VERSION ""

NS_ :

BS_:

BU_:

BO_ 2566565374 HVESP9CFG: 19 Vector__XXX
 SG_ Hvesp9NominalVoltage : 0|16@1+ (0.05,0) [0|3212.75] "V" Vector__XXX
 SG_ Hvesp9CellMaximumVoltageLimit : 112|8@1+ (0.02044,0) [0|5.11] "V" Vector__XXX
 SG_ Hvesp9CellMinimumVoltageLimit : 120|8@1+ (0.02044,0) [0|5.11] "V" Vector__XXX
 SG_ Hvsp9RmmnddMnmmOprtngVltg : 16|16@1+ (0.05,0) [0|3212.75] "V" Vector__XXX
 SG_ Hvsp9RmmnddMxmmOprtngVltg : 32|16@1+ (0.05,0) [0|3212.75] "V" Vector__XXX
 SG_ Hvsp9RmmnddMnmmSttOfChrg : 48|16@1+ (0.0015625,0) [0|100.3984375] "%" Vector__XXX
 SG_ Hvsp9RmmnddMxmmSttOfChrg : 64|16@1+ (0.0015625,0) [0|100.3984375] "%" Vector__XXX
 SG_ Hvsp9RmmnddMxmmOprtngTmprtr : 80|16@1+ (0.03125,-273) [-273|1734.96875] "degC" Vector__XXX
 SG_ Hvsp9RmmnddMnmmOprtngTmprtr : 96|16@1+ (0.03125,-273) [-273|1734.96875] "degC" Vector__XXX

BO_ 2633674494 HVESP9HIST: 19 Vector__XXX
 SG_ Hvesp9StateOfHealth : 0|8@1+ (0.4,0) [0|100] "%" Vector__XXX
 SG_ Hvesp9TotalEnergyThroughput : 24|32@1+ (100,0) [0|421108121500] "Watt-hour" Vector__XXX
 SG_ Hvesp9TotalAccumulatedCharge : 56|32@1+ (100,0) [0|421108121500] "Ah" Vector__XXX
 SG_ Hvesp9TotalLifetimeEnergyInput : 88|32@1+ (1,0) [0|4211081215] "kWh" Vector__XXX
 SG_ Hvesp9TotalLifetimeEnergyOutput : 120|32@1+ (1,0) [0|4211081215] "kWh" Vector__XXX
 SG_ Hvsp9CnttrOpnUndrLdCnt : 8|16@1+ (1,0) [0|64255] "count" Vector__XXX

BO_ 2566565886 HVESP8CFG: 19 Vector__XXX
 SG_ Hvesp8NominalVoltage : 0|16@1+ (0.05,0) [0|3212.75] "V" Vector__XXX
 SG_ Hvesp8CellMaximumVoltageLimit : 112|8@1+ (0.02044,0) [0|5.11] "V" Vector__XXX
 SG_ Hvesp8CellMinimumVoltageLimit : 120|8@1+ (0.02044,0) [0|5.11] "V" Vector__XXX
 SG_ Hvsp8RmmnddMnmmOprtngVltg : 16|16@1+ (0.05,0) [0|3212.75] "V" Vector__XXX
 SG_ Hvsp8RmmnddMxmmOprtngVltg : 32|16@1+ (0.05,0) [0|3212.75] "V" Vector__XXX
 SG_ Hvsp8RmmnddMnmmSttOfChrg : 48|16@1+ (0.0015625,0) [0|100.3984375] "%" Vector__XXX
 SG_ Hvsp8RmmnddMxmmSttOfChrg : 64|16@1+ (0.0015625,0) [0|100.3984375] "%" Vector__XXX
 SG_ Hvsp8RmmnddMxmmOprtngTmprtr : 80|16@1+ (0.03125,-273) [-273|1734.96875] "degC" Vector__XXX
 SG_ Hvsp8RmmnddMnmmOprtngTmprtr : 96|16@1+ (0.03125,-273) [-273|1734.96875] "degC" Vector__XXX

BO_ 2633675006 HVESP8HIST: 19 Vector__XXX
 SG_ Hvesp8StateOfHealth : 0|8@1+ (0.4,0) [0|100] "%" Vector__XXX
 SG_ Hvesp8TotalEnergyThroughput : 24|32@1+ (100,0) [0|421108121500] "Watt-hour" Vector__XXX
 SG_ Hvesp8TotalAccumulatedCharge : 56|32@1+ (100,0) [0|421108121500] "Ah" Vector__XXX
 SG_ Hvesp8TotalLifetimeEnergyInput : 88|32@1+ (1,0) [0|4211081215] "kWh" Vector__XXX
 SG_ Hvesp8TotalLifetimeEnergyOutput : 120|32@1+ (1,0) [0|4211081215] "kWh" Vector__XXX
 SG_ Hvsp8CnttrOpnUndrLdCnt : 8|16@1+ (1,0) [0|64255] "count" Vector__XXX

BO_ 2566566398 HVESP7CFG: 19 Vector__XXX
 SG_ Hvesp7NominalVoltage : 0|16@1+ (0.05,0) [0|3212.75] "V" Vector__XXX
 SG_ Hvesp7CellMaximumVoltageLimit : 112|8@1+ (0.02044,0) [0|5.11] "V" Vector__XXX
 SG_ Hvesp7CellMinimumVoltageLimit : 120|8@1+ (0.02044,0) [0|5.11] "V" Vector__XXX
 SG_ Hvsp7RmmnddMnmmOprtngVltg : 16|16@1+ (0.05,0) [0|3212.75] "V" Vector__XXX
 SG_ Hvsp7RmmnddMxmmOprtngVltg : 32|16@1+ (0.05,0) [0|3212.75] "V" Vector__XXX
 SG_ Hvsp7RmmnddMnmmSttOfChrg : 48|16@1+ (0.0015625,0) [0|100.3984375] "%" Vector__XXX
 SG_ Hvsp7RmmnddMxmmSttOfChrg : 64|16@1+ (0.0015625,0) [0|100.3984375] "%" Vector__XXX
 SG_ Hvsp7RmmnddMxmmOprtngTmprtr : 80|16@1+ (0.03125,-273) [-273|1734.96875] "degC" Vector__XXX
 SG_ Hvsp7RmmnddMnmmOprtngTmprtr : 96|16@1+ (0.03125,-273) [-273|1734.96875] "degC" Vector__XXX

BO_ 2633675518 HVESP7HIST: 19 Vector__XXX
 SG_ Hvesp7StateOfHealth : 0|8@1+ (0.4,0) [0|100] "%" Vector__XXX
 SG_ Hvesp7TotalEnergyThroughput : 24|32@1+ (100,0) [0|421108121500] "Watt-hour" Vector__XXX
 SG_ Hvesp7TotalAccumulatedCharge : 56|32@1+ (100,0) [0|421108121500] "Ah" Vector__XXX
 SG_ Hvesp7TotalLifetimeEnergyInput : 88|32@1+ (1,0) [0|4211081215] "kWh" Vector__XXX
 SG_ Hvesp7TotalLifetimeEnergyOutput : 120|32@1+ (1,0) [0|4211081215] "kWh" Vector__XXX
 SG_ Hvsp7CnttrOpnUndrLdCnt : 8|16@1+ (1,0) [0|64255] "count" Vector__XXX

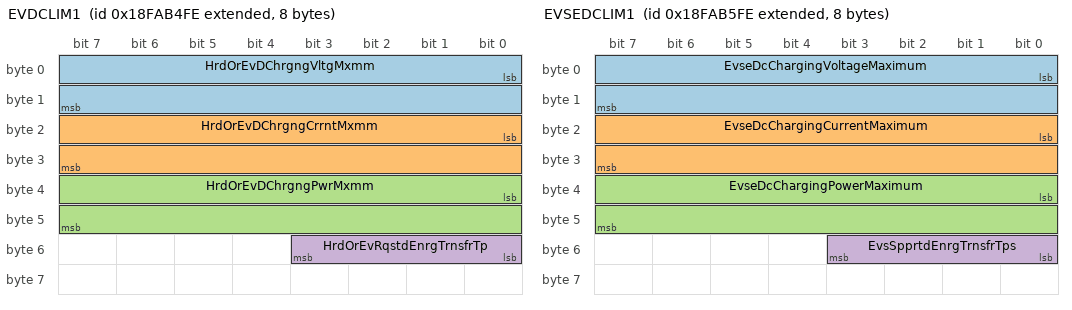
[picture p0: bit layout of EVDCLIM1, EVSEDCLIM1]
BO_ 2566567166 EVDCLIM1: 8 Vector__XXX
 SG_ HrdOrEvDChrgngVltgMxmm : 0|16@1+ (0.05,0) [0|3212.75] "V" Vector__XXX
 SG_ HrdOrEvDChrgngCrrntMxmm : 16|16@1+ (0.0625,0) [0|4015.9375] "A" Vector__XXX
 SG_ HrdOrEvDChrgngPwrMxmm : 32|16@1+ (0.05,0) [0|3212.75] "kW" Vector__XXX
 SG_ HrdOrEvRqstdEnrgTrnsfrTp : 48|4@1+ (1,0) [0|15] "" Vector__XXX

BO_ 2566567422 EVSEDCLIM1: 8 Vector__XXX
 SG_ EvseDcChargingVoltageMaximum : 0|16@1+ (0.05,0) [0|3212.75] "V" Vector__XXX
 SG_ EvseDcChargingCurrentMaximum : 16|16@1+ (0.0625,0) [0|4015.9375] "A" Vector__XXX
 SG_ EvseDcChargingPowerMaximum : 32|16@1+ (0.05,0) [0|3212.75] "kW" Vector__XXX
 SG_ EvsSpprtdEnrgTrnsfrTps : 48|4@1+ (1,0) [0|15] "" Vector__XXX

BO_ 2566567678 EVSEDCLIM2: 8 Vector__XXX
 SG_ EvseDcChargingVoltageMinimum : 0|16@1+ (0.05,0) [0|3212.75] "V" Vector__XXX
 SG_ EvseDcChargingCurrentMinimum : 16|16@1+ (0.0625,0) [0|4015.9375] "A" Vector__XXX
 SG_ EvsePeakCurrentRipple : 32|16@1+ (0.0625,0) [0|4015.9375] "A" Vector__XXX
 SG_ EvseCurrentRegulationTolerance : 48|16@1+ (0.0625,0) [0|4015.9375] "A" Vector__XXX

BO_ 2566567934 EVDCTGT: 8 Vector__XXX
 SG_ DcChargingTargetCrc : 0|8@1+ (1,0) [0|250] "count" Vector__XXX
 SG_ DcChargingTargetSequenceCounter : 8|4@1+ (1,0) [0|15] "" Vector__XXX
 SG_ DcTargetChargingVoltage : 16|16@1+ (0.05,0) [0|3212.75] "V" Vector__XXX
 SG_ DcTargetChargingCurrent : 32|16@1+ (0.0625,0) [0|4015.9375] "A" Vector__XXX

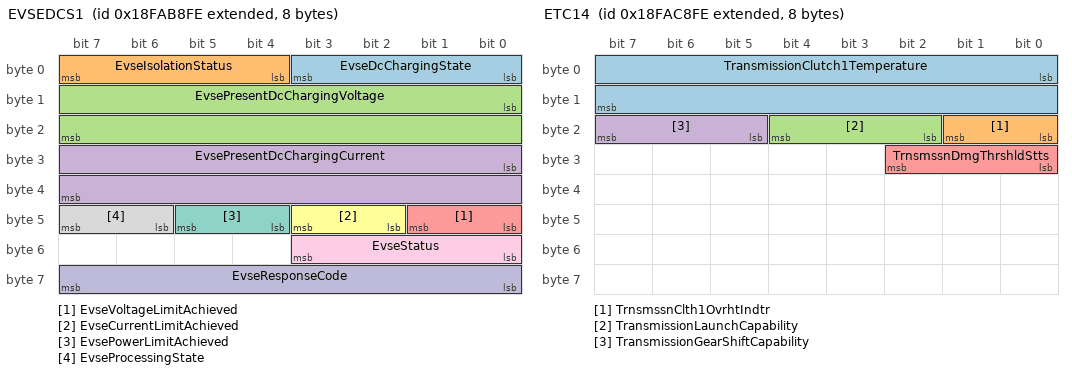
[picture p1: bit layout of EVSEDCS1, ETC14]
BO_ 2566568190 EVSEDCS1: 8 Vector__XXX
 SG_ EvseDcChargingState : 0|4@1+ (1,0) [0|15] "" Vector__XXX
 SG_ EvseIsolationStatus : 4|4@1+ (1,0) [0|15] "" Vector__XXX
 SG_ EvsePresentDcChargingVoltage : 8|16@1+ (0.05,0) [0|3212.75] "V" Vector__XXX
 SG_ EvsePresentDcChargingCurrent : 24|16@1+ (0.05,-1600) [-1600|1612.75] "A" Vector__XXX
 SG_ EvseVoltageLimitAchieved : 40|2@1+ (1,0) [0|3] "" Vector__XXX
 SG_ EvseCurrentLimitAchieved : 42|2@1+ (1,0) [0|3] "" Vector__XXX
 SG_ EvsePowerLimitAchieved : 44|2@1+ (1,0) [0|3] "" Vector__XXX
 SG_ EvseProcessingState : 46|2@1+ (1,0) [0|3] "" Vector__XXX
 SG_ EvseStatus : 48|4@1+ (1,0) [0|15] "" Vector__XXX
 SG_ EvseResponseCode : 56|8@1+ (1,0) [0|250] "" Vector__XXX

BO_ 2566568446 EVSE1CC1: 8 Vector__XXX
 SG_ HrdOrEvDInltCnttr1Cmmnd : 0|2@1+ (1,0) [0|3] "" Vector__XXX

BO_ 2566568702 EVSE1CS1: 8 Vector__XXX
 SG_ HrdOrEvDCnttrInptVltg : 0|16@1+ (0.05,0) [0|3212.75] "V" Vector__XXX
 SG_ HybridOrEvDcChargingBusVoltage : 16|16@1+ (0.05,0) [0|3212.75] "V" Vector__XXX
 SG_ HrdOrEvDInltCnttr1Stt : 32|2@1+ (1,0) [0|3] "" Vector__XXX

BO_ 2566568958 DLCC3: 8 Vector__XXX
 SG_ TrnsmssnOlTmprtrHghLmpCmmnd : 0|2@1+ (1,0) [0|3] "" Vector__XXX
 SG_ TrnsmssnOlPrssrLwLmpCmmnd : 2|2@1+ (1,0) [0|3] "" Vector__XXX

BO_ 2566569214 DLCD3: 8 Vector__XXX
 SG_ TrnsmssnOlTmprtrHghLmpDt : 0|2@1+ (1,0) [0|3] "" Vector__XXX
 SG_ TrnsmssnOlPrssrLwLmpDt : 2|2@1+ (1,0) [0|3] "" Vector__XXX

BO_ 2566569470 MG1LD: 16 Vector__XXX
 SG_ MtrGnrtr1TtlEnrgCnsmd : 0|32@1+ (100,0) [0|421108121500] "Watt-hour" Vector__XXX
 SG_ MtrGnrtr1TtlEnrgGnrtd : 32|32@1+ (100,0) [0|421108121500] "Watt-hour" Vector__XXX
 SG_ MtrGnrtr1TtlChrgCnsmd : 64|32@1+ (100,0) [0|421108121500] "Ah" Vector__XXX
 SG_ MtrGnrtr1TtlChrgGnrtd : 96|32@1+ (100,0) [0|421108121500] "Ah" Vector__XXX

BO_ 2566569726 MG2LD: 16 Vector__XXX
 SG_ MtrGnrtr2TtlEnrgCnsmd : 0|32@1+ (100,0) [0|421108121500] "Watt-hour" Vector__XXX
 SG_ MtrGnrtr2TtlEnrgGnrtd : 32|32@1+ (100,0) [0|421108121500] "Watt-hour" Vector__XXX
 SG_ MtrGnrtr2TtlChrgCnsmd : 64|32@1+ (100,0) [0|421108121500] "Ah" Vector__XXX
 SG_ MtrGnrtr2TtlChrgGnrtd : 96|32@1+ (100,0) [0|421108121500] "Ah" Vector__XXX

BO_ 2566569982 MG3LD: 16 Vector__XXX
 SG_ MtrGnrtr3TtlEnrgCnsmd : 0|32@1+ (100,0) [0|421108121500] "Watt-hour" Vector__XXX
 SG_ MtrGnrtr3TtlEnrgGnrtd : 32|32@1+ (100,0) [0|421108121500] "Watt-hour" Vector__XXX
 SG_ MtrGnrtr3TtlChrgCnsmd : 64|32@1+ (100,0) [0|421108121500] "Ah" Vector__XXX
 SG_ MtrGnrtr3TtlChrgGnrtd : 96|32@1+ (100,0) [0|421108121500] "Ah" Vector__XXX

BO_ 2566570238 MG4LD: 16 Vector__XXX
 SG_ MtrGnrtr4TtlEnrgCnsmd : 0|32@1+ (100,0) [0|421108121500] "Watt-hour" Vector__XXX
 SG_ MtrGnrtr4TtlEnrgGnrtd : 32|32@1+ (100,0) [0|421108121500] "Watt-hour" Vector__XXX
 SG_ MtrGnrtr4TtlChrgCnsmd : 64|32@1+ (100,0) [0|421108121500] "Ah" Vector__XXX
 SG_ MtrGnrtr4TtlChrgGnrtd : 96|32@1+ (100,0) [0|421108121500] "Ah" Vector__XXX

BO_ 2566570494 MG5LD: 16 Vector__XXX
 SG_ MtrGnrtr5TtlEnrgCnsmd : 0|32@1+ (100,0) [0|421108121500] "Watt-hour" Vector__XXX
 SG_ MtrGnrtr5TtlEnrgGnrtd : 32|32@1+ (100,0) [0|421108121500] "Watt-hour" Vector__XXX
 SG_ MtrGnrtr5TtlChrgCnsmd : 64|32@1+ (100,0) [0|421108121500] "Ah" Vector__XXX
 SG_ MtrGnrtr5TtlChrgGnrtd : 96|32@1+ (100,0) [0|421108121500] "Ah" Vector__XXX

BO_ 2566570750 MG6LD: 16 Vector__XXX
 SG_ MtrGnrtr6TtlEnrgCnsmd : 0|32@1+ (100,0) [0|421108121500] "Watt-hour" Vector__XXX
 SG_ MtrGnrtr6TtlEnrgGnrtd : 32|32@1+ (100,0) [0|421108121500] "Watt-hour" Vector__XXX
 SG_ MtrGnrtr6TtlChrgCnsmd : 64|32@1+ (100,0) [0|421108121500] "Ah" Vector__XXX
 SG_ MtrGnrtr6TtlChrgGnrtd : 96|32@1+ (100,0) [0|421108121500] "Ah" Vector__XXX

BO_ 2566571006 AIR3: 8 Vector__XXX
 SG_ AirDryerCartridgeLifeRemaining : 0|8@1+ (0.4,0) [0|100] "%" Vector__XXX
 SG_ AirSuspensionSupplyPressure2 : 8|8@1+ (8,0) [0|2000] "kPa" Vector__XXX

BO_ 2566571262 EVSEACSV: 8 Vector__XXX
 SG_ EvseNominalRmsVoltageLineToLine : 16|16@1+ (0.05,0) [0|3212.75] "V" Vector__XXX
 SG_ EvseNominalSupplyFrequency : 32|8@1+ (1,0) [0|250] "" Vector__XXX
 SG_ EvsNmnlRmsVltgLnTNtrl : 0|16@1+ (0.05,0) [0|3212.75] "V" Vector__XXX

BO_ 2566571518 EVSEAC3PL: 8 Vector__XXX
 SG_ HvessChargerRmsCurrentL1 : 0|16@1+ (0.0625,0) [0|4015.9375] "A" Vector__XXX
 SG_ HvessChargerRmsCurrentL2 : 16|16@1+ (0.0625,0) [0|4015.9375] "A" Vector__XXX
 SG_ HvessChargerRmsCurrentL3 : 32|16@1+ (0.0625,0) [0|4015.9375] "A" Vector__XXX
 SG_ HvessChargerNeutralRmsCurrent : 48|16@1+ (0.0625,0) [0|4015.9375] "A" Vector__XXX

BO_ 2499462910 ERC3: 8 Vector__XXX
 SG_ RtrdrRdSpdDlrtSwth : 0|2@1+ (1,0) [0|3] "" Vector__XXX
 SG_ RtrdrRdSpdAlrtSwth : 2|2@1+ (1,0) [0|3] "" Vector__XXX

BO_ 2566572286 ETC14: 8 Vector__XXX
 SG_ TransmissionClutch1Temperature : 0|16@1+ (0.03125,-273) [-273|1734.96875] "degC" Vector__XXX
 SG_ TrnsmssnClth1OvrhtIndtr : 16|2@1+ (1,0) [0|3] "" Vector__XXX
 SG_ TransmissionLaunchCapability : 18|3@1+ (1,0) [0|7] "" Vector__XXX
 SG_ TransmissionGearShiftCapability : 21|3@1+ (1,0) [0|7] "" Vector__XXX
 SG_ TrnsmssnDmgThrshldStts : 24|3@1+ (1,0) [0|7] "" Vector__XXX

BO_ 2499464702 A1SCREGP2: 8 Vector__XXX
 SG_ Aftrtrtmnt1SrOtltAsltPrssr : 0|16@1+ (0.1,0) [0|6425.5] "kPa" Vector__XXX
 SG_ Aftrtrtmnt1SrOtltPrssr : 16|16@1+ (0.1,0) [0|6425.5] "kPa" Vector__XXX

BO_ 2566573822 PTO2: 8 Vector__XXX
 SG_ TransmissionPtoGearboxStatus : 16|4@1+ (1,0) [0|15] "" Vector__XXX
 SG_ TrnsmssnPtGrxOtptShftSpd : 0|16@1+ (0.125,0) [0|8031.875] "rpm" Vector__XXX

BO_ 2364690686 EATC1: 8 Vector__XXX
 SG_ AxlrTrnsmssnOtptSpd : 0|16@1+ (0.125,0) [0|8031.875] "rpm" Vector__XXX

BO_ 2566563326 DFM3: 8 Vector__XXX
 SG_ BddDFMdEsttdIsttsFSvsRt : 0|16@1+ (0.05,0) [0|3212.75] "l/h" Vector__XXX
 SG_ BlnddDlFlMdOprtngStts : 16|4@1+ (1,0) [0|15] "" Vector__XXX
 SG_ BlendedDualFuelModeStatusReason : 24|8@1+ (1,0) [0|250] "" Vector__XXX

BO_ 2566563582 DFM2: 8 Vector__XXX
 SG_ BlnddDlFlMdTtlDslFlDmnd : 32|32@1+ (0.5,0) [0|2105540607.5] "l" Vector__XXX
 SG_ BlnddDlFlMdTtlDslFlDspldBGssFl : 0|32@1+ (0.5,0) [0|2105540607.5] "l" Vector__XXX

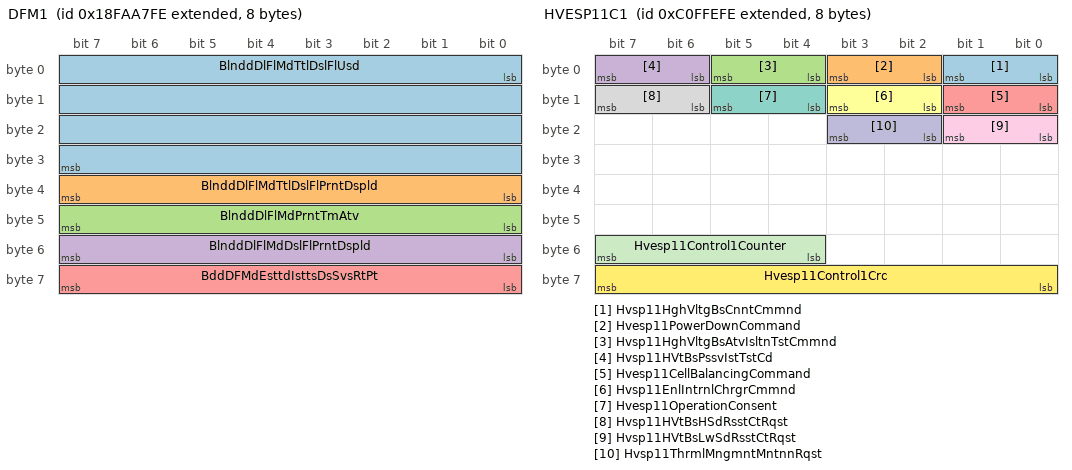
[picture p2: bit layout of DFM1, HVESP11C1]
BO_ 2566563838 DFM1: 8 Vector__XXX
 SG_ BlnddDlFlMdTtlDslFlUsd : 0|32@1+ (0.5,0) [0|2105540607.5] "l" Vector__XXX
 SG_ BlnddDlFlMdTtlDslFlPrntDspld : 32|8@1+ (0.5,0) [0|125] "%" Vector__XXX
 SG_ BlnddDlFlMdPrntTmAtv : 40|8@1+ (0.4,0) [0|100] "%" Vector__XXX
 SG_ BlnddDlFlMdDslFlPrntDspld : 48|8@1+ (0.4,0) [0|100] "%" Vector__XXX
 SG_ BddDFMdEsttdIsttsDsSvsRtPt : 56|8@1+ (0.4,0) [0|100] "%" Vector__XXX

BO_ 2566564094 T1HIST: 12 Vector__XXX
 SG_ Trnsmssn1TtlOtptShftRvltns : 32|32@1+ (1000,0) [0|4211081215000] "r" Vector__XXX
 SG_ Trnsmssn1OprtnTmSnRld : 64|32@1+ (1,0) [0|4211081215] "s" Vector__XXX
 SG_ Trnsmssn1TtlHrsOfOprtn : 0|32@1+ (1,0) [0|4211081215] "s" Vector__XXX

BO_ 2566564350 TSTI: 8 Vector__XXX
 SG_ Trnsmssn1InptShftPkTwst : 0|8@1+ (0.1,-12.5) [-12.5|12.5] "deg" Vector__XXX
 SG_ Trnsmssn1OtptShftPkTwst : 8|8@1+ (0.1,-12.5) [-12.5|12.5] "deg" Vector__XXX
 SG_ Trnsmssn1IntrmdtShftPkTwst : 16|8@1+ (0.1,-12.5) [-12.5|12.5] "deg" Vector__XXX

BO_ 2566564606 EATC2: 8 Vector__XXX
 SG_ AxlrTrnsmssnSltdGr : 0|8@1+ (1,-125) [-125|125] "gear value" Vector__XXX
 SG_ AxlrTrnsmssnCrrntGr : 8|8@1+ (1,-125) [-125|125] "gear value" Vector__XXX

BO_ 2349858558 HVESP11C1: 8 Vector__XXX
 SG_ Hvsp11HghVltgBsCnntCmmnd : 0|2@1+ (1,0) [0|3] "" Vector__XXX
 SG_ Hvesp11PowerDownCommand : 2|2@1+ (1,0) [0|3] "" Vector__XXX
 SG_ Hvsp11HghVltgBsAtvIsltnTstCmmnd : 4|2@1+ (1,0) [0|3] "" Vector__XXX
 SG_ Hvsp11HVtBsPssvIstTstCd : 6|2@1+ (1,0) [0|3] "" Vector__XXX
 SG_ Hvesp11CellBalancingCommand : 8|2@1+ (1,0) [0|3] "" Vector__XXX
 SG_ Hvsp11EnlIntrnlChrgrCmmnd : 10|2@1+ (1,0) [0|3] "" Vector__XXX
 SG_ Hvesp11OperationConsent : 12|2@1+ (1,0) [0|3] "" Vector__XXX
 SG_ Hvsp11HVtBsHSdRsstCtRqst : 14|2@1+ (1,0) [0|3] "" Vector__XXX
 SG_ Hvsp11HVtBsLwSdRsstCtRqst : 16|2@1+ (1,0) [0|3] "" Vector__XXX
 SG_ Hvsp11ThrmlMngmntMntnnRqst : 18|2@1+ (1,0) [0|3] "" Vector__XXX
 SG_ Hvesp11Control1Counter : 52|4@1+ (1,0) [0|15] "" Vector__XXX
 SG_ Hvesp11Control1Crc : 56|8@1+ (1,0) [0|250] "count" Vector__XXX

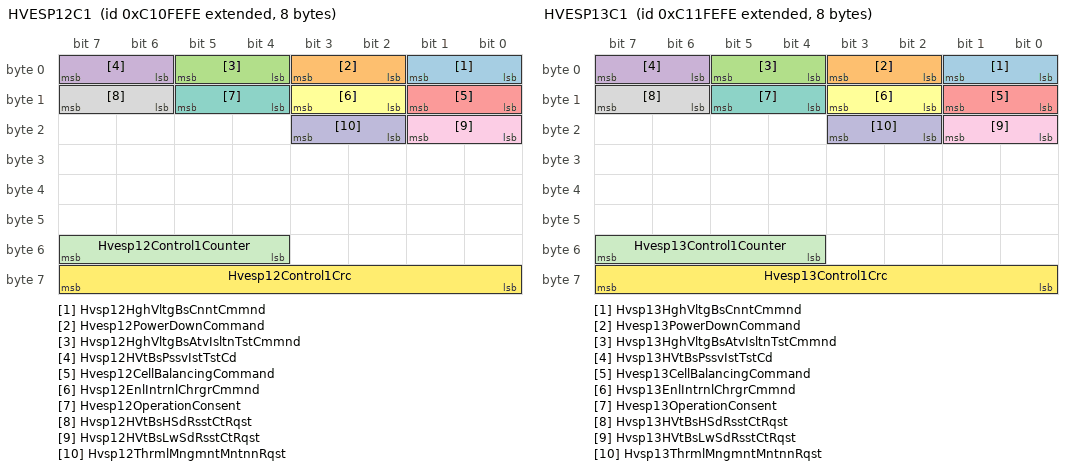
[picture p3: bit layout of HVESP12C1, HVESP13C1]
BO_ 2349924094 HVESP12C1: 8 Vector__XXX
 SG_ Hvsp12HghVltgBsCnntCmmnd : 0|2@1+ (1,0) [0|3] "" Vector__XXX
 SG_ Hvesp12PowerDownCommand : 2|2@1+ (1,0) [0|3] "" Vector__XXX
 SG_ Hvsp12HghVltgBsAtvIsltnTstCmmnd : 4|2@1+ (1,0) [0|3] "" Vector__XXX
 SG_ Hvsp12HVtBsPssvIstTstCd : 6|2@1+ (1,0) [0|3] "" Vector__XXX
 SG_ Hvesp12CellBalancingCommand : 8|2@1+ (1,0) [0|3] "" Vector__XXX
 SG_ Hvsp12EnlIntrnlChrgrCmmnd : 10|2@1+ (1,0) [0|3] "" Vector__XXX
 SG_ Hvesp12OperationConsent : 12|2@1+ (1,0) [0|3] "" Vector__XXX
 SG_ Hvsp12HVtBsHSdRsstCtRqst : 14|2@1+ (1,0) [0|3] "" Vector__XXX
 SG_ Hvsp12HVtBsLwSdRsstCtRqst : 16|2@1+ (1,0) [0|3] "" Vector__XXX
 SG_ Hvsp12ThrmlMngmntMntnnRqst : 18|2@1+ (1,0) [0|3] "" Vector__XXX
 SG_ Hvesp12Control1Counter : 52|4@1+ (1,0) [0|15] "" Vector__XXX
 SG_ Hvesp12Control1Crc : 56|8@1+ (1,0) [0|250] "count" Vector__XXX

BO_ 2349989630 HVESP13C1: 8 Vector__XXX
 SG_ Hvsp13HghVltgBsCnntCmmnd : 0|2@1+ (1,0) [0|3] "" Vector__XXX
 SG_ Hvesp13PowerDownCommand : 2|2@1+ (1,0) [0|3] "" Vector__XXX
 SG_ Hvsp13HghVltgBsAtvIsltnTstCmmnd : 4|2@1+ (1,0) [0|3] "" Vector__XXX
 SG_ Hvsp13HVtBsPssvIstTstCd : 6|2@1+ (1,0) [0|3] "" Vector__XXX
 SG_ Hvesp13CellBalancingCommand : 8|2@1+ (1,0) [0|3] "" Vector__XXX
 SG_ Hvsp13EnlIntrnlChrgrCmmnd : 10|2@1+ (1,0) [0|3] "" Vector__XXX
 SG_ Hvesp13OperationConsent : 12|2@1+ (1,0) [0|3] "" Vector__XXX
 SG_ Hvsp13HVtBsHSdRsstCtRqst : 14|2@1+ (1,0) [0|3] "" Vector__XXX
 SG_ Hvsp13HVtBsLwSdRsstCtRqst : 16|2@1+ (1,0) [0|3] "" Vector__XXX
 SG_ Hvsp13ThrmlMngmntMntnnRqst : 18|2@1+ (1,0) [0|3] "" Vector__XXX
 SG_ Hvesp13Control1Counter : 52|4@1+ (1,0) [0|15] "" Vector__XXX
 SG_ Hvesp13Control1Crc : 56|8@1+ (1,0) [0|250] "count" Vector__XXX

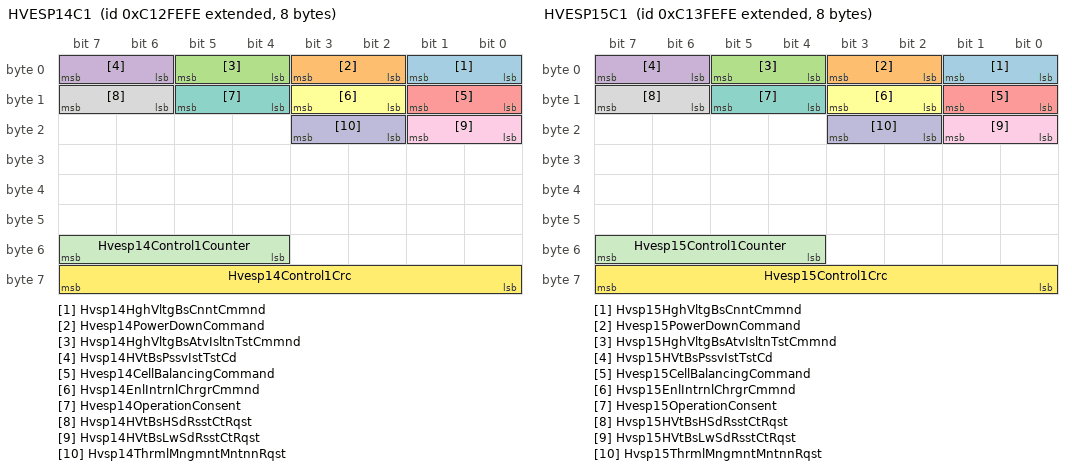
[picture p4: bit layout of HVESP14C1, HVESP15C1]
BO_ 2350055166 HVESP14C1: 8 Vector__XXX
 SG_ Hvsp14HghVltgBsCnntCmmnd : 0|2@1+ (1,0) [0|3] "" Vector__XXX
 SG_ Hvesp14PowerDownCommand : 2|2@1+ (1,0) [0|3] "" Vector__XXX
 SG_ Hvsp14HghVltgBsAtvIsltnTstCmmnd : 4|2@1+ (1,0) [0|3] "" Vector__XXX
 SG_ Hvsp14HVtBsPssvIstTstCd : 6|2@1+ (1,0) [0|3] "" Vector__XXX
 SG_ Hvesp14CellBalancingCommand : 8|2@1+ (1,0) [0|3] "" Vector__XXX
 SG_ Hvsp14EnlIntrnlChrgrCmmnd : 10|2@1+ (1,0) [0|3] "" Vector__XXX
 SG_ Hvesp14OperationConsent : 12|2@1+ (1,0) [0|3] "" Vector__XXX
 SG_ Hvsp14HVtBsHSdRsstCtRqst : 14|2@1+ (1,0) [0|3] "" Vector__XXX
 SG_ Hvsp14HVtBsLwSdRsstCtRqst : 16|2@1+ (1,0) [0|3] "" Vector__XXX
 SG_ Hvsp14ThrmlMngmntMntnnRqst : 18|2@1+ (1,0) [0|3] "" Vector__XXX
 SG_ Hvesp14Control1Counter : 52|4@1+ (1,0) [0|15] "" Vector__XXX
 SG_ Hvesp14Control1Crc : 56|8@1+ (1,0) [0|250] "count" Vector__XXX

BO_ 2350120702 HVESP15C1: 8 Vector__XXX
 SG_ Hvsp15HghVltgBsCnntCmmnd : 0|2@1+ (1,0) [0|3] "" Vector__XXX
 SG_ Hvesp15PowerDownCommand : 2|2@1+ (1,0) [0|3] "" Vector__XXX
 SG_ Hvsp15HghVltgBsAtvIsltnTstCmmnd : 4|2@1+ (1,0) [0|3] "" Vector__XXX
 SG_ Hvsp15HVtBsPssvIstTstCd : 6|2@1+ (1,0) [0|3] "" Vector__XXX
 SG_ Hvesp15CellBalancingCommand : 8|2@1+ (1,0) [0|3] "" Vector__XXX
 SG_ Hvsp15EnlIntrnlChrgrCmmnd : 10|2@1+ (1,0) [0|3] "" Vector__XXX
 SG_ Hvesp15OperationConsent : 12|2@1+ (1,0) [0|3] "" Vector__XXX
 SG_ Hvsp15HVtBsHSdRsstCtRqst : 14|2@1+ (1,0) [0|3] "" Vector__XXX
 SG_ Hvsp15HVtBsLwSdRsstCtRqst : 16|2@1+ (1,0) [0|3] "" Vector__XXX
 SG_ Hvsp15ThrmlMngmntMntnnRqst : 18|2@1+ (1,0) [0|3] "" Vector__XXX
 SG_ Hvesp15Control1Counter : 52|4@1+ (1,0) [0|15] "" Vector__XXX
 SG_ Hvesp15Control1Crc : 56|8@1+ (1,0) [0|250] "count" Vector__XXX

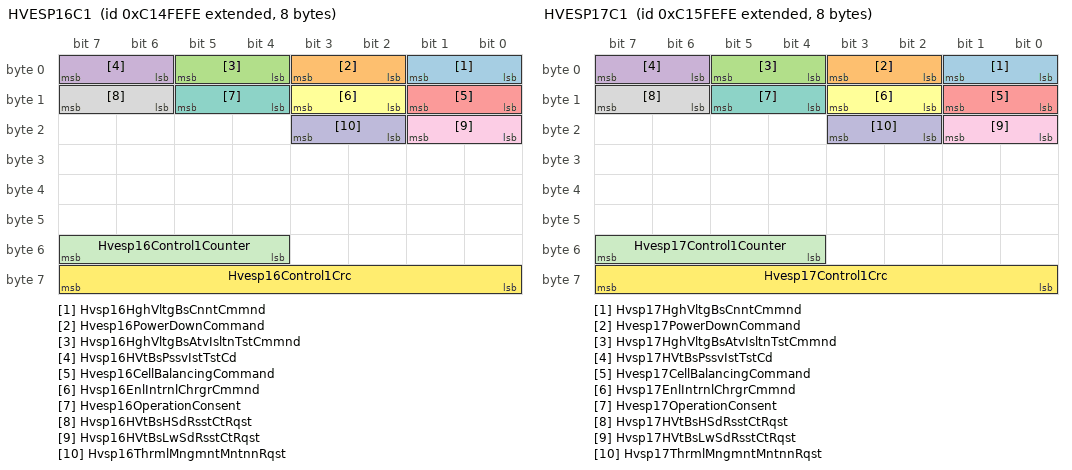
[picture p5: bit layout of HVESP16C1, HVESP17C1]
BO_ 2350186238 HVESP16C1: 8 Vector__XXX
 SG_ Hvsp16HghVltgBsCnntCmmnd : 0|2@1+ (1,0) [0|3] "" Vector__XXX
 SG_ Hvesp16PowerDownCommand : 2|2@1+ (1,0) [0|3] "" Vector__XXX
 SG_ Hvsp16HghVltgBsAtvIsltnTstCmmnd : 4|2@1+ (1,0) [0|3] "" Vector__XXX
 SG_ Hvsp16HVtBsPssvIstTstCd : 6|2@1+ (1,0) [0|3] "" Vector__XXX
 SG_ Hvesp16CellBalancingCommand : 8|2@1+ (1,0) [0|3] "" Vector__XXX
 SG_ Hvsp16EnlIntrnlChrgrCmmnd : 10|2@1+ (1,0) [0|3] "" Vector__XXX
 SG_ Hvesp16OperationConsent : 12|2@1+ (1,0) [0|3] "" Vector__XXX
 SG_ Hvsp16HVtBsHSdRsstCtRqst : 14|2@1+ (1,0) [0|3] "" Vector__XXX
 SG_ Hvsp16HVtBsLwSdRsstCtRqst : 16|2@1+ (1,0) [0|3] "" Vector__XXX
 SG_ Hvsp16ThrmlMngmntMntnnRqst : 18|2@1+ (1,0) [0|3] "" Vector__XXX
 SG_ Hvesp16Control1Counter : 52|4@1+ (1,0) [0|15] "" Vector__XXX
 SG_ Hvesp16Control1Crc : 56|8@1+ (1,0) [0|250] "count" Vector__XXX

BO_ 2350251774 HVESP17C1: 8 Vector__XXX
 SG_ Hvsp17HghVltgBsCnntCmmnd : 0|2@1+ (1,0) [0|3] "" Vector__XXX
 SG_ Hvesp17PowerDownCommand : 2|2@1+ (1,0) [0|3] "" Vector__XXX
 SG_ Hvsp17HghVltgBsAtvIsltnTstCmmnd : 4|2@1+ (1,0) [0|3] "" Vector__XXX
 SG_ Hvsp17HVtBsPssvIstTstCd : 6|2@1+ (1,0) [0|3] "" Vector__XXX
 SG_ Hvesp17CellBalancingCommand : 8|2@1+ (1,0) [0|3] "" Vector__XXX
 SG_ Hvsp17EnlIntrnlChrgrCmmnd : 10|2@1+ (1,0) [0|3] "" Vector__XXX
 SG_ Hvesp17OperationConsent : 12|2@1+ (1,0) [0|3] "" Vector__XXX
 SG_ Hvsp17HVtBsHSdRsstCtRqst : 14|2@1+ (1,0) [0|3] "" Vector__XXX
 SG_ Hvsp17HVtBsLwSdRsstCtRqst : 16|2@1+ (1,0) [0|3] "" Vector__XXX
 SG_ Hvsp17ThrmlMngmntMntnnRqst : 18|2@1+ (1,0) [0|3] "" Vector__XXX
 SG_ Hvesp17Control1Counter : 52|4@1+ (1,0) [0|15] "" Vector__XXX
 SG_ Hvesp17Control1Crc : 56|8@1+ (1,0) [0|250] "count" Vector__XXX

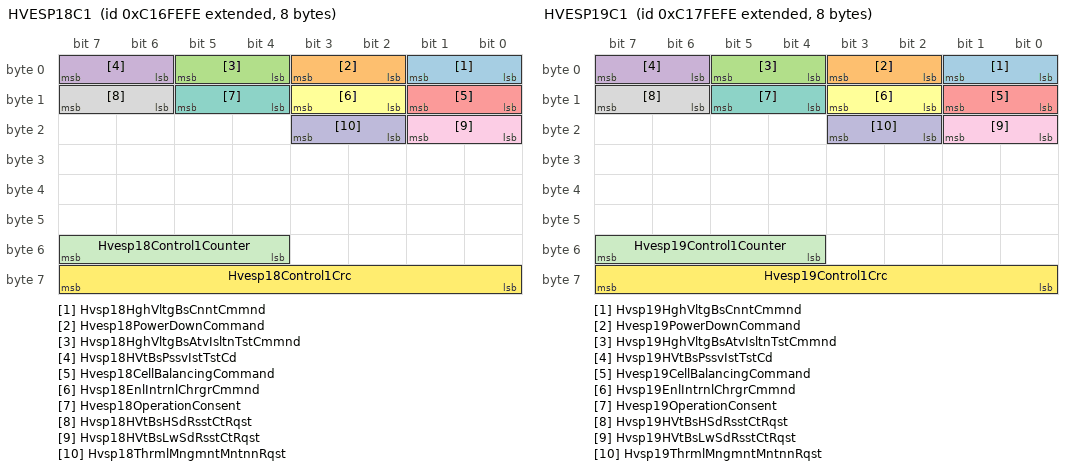
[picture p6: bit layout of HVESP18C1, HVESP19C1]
BO_ 2350317310 HVESP18C1: 8 Vector__XXX
 SG_ Hvsp18HghVltgBsCnntCmmnd : 0|2@1+ (1,0) [0|3] "" Vector__XXX
 SG_ Hvesp18PowerDownCommand : 2|2@1+ (1,0) [0|3] "" Vector__XXX
 SG_ Hvsp18HghVltgBsAtvIsltnTstCmmnd : 4|2@1+ (1,0) [0|3] "" Vector__XXX
 SG_ Hvsp18HVtBsPssvIstTstCd : 6|2@1+ (1,0) [0|3] "" Vector__XXX
 SG_ Hvesp18CellBalancingCommand : 8|2@1+ (1,0) [0|3] "" Vector__XXX
 SG_ Hvsp18EnlIntrnlChrgrCmmnd : 10|2@1+ (1,0) [0|3] "" Vector__XXX
 SG_ Hvesp18OperationConsent : 12|2@1+ (1,0) [0|3] "" Vector__XXX
 SG_ Hvsp18HVtBsHSdRsstCtRqst : 14|2@1+ (1,0) [0|3] "" Vector__XXX
 SG_ Hvsp18HVtBsLwSdRsstCtRqst : 16|2@1+ (1,0) [0|3] "" Vector__XXX
 SG_ Hvsp18ThrmlMngmntMntnnRqst : 18|2@1+ (1,0) [0|3] "" Vector__XXX
 SG_ Hvesp18Control1Counter : 52|4@1+ (1,0) [0|15] "" Vector__XXX
 SG_ Hvesp18Control1Crc : 56|8@1+ (1,0) [0|250] "count" Vector__XXX

BO_ 2350382846 HVESP19C1: 8 Vector__XXX
 SG_ Hvsp19HghVltgBsCnntCmmnd : 0|2@1+ (1,0) [0|3] "" Vector__XXX
 SG_ Hvesp19PowerDownCommand : 2|2@1+ (1,0) [0|3] "" Vector__XXX
 SG_ Hvsp19HghVltgBsAtvIsltnTstCmmnd : 4|2@1+ (1,0) [0|3] "" Vector__XXX
 SG_ Hvsp19HVtBsPssvIstTstCd : 6|2@1+ (1,0) [0|3] "" Vector__XXX
 SG_ Hvesp19CellBalancingCommand : 8|2@1+ (1,0) [0|3] "" Vector__XXX
 SG_ Hvsp19EnlIntrnlChrgrCmmnd : 10|2@1+ (1,0) [0|3] "" Vector__XXX
 SG_ Hvesp19OperationConsent : 12|2@1+ (1,0) [0|3] "" Vector__XXX
 SG_ Hvsp19HVtBsHSdRsstCtRqst : 14|2@1+ (1,0) [0|3] "" Vector__XXX
 SG_ Hvsp19HVtBsLwSdRsstCtRqst : 16|2@1+ (1,0) [0|3] "" Vector__XXX
 SG_ Hvsp19ThrmlMngmntMntnnRqst : 18|2@1+ (1,0) [0|3] "" Vector__XXX
 SG_ Hvesp19Control1Counter : 52|4@1+ (1,0) [0|15] "" Vector__XXX
 SG_ Hvesp19Control1Crc : 56|8@1+ (1,0) [0|250] "count" Vector__XXX

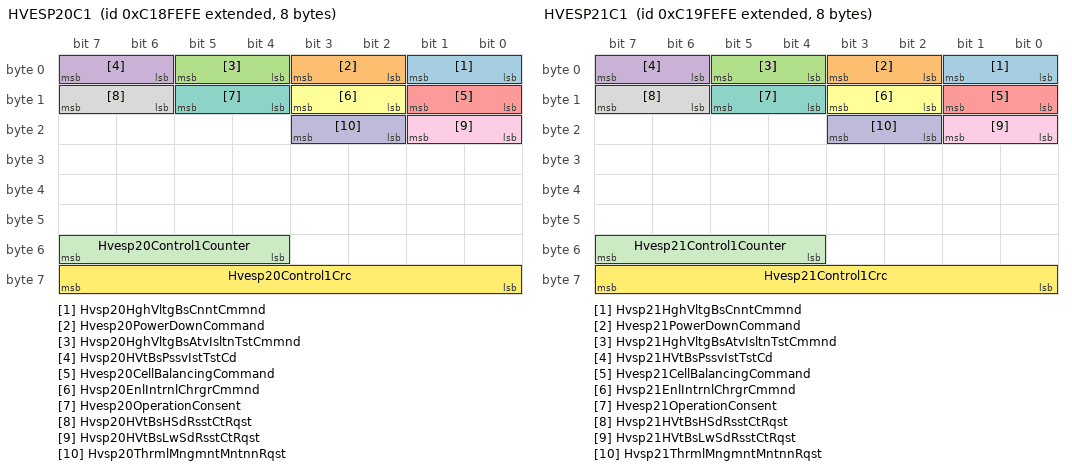
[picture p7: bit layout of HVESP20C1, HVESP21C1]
BO_ 2350448382 HVESP20C1: 8 Vector__XXX
 SG_ Hvsp20HghVltgBsCnntCmmnd : 0|2@1+ (1,0) [0|3] "" Vector__XXX
 SG_ Hvesp20PowerDownCommand : 2|2@1+ (1,0) [0|3] "" Vector__XXX
 SG_ Hvsp20HghVltgBsAtvIsltnTstCmmnd : 4|2@1+ (1,0) [0|3] "" Vector__XXX
 SG_ Hvsp20HVtBsPssvIstTstCd : 6|2@1+ (1,0) [0|3] "" Vector__XXX
 SG_ Hvesp20CellBalancingCommand : 8|2@1+ (1,0) [0|3] "" Vector__XXX
 SG_ Hvsp20EnlIntrnlChrgrCmmnd : 10|2@1+ (1,0) [0|3] "" Vector__XXX
 SG_ Hvesp20OperationConsent : 12|2@1+ (1,0) [0|3] "" Vector__XXX
 SG_ Hvsp20HVtBsHSdRsstCtRqst : 14|2@1+ (1,0) [0|3] "" Vector__XXX
 SG_ Hvsp20HVtBsLwSdRsstCtRqst : 16|2@1+ (1,0) [0|3] "" Vector__XXX
 SG_ Hvsp20ThrmlMngmntMntnnRqst : 18|2@1+ (1,0) [0|3] "" Vector__XXX
 SG_ Hvesp20Control1Counter : 52|4@1+ (1,0) [0|15] "" Vector__XXX
 SG_ Hvesp20Control1Crc : 56|8@1+ (1,0) [0|250] "count" Vector__XXX

BO_ 2350513918 HVESP21C1: 8 Vector__XXX
 SG_ Hvsp21HghVltgBsCnntCmmnd : 0|2@1+ (1,0) [0|3] "" Vector__XXX
 SG_ Hvesp21PowerDownCommand : 2|2@1+ (1,0) [0|3] "" Vector__XXX
 SG_ Hvsp21HghVltgBsAtvIsltnTstCmmnd : 4|2@1+ (1,0) [0|3] "" Vector__XXX
 SG_ Hvsp21HVtBsPssvIstTstCd : 6|2@1+ (1,0) [0|3] "" Vector__XXX
 SG_ Hvesp21CellBalancingCommand : 8|2@1+ (1,0) [0|3] "" Vector__XXX
 SG_ Hvsp21EnlIntrnlChrgrCmmnd : 10|2@1+ (1,0) [0|3] "" Vector__XXX
 SG_ Hvesp21OperationConsent : 12|2@1+ (1,0) [0|3] "" Vector__XXX
 SG_ Hvsp21HVtBsHSdRsstCtRqst : 14|2@1+ (1,0) [0|3] "" Vector__XXX
 SG_ Hvsp21HVtBsLwSdRsstCtRqst : 16|2@1+ (1,0) [0|3] "" Vector__XXX
 SG_ Hvsp21ThrmlMngmntMntnnRqst : 18|2@1+ (1,0) [0|3] "" Vector__XXX
 SG_ Hvesp21Control1Counter : 52|4@1+ (1,0) [0|15] "" Vector__XXX
 SG_ Hvesp21Control1Crc : 56|8@1+ (1,0) [0|250] "count" Vector__XXX

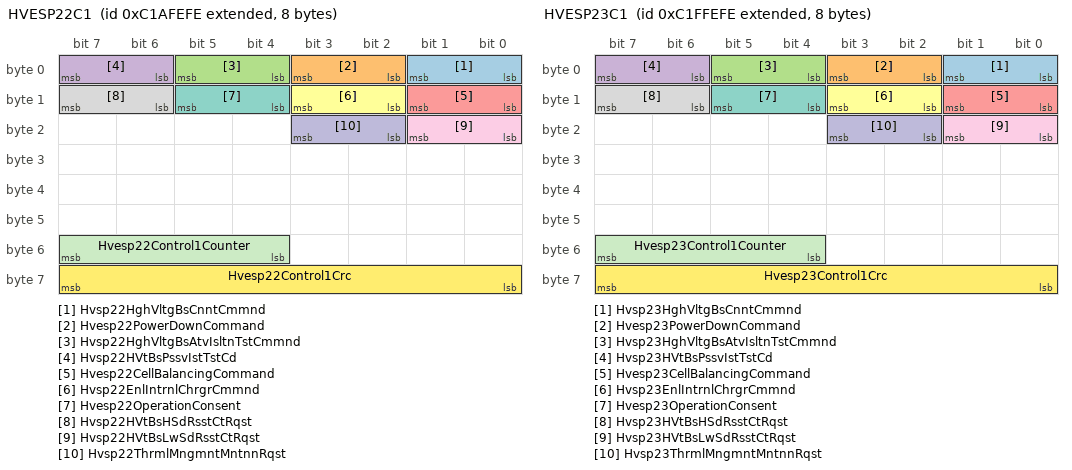
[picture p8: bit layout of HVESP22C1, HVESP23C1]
BO_ 2350579454 HVESP22C1: 8 Vector__XXX
 SG_ Hvsp22HghVltgBsCnntCmmnd : 0|2@1+ (1,0) [0|3] "" Vector__XXX
 SG_ Hvesp22PowerDownCommand : 2|2@1+ (1,0) [0|3] "" Vector__XXX
 SG_ Hvsp22HghVltgBsAtvIsltnTstCmmnd : 4|2@1+ (1,0) [0|3] "" Vector__XXX
 SG_ Hvsp22HVtBsPssvIstTstCd : 6|2@1+ (1,0) [0|3] "" Vector__XXX
 SG_ Hvesp22CellBalancingCommand : 8|2@1+ (1,0) [0|3] "" Vector__XXX
 SG_ Hvsp22EnlIntrnlChrgrCmmnd : 10|2@1+ (1,0) [0|3] "" Vector__XXX
 SG_ Hvesp22OperationConsent : 12|2@1+ (1,0) [0|3] "" Vector__XXX
 SG_ Hvsp22HVtBsHSdRsstCtRqst : 14|2@1+ (1,0) [0|3] "" Vector__XXX
 SG_ Hvsp22HVtBsLwSdRsstCtRqst : 16|2@1+ (1,0) [0|3] "" Vector__XXX
 SG_ Hvsp22ThrmlMngmntMntnnRqst : 18|2@1+ (1,0) [0|3] "" Vector__XXX
 SG_ Hvesp22Control1Counter : 52|4@1+ (1,0) [0|15] "" Vector__XXX
 SG_ Hvesp22Control1Crc : 56|8@1+ (1,0) [0|250] "count" Vector__XXX

BO_ 2350907134 HVESP23C1: 8 Vector__XXX
 SG_ Hvsp23HghVltgBsCnntCmmnd : 0|2@1+ (1,0) [0|3] "" Vector__XXX
 SG_ Hvesp23PowerDownCommand : 2|2@1+ (1,0) [0|3] "" Vector__XXX
 SG_ Hvsp23HghVltgBsAtvIsltnTstCmmnd : 4|2@1+ (1,0) [0|3] "" Vector__XXX
 SG_ Hvsp23HVtBsPssvIstTstCd : 6|2@1+ (1,0) [0|3] "" Vector__XXX
 SG_ Hvesp23CellBalancingCommand : 8|2@1+ (1,0) [0|3] "" Vector__XXX
 SG_ Hvsp23EnlIntrnlChrgrCmmnd : 10|2@1+ (1,0) [0|3] "" Vector__XXX
 SG_ Hvesp23OperationConsent : 12|2@1+ (1,0) [0|3] "" Vector__XXX
 SG_ Hvsp23HVtBsHSdRsstCtRqst : 14|2@1+ (1,0) [0|3] "" Vector__XXX
 SG_ Hvsp23HVtBsLwSdRsstCtRqst : 16|2@1+ (1,0) [0|3] "" Vector__XXX
 SG_ Hvsp23ThrmlMngmntMntnnRqst : 18|2@1+ (1,0) [0|3] "" Vector__XXX
 SG_ Hvesp23Control1Counter : 52|4@1+ (1,0) [0|15] "" Vector__XXX
 SG_ Hvesp23Control1Crc : 56|8@1+ (1,0) [0|250] "count" Vector__XXX

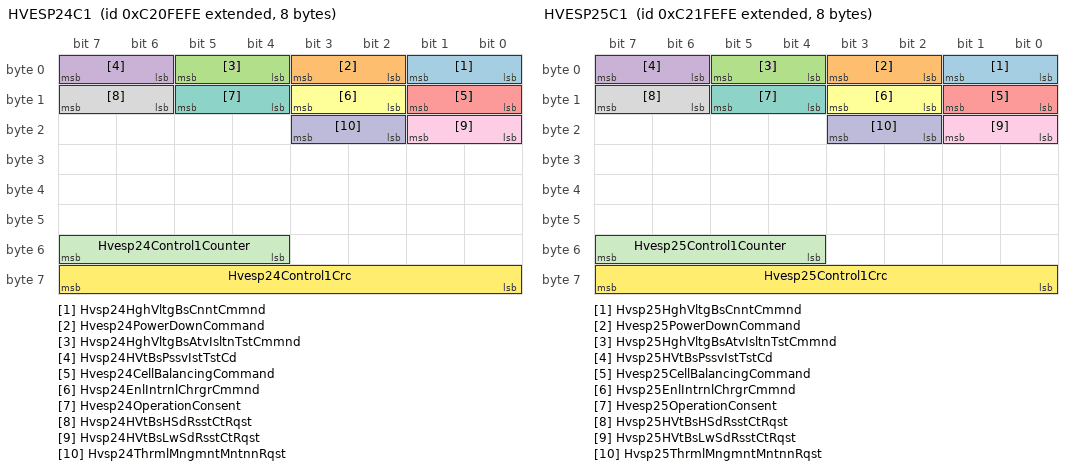
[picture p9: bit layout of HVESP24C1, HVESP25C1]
BO_ 2350972670 HVESP24C1: 8 Vector__XXX
 SG_ Hvsp24HghVltgBsCnntCmmnd : 0|2@1+ (1,0) [0|3] "" Vector__XXX
 SG_ Hvesp24PowerDownCommand : 2|2@1+ (1,0) [0|3] "" Vector__XXX
 SG_ Hvsp24HghVltgBsAtvIsltnTstCmmnd : 4|2@1+ (1,0) [0|3] "" Vector__XXX
 SG_ Hvsp24HVtBsPssvIstTstCd : 6|2@1+ (1,0) [0|3] "" Vector__XXX
 SG_ Hvesp24CellBalancingCommand : 8|2@1+ (1,0) [0|3] "" Vector__XXX
 SG_ Hvsp24EnlIntrnlChrgrCmmnd : 10|2@1+ (1,0) [0|3] "" Vector__XXX
 SG_ Hvesp24OperationConsent : 12|2@1+ (1,0) [0|3] "" Vector__XXX
 SG_ Hvsp24HVtBsHSdRsstCtRqst : 14|2@1+ (1,0) [0|3] "" Vector__XXX
 SG_ Hvsp24HVtBsLwSdRsstCtRqst : 16|2@1+ (1,0) [0|3] "" Vector__XXX
 SG_ Hvsp24ThrmlMngmntMntnnRqst : 18|2@1+ (1,0) [0|3] "" Vector__XXX
 SG_ Hvesp24Control1Counter : 52|4@1+ (1,0) [0|15] "" Vector__XXX
 SG_ Hvesp24Control1Crc : 56|8@1+ (1,0) [0|250] "count" Vector__XXX

BO_ 2351038206 HVESP25C1: 8 Vector__XXX
 SG_ Hvsp25HghVltgBsCnntCmmnd : 0|2@1+ (1,0) [0|3] "" Vector__XXX
 SG_ Hvesp25PowerDownCommand : 2|2@1+ (1,0) [0|3] "" Vector__XXX
 SG_ Hvsp25HghVltgBsAtvIsltnTstCmmnd : 4|2@1+ (1,0) [0|3] "" Vector__XXX
 SG_ Hvsp25HVtBsPssvIstTstCd : 6|2@1+ (1,0) [0|3] "" Vector__XXX
 SG_ Hvesp25CellBalancingCommand : 8|2@1+ (1,0) [0|3] "" Vector__XXX
 SG_ Hvsp25EnlIntrnlChrgrCmmnd : 10|2@1+ (1,0) [0|3] "" Vector__XXX
 SG_ Hvesp25OperationConsent : 12|2@1+ (1,0) [0|3] "" Vector__XXX
 SG_ Hvsp25HVtBsHSdRsstCtRqst : 14|2@1+ (1,0) [0|3] "" Vector__XXX
 SG_ Hvsp25HVtBsLwSdRsstCtRqst : 16|2@1+ (1,0) [0|3] "" Vector__XXX
 SG_ Hvsp25ThrmlMngmntMntnnRqst : 18|2@1+ (1,0) [0|3] "" Vector__XXX
 SG_ Hvesp25Control1Counter : 52|4@1+ (1,0) [0|15] "" Vector__XXX
 SG_ Hvesp25Control1Crc : 56|8@1+ (1,0) [0|250] "count" Vector__XXX

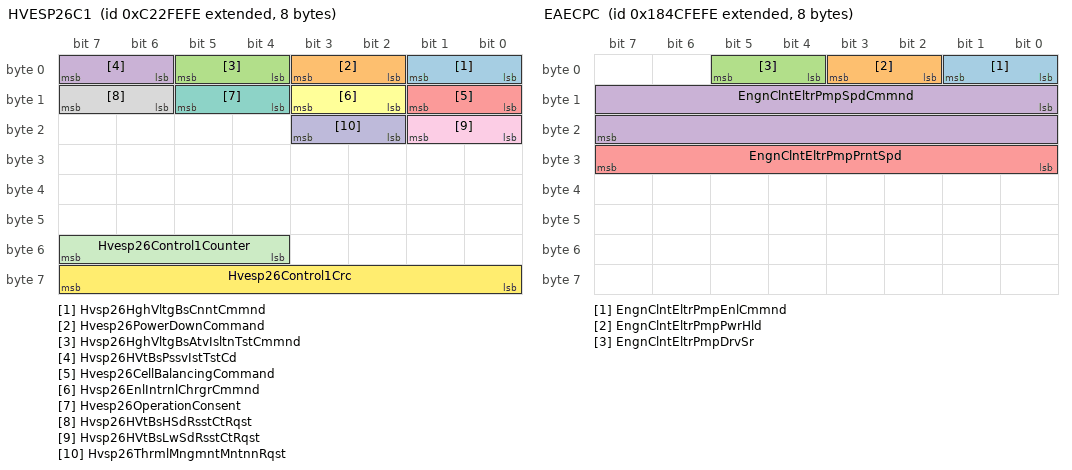
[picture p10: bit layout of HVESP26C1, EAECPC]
BO_ 2351103742 HVESP26C1: 8 Vector__XXX
 SG_ Hvsp26HghVltgBsCnntCmmnd : 0|2@1+ (1,0) [0|3] "" Vector__XXX
 SG_ Hvesp26PowerDownCommand : 2|2@1+ (1,0) [0|3] "" Vector__XXX
 SG_ Hvsp26HghVltgBsAtvIsltnTstCmmnd : 4|2@1+ (1,0) [0|3] "" Vector__XXX
 SG_ Hvsp26HVtBsPssvIstTstCd : 6|2@1+ (1,0) [0|3] "" Vector__XXX
 SG_ Hvesp26CellBalancingCommand : 8|2@1+ (1,0) [0|3] "" Vector__XXX
 SG_ Hvsp26EnlIntrnlChrgrCmmnd : 10|2@1+ (1,0) [0|3] "" Vector__XXX
 SG_ Hvesp26OperationConsent : 12|2@1+ (1,0) [0|3] "" Vector__XXX
 SG_ Hvsp26HVtBsHSdRsstCtRqst : 14|2@1+ (1,0) [0|3] "" Vector__XXX
 SG_ Hvsp26HVtBsLwSdRsstCtRqst : 16|2@1+ (1,0) [0|3] "" Vector__XXX
 SG_ Hvsp26ThrmlMngmntMntnnRqst : 18|2@1+ (1,0) [0|3] "" Vector__XXX
 SG_ Hvesp26Control1Counter : 52|4@1+ (1,0) [0|15] "" Vector__XXX
 SG_ Hvesp26Control1Crc : 56|8@1+ (1,0) [0|250] "count" Vector__XXX

BO_ 2555182846 EAECPC: 8 Vector__XXX
 SG_ EngnClntEltrPmpEnlCmmnd : 0|2@1+ (1,0) [0|3] "" Vector__XXX
 SG_ EngnClntEltrPmpPwrHld : 2|2@1+ (1,0) [0|3] "" Vector__XXX
 SG_ EngnClntEltrPmpDrvSr : 4|2@1+ (1,0) [0|3] "" Vector__XXX
 SG_ EngnClntEltrPmpSpdCmmnd : 8|16@1+ (0.5,0) [0|32127.5] "rpm" Vector__XXX
 SG_ EngnClntEltrPmpPrntSpd : 24|8@1+ (0.5,0) [0|125] "%" Vector__XXX

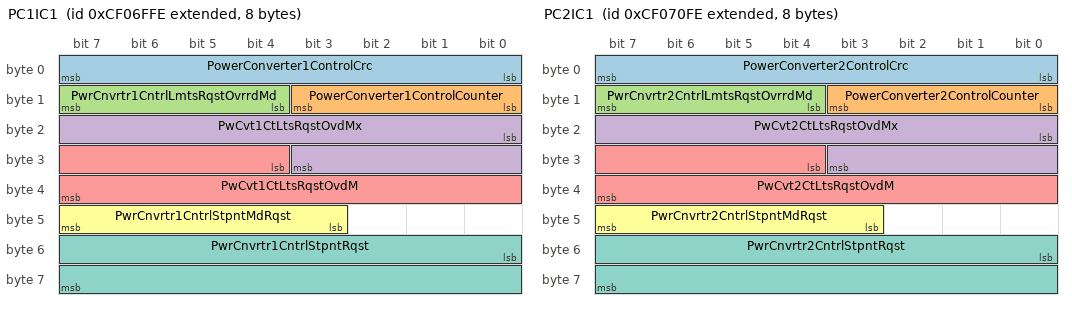
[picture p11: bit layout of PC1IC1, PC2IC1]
BO_ 2364567550 PC1IC1: 8 Vector__XXX
 SG_ PowerConverter1ControlCrc : 0|8@1+ (1,0) [0|250] "count" Vector__XXX
 SG_ PowerConverter1ControlCounter : 8|4@1+ (1,0) [0|15] "" Vector__XXX
 SG_ PwrCnvrtr1CntrlLmtsRqstOvrrdMd : 12|4@1+ (1,0) [0|15] "" Vector__XXX
 SG_ PwCvt1CtLtsRqstOvdMx : 16|12@1+ (0.0625,-125) [-125|125.9375] "%" Vector__XXX
 SG_ PwCvt1CtLtsRqstOvdM : 28|12@1+ (0.0625,-125) [-125|125.9375] "%" Vector__XXX
 SG_ PwrCnvrtr1CntrlStpntMdRqst : 43|5@1+ (1,0) [0|31] "" Vector__XXX
 SG_ PwrCnvrtr1CntrlStpntRqst : 48|16@1+ (0.00390625,-125) [-125|125.99609375] "%" Vector__XXX

BO_ 2364567806 PC2IC1: 8 Vector__XXX
 SG_ PowerConverter2ControlCrc : 0|8@1+ (1,0) [0|250] "count" Vector__XXX
 SG_ PowerConverter2ControlCounter : 8|4@1+ (1,0) [0|15] "" Vector__XXX
 SG_ PwrCnvrtr2CntrlLmtsRqstOvrrdMd : 12|4@1+ (1,0) [0|15] "" Vector__XXX
 SG_ PwCvt2CtLtsRqstOvdMx : 16|12@1+ (0.0625,-125) [-125|125.9375] "%" Vector__XXX
 SG_ PwCvt2CtLtsRqstOvdM : 28|12@1+ (0.0625,-125) [-125|125.9375] "%" Vector__XXX
 SG_ PwrCnvrtr2CntrlStpntMdRqst : 43|5@1+ (1,0) [0|31] "" Vector__XXX
 SG_ PwrCnvrtr2CntrlStpntRqst : 48|16@1+ (0.00390625,-125) [-125|125.99609375] "%" Vector__XXX

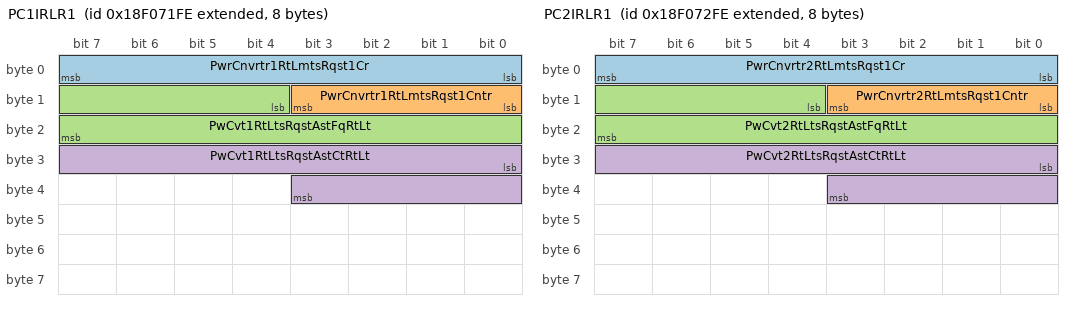
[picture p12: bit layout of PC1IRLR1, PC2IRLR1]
BO_ 2565894654 PC1IRLR1: 8 Vector__XXX
 SG_ PwrCnvrtr1RtLmtsRqst1Cr : 0|8@1+ (1,0) [0|250] "count" Vector__XXX
 SG_ PwrCnvrtr1RtLmtsRqst1Cntr : 8|4@1+ (1,0) [0|15] "" Vector__XXX
 SG_ PwCvt1RtLtsRqstAstFqRtLt : 12|12@1+ (0.25,0) [0|1003.75] "%/s" Vector__XXX
 SG_ PwCvt1RtLtsRqstAstCtRtLt : 24|12@1+ (2,0) [0|8030] "%/s" Vector__XXX

BO_ 2565894910 PC2IRLR1: 8 Vector__XXX
 SG_ PwrCnvrtr2RtLmtsRqst1Cr : 0|8@1+ (1,0) [0|250] "count" Vector__XXX
 SG_ PwrCnvrtr2RtLmtsRqst1Cntr : 8|4@1+ (1,0) [0|15] "" Vector__XXX
 SG_ PwCvt2RtLtsRqstAstFqRtLt : 12|12@1+ (0.25,0) [0|1003.75] "%/s" Vector__XXX
 SG_ PwCvt2RtLtsRqstAstCtRtLt : 24|12@1+ (2,0) [0|8030] "%/s" Vector__XXX

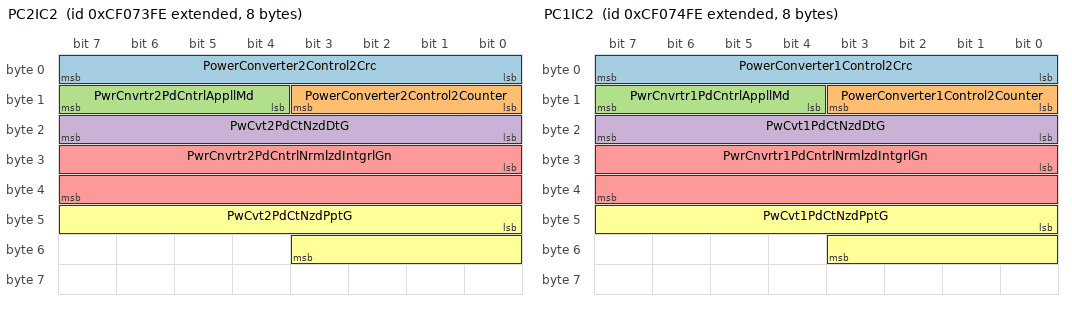
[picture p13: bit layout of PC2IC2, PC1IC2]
BO_ 2364568574 PC2IC2: 8 Vector__XXX
 SG_ PowerConverter2Control2Crc : 0|8@1+ (1,0) [0|250] "count" Vector__XXX
 SG_ PowerConverter2Control2Counter : 8|4@1+ (1,0) [0|15] "" Vector__XXX
 SG_ PwrCnvrtr2PdCntrlAppllMd : 12|4@1+ (1,0) [0|15] "" Vector__XXX
 SG_ PwCvt2PdCtNzdDtG : 16|8@1+ (0.03125,0) [0|7.8125] "%/(%/s)" Vector__XXX
 SG_ PwrCnvrtr2PdCntrlNrmlzdIntgrlGn : 24|16@1+ (0.015625,0) [0|1003.984375] "%/(%/s)" Vector__XXX
 SG_ PwCvt2PdCtNzdPptG : 40|12@1+ (0.0625,0) [0|250.9375] "%/%" Vector__XXX

BO_ 2364568830 PC1IC2: 8 Vector__XXX
 SG_ PowerConverter1Control2Crc : 0|8@1+ (1,0) [0|250] "count" Vector__XXX
 SG_ PowerConverter1Control2Counter : 8|4@1+ (1,0) [0|15] "" Vector__XXX
 SG_ PwrCnvrtr1PdCntrlAppllMd : 12|4@1+ (1,0) [0|15] "" Vector__XXX
 SG_ PwCvt1PdCtNzdDtG : 16|8@1+ (0.03125,0) [0|7.8125] "%/(%/s)" Vector__XXX
 SG_ PwrCnvrtr1PdCntrlNrmlzdIntgrlGn : 24|16@1+ (0.015625,0) [0|1003.984375] "%/(%/s)" Vector__XXX
 SG_ PwCvt1PdCtNzdPptG : 40|12@1+ (0.0625,0) [0|250.9375] "%/%" Vector__XXX

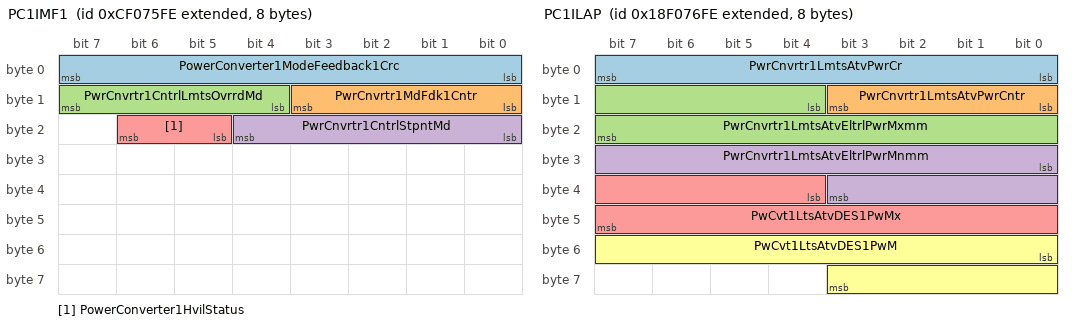
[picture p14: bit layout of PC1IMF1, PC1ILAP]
BO_ 2364569086 PC1IMF1: 8 Vector__XXX
 SG_ PowerConverter1ModeFeedback1Crc : 0|8@1+ (1,0) [0|250] "count" Vector__XXX
 SG_ PwrCnvrtr1MdFdk1Cntr : 8|4@1+ (1,0) [0|15] "" Vector__XXX
 SG_ PwrCnvrtr1CntrlLmtsOvrrdMd : 12|4@1+ (1,0) [0|15] "" Vector__XXX
 SG_ PwrCnvrtr1CntrlStpntMd : 16|5@1+ (1,0) [0|31] "" Vector__XXX
 SG_ PowerConverter1HvilStatus : 21|2@1+ (1,0) [0|3] "" Vector__XXX

BO_ 2565895934 PC1ILAP: 8 Vector__XXX
 SG_ PwrCnvrtr1LmtsAtvPwrCr : 0|8@1+ (1,0) [0|250] "count" Vector__XXX
 SG_ PwrCnvrtr1LmtsAtvPwrCntr : 8|4@1+ (1,0) [0|15] "" Vector__XXX
 SG_ PwrCnvrtr1LmtsAtvEltrlPwrMxmm : 12|12@1+ (0.0625,-125) [-125|125.9375] "%" Vector__XXX
 SG_ PwrCnvrtr1LmtsAtvEltrlPwrMnmm : 24|12@1+ (0.0625,-125) [-125|125.9375] "%" Vector__XXX
 SG_ PwCvt1LtsAtvDES1PwMx : 36|12@1+ (0.0625,-125) [-125|125.9375] "%" Vector__XXX
 SG_ PwCvt1LtsAtvDES1PwM : 48|12@1+ (0.0625,-125) [-125|125.9375] "%" Vector__XXX

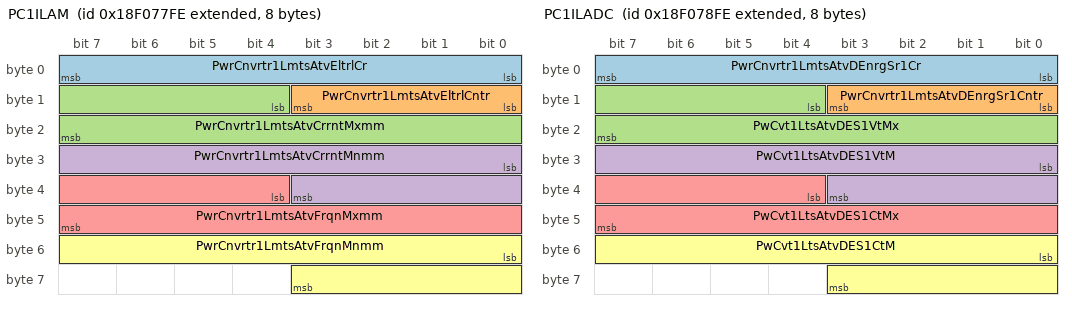
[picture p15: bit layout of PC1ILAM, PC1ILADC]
BO_ 2565896190 PC1ILAM: 8 Vector__XXX
 SG_ PwrCnvrtr1LmtsAtvEltrlCr : 0|8@1+ (1,0) [0|250] "count" Vector__XXX
 SG_ PwrCnvrtr1LmtsAtvEltrlCntr : 8|4@1+ (1,0) [0|15] "" Vector__XXX
 SG_ PwrCnvrtr1LmtsAtvCrrntMxmm : 12|12@1+ (0.0625,-125) [-125|125.9375] "%" Vector__XXX
 SG_ PwrCnvrtr1LmtsAtvCrrntMnmm : 24|12@1+ (0.0625,-125) [-125|125.9375] "%" Vector__XXX
 SG_ PwrCnvrtr1LmtsAtvFrqnMxmm : 36|12@1+ (0.0625,-125) [-125|125.9375] "%" Vector__XXX
 SG_ PwrCnvrtr1LmtsAtvFrqnMnmm : 48|12@1+ (0.0625,-125) [-125|125.9375] "%" Vector__XXX

BO_ 2565896446 PC1ILADC: 8 Vector__XXX
 SG_ PwrCnvrtr1LmtsAtvDEnrgSr1Cr : 0|8@1+ (1,0) [0|250] "count" Vector__XXX
 SG_ PwrCnvrtr1LmtsAtvDEnrgSr1Cntr : 8|4@1+ (1,0) [0|15] "" Vector__XXX
 SG_ PwCvt1LtsAtvDES1VtMx : 12|12@1+ (0.0625,-125) [-125|125.9375] "%" Vector__XXX
 SG_ PwCvt1LtsAtvDES1VtM : 24|12@1+ (0.0625,-125) [-125|125.9375] "%" Vector__XXX
 SG_ PwCvt1LtsAtvDES1CtMx : 36|12@1+ (0.0625,-125) [-125|125.9375] "%" Vector__XXX
 SG_ PwCvt1LtsAtvDES1CtM : 48|12@1+ (0.0625,-125) [-125|125.9375] "%" Vector__XXX

BO_ 2565896702 PC1ILV: 8 Vector__XXX
 SG_ PwrCnvrtr1SwthdIgntnVltg : 0|16@1+ (0.05,0) [0|3212.75] "V" Vector__XXX
 SG_ PwrCnvrtr1UnswthdSlVltg : 16|16@1+ (0.05,0) [0|3212.75] "V" Vector__XXX

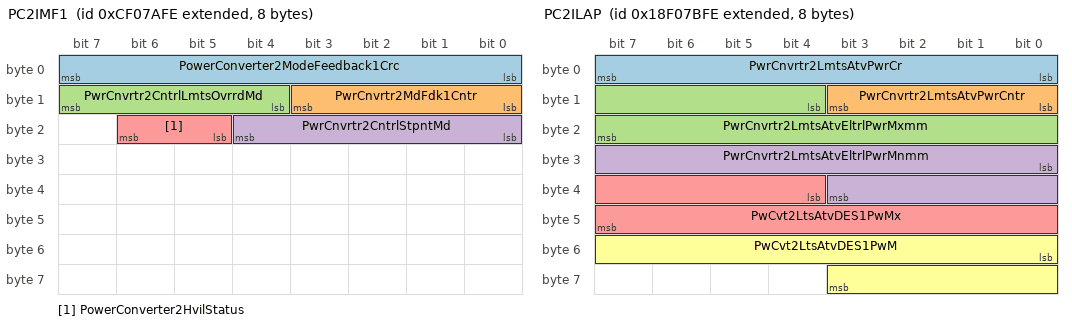
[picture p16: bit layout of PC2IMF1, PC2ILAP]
BO_ 2364570366 PC2IMF1: 8 Vector__XXX
 SG_ PowerConverter2ModeFeedback1Crc : 0|8@1+ (1,0) [0|250] "count" Vector__XXX
 SG_ PwrCnvrtr2MdFdk1Cntr : 8|4@1+ (1,0) [0|15] "" Vector__XXX
 SG_ PwrCnvrtr2CntrlLmtsOvrrdMd : 12|4@1+ (1,0) [0|15] "" Vector__XXX
 SG_ PwrCnvrtr2CntrlStpntMd : 16|5@1+ (1,0) [0|31] "" Vector__XXX
 SG_ PowerConverter2HvilStatus : 21|2@1+ (1,0) [0|3] "" Vector__XXX

BO_ 2565897214 PC2ILAP: 8 Vector__XXX
 SG_ PwrCnvrtr2LmtsAtvPwrCr : 0|8@1+ (1,0) [0|250] "count" Vector__XXX
 SG_ PwrCnvrtr2LmtsAtvPwrCntr : 8|4@1+ (1,0) [0|15] "" Vector__XXX
 SG_ PwrCnvrtr2LmtsAtvEltrlPwrMxmm : 12|12@1+ (0.0625,-125) [-125|125.9375] "%" Vector__XXX
 SG_ PwrCnvrtr2LmtsAtvEltrlPwrMnmm : 24|12@1+ (0.0625,-125) [-125|125.9375] "%" Vector__XXX
 SG_ PwCvt2LtsAtvDES1PwMx : 36|12@1+ (0.0625,-125) [-125|125.9375] "%" Vector__XXX
 SG_ PwCvt2LtsAtvDES1PwM : 48|12@1+ (0.0625,-125) [-125|125.9375] "%" Vector__XXX

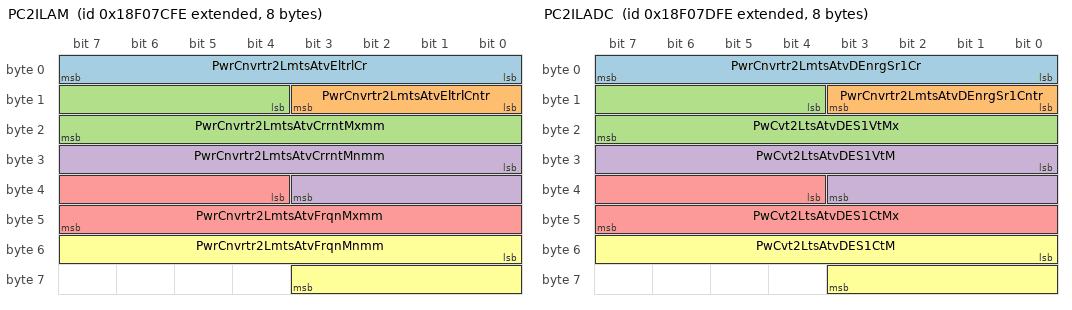
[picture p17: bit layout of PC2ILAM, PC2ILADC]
BO_ 2565897470 PC2ILAM: 8 Vector__XXX
 SG_ PwrCnvrtr2LmtsAtvEltrlCr : 0|8@1+ (1,0) [0|250] "count" Vector__XXX
 SG_ PwrCnvrtr2LmtsAtvEltrlCntr : 8|4@1+ (1,0) [0|15] "" Vector__XXX
 SG_ PwrCnvrtr2LmtsAtvCrrntMxmm : 12|12@1+ (0.0625,-125) [-125|125.9375] "%" Vector__XXX
 SG_ PwrCnvrtr2LmtsAtvCrrntMnmm : 24|12@1+ (0.0625,-125) [-125|125.9375] "%" Vector__XXX
 SG_ PwrCnvrtr2LmtsAtvFrqnMxmm : 36|12@1+ (0.0625,-125) [-125|125.9375] "%" Vector__XXX
 SG_ PwrCnvrtr2LmtsAtvFrqnMnmm : 48|12@1+ (0.0625,-125) [-125|125.9375] "%" Vector__XXX

BO_ 2565897726 PC2ILADC: 8 Vector__XXX
 SG_ PwrCnvrtr2LmtsAtvDEnrgSr1Cr : 0|8@1+ (1,0) [0|250] "count" Vector__XXX
 SG_ PwrCnvrtr2LmtsAtvDEnrgSr1Cntr : 8|4@1+ (1,0) [0|15] "" Vector__XXX
 SG_ PwCvt2LtsAtvDES1VtMx : 12|12@1+ (0.0625,-125) [-125|125.9375] "%" Vector__XXX
 SG_ PwCvt2LtsAtvDES1VtM : 24|12@1+ (0.0625,-125) [-125|125.9375] "%" Vector__XXX
 SG_ PwCvt2LtsAtvDES1CtMx : 36|12@1+ (0.0625,-125) [-125|125.9375] "%" Vector__XXX
 SG_ PwCvt2LtsAtvDES1CtM : 48|12@1+ (0.0625,-125) [-125|125.9375] "%" Vector__XXX

BO_ 2565897982 PC2ILV: 8 Vector__XXX
 SG_ PwrCnvrtr2SwthdIgntnVltg : 0|16@1+ (0.05,0) [0|3212.75] "V" Vector__XXX
 SG_ PwrCnvrtr2UnswthdSlVltg : 16|16@1+ (0.05,0) [0|3212.75] "V" Vector__XXX

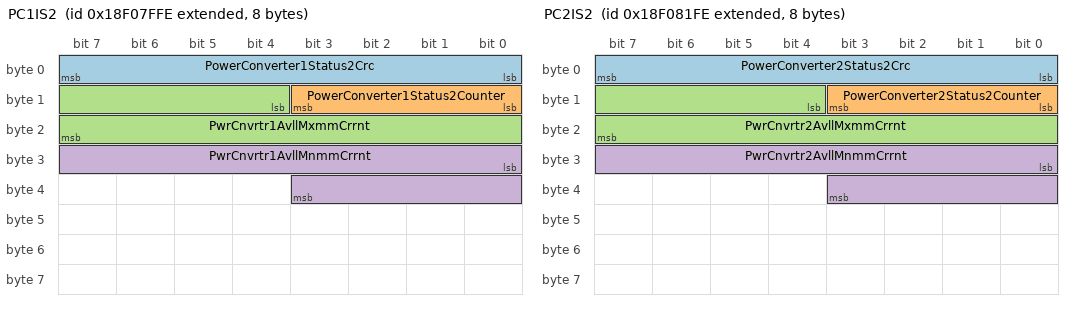
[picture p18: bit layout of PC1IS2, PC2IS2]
BO_ 2565898238 PC1IS2: 8 Vector__XXX
 SG_ PowerConverter1Status2Crc : 0|8@1+ (1,0) [0|250] "count" Vector__XXX
 SG_ PowerConverter1Status2Counter : 8|4@1+ (1,0) [0|15] "" Vector__XXX
 SG_ PwrCnvrtr1AvllMxmmCrrnt : 12|12@1+ (0.0625,-125) [-125|125.9375] "%" Vector__XXX
 SG_ PwrCnvrtr1AvllMnmmCrrnt : 24|12@1+ (0.0625,-125) [-125|125.9375] "%" Vector__XXX

BO_ 2565898494 PC1IRLA1: 8 Vector__XXX
 SG_ PwrCnvrtr1RtLmtsAtv1Cr : 0|8@1+ (1,0) [0|250] "count" Vector__XXX
 SG_ PwrCnvrtr1RtLmtsAtv1Cntr : 8|4@1+ (1,0) [0|15] "" Vector__XXX
 SG_ PwCvt1RtLtsAtvAstCtRtLt : 24|12@1+ (2,0) [0|8030] "%/s" Vector__XXX

BO_ 2565898750 PC2IS2: 8 Vector__XXX
 SG_ PowerConverter2Status2Crc : 0|8@1+ (1,0) [0|250] "count" Vector__XXX
 SG_ PowerConverter2Status2Counter : 8|4@1+ (1,0) [0|15] "" Vector__XXX
 SG_ PwrCnvrtr2AvllMxmmCrrnt : 12|12@1+ (0.0625,-125) [-125|125.9375] "%" Vector__XXX
 SG_ PwrCnvrtr2AvllMnmmCrrnt : 24|12@1+ (0.0625,-125) [-125|125.9375] "%" Vector__XXX

BO_ 2565899006 PC2IRLA1: 8 Vector__XXX
 SG_ PwrCnvrtr2RtLmtsAtv1Cr : 0|8@1+ (1,0) [0|250] "count" Vector__XXX
 SG_ PwrCnvrtr2RtLmtsAtv1Cntr : 8|4@1+ (1,0) [0|15] "" Vector__XXX
 SG_ PwCvt2RtLtsAtvAstCtRtLt : 24|12@1+ (2,0) [0|8030] "%/s" Vector__XXX

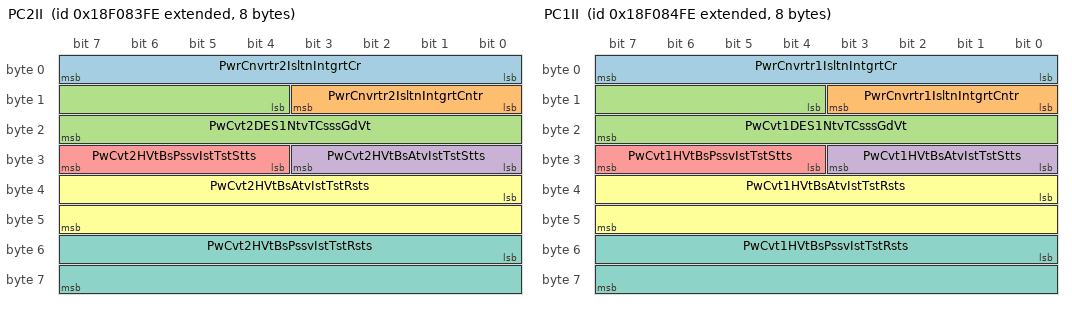
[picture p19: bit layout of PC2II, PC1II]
BO_ 2565899262 PC2II: 8 Vector__XXX
 SG_ PwrCnvrtr2IsltnIntgrtCr : 0|8@1+ (1,0) [0|250] "count" Vector__XXX
 SG_ PwrCnvrtr2IsltnIntgrtCntr : 8|4@1+ (1,0) [0|15] "" Vector__XXX
 SG_ PwCvt2DES1NtvTCsssGdVt : 12|12@1+ (0.0625,-125) [-125|125.9375] "%" Vector__XXX
 SG_ PwCvt2HVtBsAtvIstTstStts : 24|4@1+ (1,0) [0|15] "" Vector__XXX
 SG_ PwCvt2HVtBsPssvIstTstStts : 28|4@1+ (1,0) [0|15] "" Vector__XXX
 SG_ PwCvt2HVtBsAtvIstTstRsts : 32|16@1+ (0.1,0) [0|6425.5] "OhmPerV" Vector__XXX
 SG_ PwCvt2HVtBsPssvIstTstRsts : 48|16@1+ (0.1,0) [0|6425.5] "OhmPerV" Vector__XXX

BO_ 2565899518 PC1II: 8 Vector__XXX
 SG_ PwrCnvrtr1IsltnIntgrtCr : 0|8@1+ (1,0) [0|250] "count" Vector__XXX
 SG_ PwrCnvrtr1IsltnIntgrtCntr : 8|4@1+ (1,0) [0|15] "" Vector__XXX
 SG_ PwCvt1DES1NtvTCsssGdVt : 12|12@1+ (0.0625,-125) [-125|125.9375] "%" Vector__XXX
 SG_ PwCvt1HVtBsAtvIstTstStts : 24|4@1+ (1,0) [0|15] "" Vector__XXX
 SG_ PwCvt1HVtBsPssvIstTstStts : 28|4@1+ (1,0) [0|15] "" Vector__XXX
 SG_ PwCvt1HVtBsAtvIstTstRsts : 32|16@1+ (0.1,0) [0|6425.5] "OhmPerV" Vector__XXX
 SG_ PwCvt1HVtBsPssvIstTstRsts : 48|16@1+ (0.1,0) [0|6425.5] "OhmPerV" Vector__XXX

CM_ BO_ 2566565374 "High Voltage Energy Storage Pack 9 Configuration";
CM_ SG_ 2566565374 Hvesp9NominalVoltage "HVESP9 Nominal Voltage: Per the HVES manufacturer, this is the nominal operating voltage of this High Voltage Energy Storage Pack instance, e.g. '300V' or '600V'.This parameter is for one of multiple packs in an HVESS.  If there is only one pack in t...";
CM_ SG_ 2566565374 Hvesp9CellMaximumVoltageLimit "HVESP9 Cell Maximum Voltage Limit: Per the HVES manufacturer, this is the maximum cell voltage for this High Voltage Energy Storage Pack instance operation.  Operating above this value may damage HVES hardware, or compromise HVES life.This parameter ...";
CM_ SG_ 2566565374 Hvesp9CellMinimumVoltageLimit "HVESP9 Cell Minimum Voltage Limit: Per the HVES manufacturer, this is the minimum cell voltage for this High Voltage Energy Storage Pack instance operation.  Operating below this value may damage HVES hardware, or compromise HVES life.This parameter ...";
CM_ SG_ 2566565374 Hvsp9RmmnddMnmmOprtngVltg "HVESP9 Recommended Minimum Operating Voltage: Per the HVES manufacturer, this is the minimum recommended voltage level for this High Voltage Energy Storage Pack instance operation.  Operating below this value may compromise HVES life.This parameter i...";
CM_ SG_ 2566565374 Hvsp9RmmnddMxmmOprtngVltg "HVESP9 Recommended Maximum Operating Voltage: Per the HVES manufacturer, this is the maximum recommended voltage level for this High Voltage Energy Storage Pack instance operation.  Operating above this value may compromise HVES life.This parameter i...";
CM_ SG_ 2566565374 Hvsp9RmmnddMnmmSttOfChrg "HVESP9 Recommended Minimum State Of Charge: Per the HVES manufacturer, this is the recommended minimum state of charge for this High Voltage Energy Storage Pack instance operation.  Operating below this value may compromise HVES life.This parameter i...";
CM_ SG_ 2566565374 Hvsp9RmmnddMxmmSttOfChrg "HVESP9 Recommended Maximum State Of Charge: Per the HVES manufacturer, this is the recommended maximum state of charge for this High Voltage Energy Storage Pack instance operation.  Operating above this value may compromise HVES life.This parameter i...";
CM_ SG_ 2566565374 Hvsp9RmmnddMxmmOprtngTmprtr "HVESP9 Recommended Maximum Operating Temperature: Per the HVES manufacturer, this is the recommended maximum temperature for this High Voltage Energy Storage Pack instance operation.  Operating above this value may damage HVES hardware, or compromise...";
CM_ SG_ 2566565374 Hvsp9RmmnddMnmmOprtngTmprtr "HVESP9 Recommended Minimum Operating Temperature: Per the HVES manufacturer, this is the recommended minimum temperature for this High Voltage Energy Storage Pack instance operation.  Operating below this value may damage HVES hardware, or compromise...";
CM_ BO_ 2633674494 "High Voltage Energy Storage Pack 9 History";
CM_ SG_ 2633674494 Hvesp9StateOfHealth "HVESP9 State of Health: This signal represents the expected remaining Life of this High Voltage Energy Storage Pack instance, in percent.  Battery life is a manufacturer-specific measure of how well the energy storage system is functioning relative t...";
CM_ SG_ 2633674494 Hvesp9TotalEnergyThroughput "HVESP9 Total Energy Throughput: The total energy throughput which has flowed through this High Voltage Energy Storage Pack instance.  This parameter is the sum of the absolute values of the Energy into and out of this HVES instance.  This parameter i...";
CM_ SG_ 2633674494 Hvesp9TotalAccumulatedCharge "HVESP9 Total Accumulated Charge: The total accumulated amp hours which have flowed through this High Voltage Energy Storage Pack instance.  This parameter is the sum of the absolute values of the Ampere hours into and out of this HVES instance.  This...";
CM_ SG_ 2633674494 Hvesp9TotalLifetimeEnergyInput "HVESP9 Total Lifetime Energy Input: The cumulative energy which has flowed into this High Voltage Energy Storage Pack instance over the lifetime of the battery pack. This parameter is the sum of the Energy into this HVES instance. This value is reset...";
CM_ SG_ 2633674494 Hvesp9TotalLifetimeEnergyOutput "HVESP9 Total Lifetime Energy Output: The cumulative energy which has flowed out of this High Voltage Energy Storage Pack instance over the lifetime of the battery pack. This parameter is the sum of the Energy out of this HVES instance. This value is ...";
CM_ SG_ 2633674494 Hvsp9CnttrOpnUndrLdCnt "HVESP9 Contactor Open Under Load Count: This signal represents the number of times the contactors inside this High Voltage Energy Storage Pack instance have opened while current is flowing through them.  The current level (that determines if an openi...";
CM_ BO_ 2566565886 "High Voltage Energy Storage Pack 8 Configuration";
CM_ SG_ 2566565886 Hvesp8NominalVoltage "HVESP8 Nominal Voltage: Per the HVES manufacturer, this is the nominal operating voltage of this High Voltage Energy Storage Pack instance, e.g. '300V' or '600V'.This parameter is for one of multiple packs in an HVESS.  If there is only one pack in t...";
CM_ SG_ 2566565886 Hvesp8CellMaximumVoltageLimit "HVESP8 Cell Maximum Voltage Limit: Per the HVES manufacturer, this is the maximum cell voltage for this High Voltage Energy Storage Pack instance operation.  Operating above this value may damage HVES hardware, or compromise HVES life.This parameter ...";
CM_ SG_ 2566565886 Hvesp8CellMinimumVoltageLimit "HVESP8 Cell Minimum Voltage Limit: Per the HVES manufacturer, this is the minimum cell voltage for this High Voltage Energy Storage Pack instance operation.  Operating below this value may damage HVES hardware, or compromise HVES life.This parameter ...";
CM_ SG_ 2566565886 Hvsp8RmmnddMnmmOprtngVltg "HVESP8 Recommended Minimum Operating Voltage: Per the HVES manufacturer, this is the minimum recommended voltage level for this High Voltage Energy Storage Pack instance operation.  Operating below this value may compromise HVES life.This parameter i...";
CM_ SG_ 2566565886 Hvsp8RmmnddMxmmOprtngVltg "HVESP8 Recommended Maximum Operating Voltage: Per the HVES manufacturer, this is the maximum recommended voltage level for this High Voltage Energy Storage Pack instance operation.  Operating above this value may compromise HVES life.This parameter i...";
CM_ SG_ 2566565886 Hvsp8RmmnddMnmmSttOfChrg "HVESP8 Recommended Minimum State Of Charge: Per the HVES manufacturer, this is the recommended minimum state of charge for this High Voltage Energy Storage Pack instance operation.  Operating below this value may compromise HVES life.This parameter i...";
CM_ SG_ 2566565886 Hvsp8RmmnddMxmmSttOfChrg "HVESP8 Recommended Maximum State Of Charge: Per the HVES manufacturer, this is the recommended maximum state of charge for this High Voltage Energy Storage Pack instance operation.  Operating above this value may compromise HVES life.This parameter i...";
CM_ SG_ 2566565886 Hvsp8RmmnddMxmmOprtngTmprtr "HVESP8 Recommended Maximum Operating Temperature: Per the HVES manufacturer, this is the recommended maximum temperature for this High Voltage Energy Storage Pack instance operation.  Operating above this value may damage HVES hardware, or compromise...";
CM_ SG_ 2566565886 Hvsp8RmmnddMnmmOprtngTmprtr "HVESP8 Recommended Minimum Operating Temperature: Per the HVES manufacturer, this is the recommended minimum temperature for this High Voltage Energy Storage Pack instance operation.  Operating below this value may damage HVES hardware, or compromise...";
CM_ BO_ 2633675006 "High Voltage Energy Storage Pack 8 History";
CM_ SG_ 2633675006 Hvesp8StateOfHealth "HVESP8 State of Health: This signal represents the expected remaining Life of this High Voltage Energy Storage Pack instance, in percent.  Battery life is a manufacturer-specific measure of how well the energy storage system is functioning relative t...";
CM_ SG_ 2633675006 Hvesp8TotalEnergyThroughput "HVESP8 Total Energy Throughput: The total energy throughput which has flowed through this High Voltage Energy Storage Pack instance.  This parameter is the sum of the absolute values of the Energy into and out of this HVES instance.  This parameter i...";
CM_ SG_ 2633675006 Hvesp8TotalAccumulatedCharge "HVESP8 Total Accumulated Charge: The total accumulated amp hours which have flowed through this High Voltage Energy Storage Pack instance.  This parameter is the sum of the absolute values of the Ampere hours into and out of this HVES instance.  This...";
CM_ SG_ 2633675006 Hvesp8TotalLifetimeEnergyInput "HVESP8 Total Lifetime Energy Input: The cumulative energy which has flowed into this High Voltage Energy Storage Pack instance over the lifetime of the battery pack. This parameter is the sum of the Energy into this HVES instance. This value is reset...";
CM_ SG_ 2633675006 Hvesp8TotalLifetimeEnergyOutput "HVESP8 Total Lifetime Energy Output: The cumulative energy which has flowed out of this High Voltage Energy Storage Pack instance over the lifetime of the battery pack. This parameter is the sum of the Energy out of this HVES instance. This value is ...";
CM_ SG_ 2633675006 Hvsp8CnttrOpnUndrLdCnt "HVESP8 Contactor Open Under Load Count: This signal represents the number of times the contactors inside this High Voltage Energy Storage Pack instance have opened while current is flowing through them.  The current level (that determines if an openi...";
CM_ BO_ 2566566398 "High Voltage Energy Storage Pack 7 Configuration";
CM_ SG_ 2566566398 Hvesp7NominalVoltage "HVESP7 Nominal Voltage: Per the HVES manufacturer, this is the nominal operating voltage of this High Voltage Energy Storage Pack instance, e.g. '300V' or '600V'.This parameter is for one of multiple packs in an HVESS.  If there is only one pack in t...";
CM_ SG_ 2566566398 Hvesp7CellMaximumVoltageLimit "HVESP7 Cell Maximum Voltage Limit: Per the HVES manufacturer, this is the maximum cell voltage for this High Voltage Energy Storage Pack instance operation.  Operating above this value may damage HVES hardware, or compromise HVES life.This parameter ...";
CM_ SG_ 2566566398 Hvesp7CellMinimumVoltageLimit "HVESP7 Cell Minimum Voltage Limit: Per the HVES manufacturer, this is the minimum cell voltage for this High Voltage Energy Storage Pack instance operation.  Operating below this value may damage HVES hardware, or compromise HVES life.This parameter ...";
CM_ SG_ 2566566398 Hvsp7RmmnddMnmmOprtngVltg "HVESP7 Recommended Minimum Operating Voltage: Per the HVES manufacturer, this is the minimum recommended voltage level for this High Voltage Energy Storage Pack instance operation.  Operating below this value may compromise HVES life.This parameter i...";
CM_ SG_ 2566566398 Hvsp7RmmnddMxmmOprtngVltg "HVESP7 Recommended Maximum Operating Voltage: Per the HVES manufacturer, this is the maximum recommended voltage level for this High Voltage Energy Storage Pack instance operation.  Operating above this value may compromise HVES life.This parameter i...";
CM_ SG_ 2566566398 Hvsp7RmmnddMnmmSttOfChrg "HVESP7 Recommended Minimum State Of Charge: Per the HVES manufacturer, this is the recommended minimum state of charge for this High Voltage Energy Storage Pack instance operation.  Operating below this value may compromise HVES life.This parameter i...";
CM_ SG_ 2566566398 Hvsp7RmmnddMxmmSttOfChrg "HVESP7 Recommended Maximum State Of Charge: Per the HVES manufacturer, this is the recommended maximum state of charge for this High Voltage Energy Storage Pack instance operation.  Operating above this value may compromise HVES life.This parameter i...";
CM_ SG_ 2566566398 Hvsp7RmmnddMxmmOprtngTmprtr "HVESP7 Recommended Maximum Operating Temperature: Per the HVES manufacturer, this is the recommended maximum temperature for this High Voltage Energy Storage Pack instance operation.  Operating above this value may damage HVES hardware, or compromise...";
CM_ SG_ 2566566398 Hvsp7RmmnddMnmmOprtngTmprtr "HVESP7 Recommended Minimum Operating Temperature: Per the HVES manufacturer, this is the recommended minimum temperature for this High Voltage Energy Storage Pack instance operation.  Operating below this value may damage HVES hardware, or compromise...";
CM_ BO_ 2633675518 "High Voltage Energy Storage Pack 7 History";
CM_ SG_ 2633675518 Hvesp7StateOfHealth "HVESP7 State of Health: This signal represents the expected remaining Life of this High Voltage Energy Storage Pack instance, in percent.  Battery life is a manufacturer-specific measure of how well the energy storage system is functioning relative t...";
CM_ SG_ 2633675518 Hvesp7TotalEnergyThroughput "HVESP7 Total Energy Throughput: The total energy throughput which has flowed through this High Voltage Energy Storage Pack instance.  This parameter is the sum of the absolute values of the Energy into and out of this HVES instance.  This parameter i...";
CM_ SG_ 2633675518 Hvesp7TotalAccumulatedCharge "HVESP7 Total Accumulated Charge: The total accumulated amp hours which have flowed through this High Voltage Energy Storage Pack instance.  This parameter is the sum of the absolute values of the Ampere hours into and out of this HVES instance.  This...";
CM_ SG_ 2633675518 Hvesp7TotalLifetimeEnergyInput "HVESP7 Total Lifetime Energy Input: The cumulative energy which has flowed into this High Voltage Energy Storage Pack instance over the lifetime of the battery pack. This parameter is the sum of the Energy into this HVES instance. This value is reset...";
CM_ SG_ 2633675518 Hvesp7TotalLifetimeEnergyOutput "HVESP7 Total Lifetime Energy Output: The cumulative energy which has flowed out of this High Voltage Energy Storage Pack instance over the lifetime of the battery pack. This parameter is the sum of the Energy out of this HVES instance. This value is ...";
CM_ SG_ 2633675518 Hvsp7CnttrOpnUndrLdCnt "HVESP7 Contactor Open Under Load Count: This signal represents the number of times the contactors inside this High Voltage Energy Storage Pack instance have opened while current is flowing through them.  The current level (that determines if an openi...";
CM_ BO_ 2566567166 "EV DC Charging Limits 1";
CM_ SG_ 2566567166 HrdOrEvDChrgngVltgMxmm "Hybrid or EV DC Charging Voltage Maximum: Hybrid or Electric Vehicle's maximum allowed DC charging input voltage.This is communicated to a DC EVSE during initial exchange of parameters and may optionally be dynamically updated during charging.When ch...";
CM_ SG_ 2566567166 HrdOrEvDChrgngCrrntMxmm "Hybrid or EV DC Charging Current Maximum: Hybrid or Electric Vehicle's maximum rated DC charging input current.This is communicated to a DC EVSE during initial exchange of parameters and may optionally be dynamically updated during charging.When char...";
CM_ SG_ 2566567166 HrdOrEvDChrgngPwrMxmm "Hybrid or EV DC Charging Power Maximum: Hybrid or Electric Vehicle's maximum rated DC charging input power.This is communicated to a DC EVSE during initial exchange of parameters and may optionally be dynamically updated during charging.When charging...";
CM_ SG_ 2566567166 HrdOrEvRqstdEnrgTrnsfrTp "Hybrid or EV requested Energy Transfer Type: Hybrid  or Electric vehicle's required Energy transfer type0000b = DC-Extended0001b = DC-Core0010b = Reserved0011b = Reserved0100b = Reserved0101b = Reserved0110b = Reserved0111b = Reserved1000b = Reserved...";
CM_ BO_ 2566567422 "EVSE DC Charging Limits 1";
CM_ SG_ 2566567422 EvseDcChargingVoltageMaximum "EVSE DC Charging Voltage Maximum: EVSE's maximum rated DC output voltage.This is communicated to the hybrid vehicle or EV during initial exchange of parameters.When charging, the smallest value of this and SPN 13155 (Hybrid or EV DC Charging Voltage ...";
CM_ SG_ 2566567422 EvseDcChargingCurrentMaximum "EVSE DC Charging Current Maximum: EVSE's maximum rated DC output current.This is communicated to the hybrid vehicle or EV during initial exchange of parameters.When charging, the smallest value of this and SPN 13156 (Hybrid or EV DC Charging Current ...";
CM_ SG_ 2566567422 EvseDcChargingPowerMaximum "EVSE DC Charging Power Maximum: EVSE's maximum rated DC output power.This is communicated to the hybrid vehicle or EV during initial exchange of parameters.When charging, the smallest value of this and SPN 13157 (Hybrid or EV DC Charging Power Maximu...";
CM_ SG_ 2566567422 EvsSpprtdEnrgTrnsfrTps "EVSE Supported Energy Transfer Types: Energy transfer types supported by the EVSE0000b = DC-Extended0001b = DC-Core0010b = AC-Single-phase-core0011b = AC-three-phase-core0100b = Reserved0101b = Reserved0110b = Reserved0111b = Reserved1000b = Reserved...";
CM_ BO_ 2566567678 "EVSE DC Charging Limits 2";
CM_ SG_ 2566567678 EvseDcChargingVoltageMinimum "EVSE DC Charging Voltage Minimum: Minimum stable DC output voltage that can be supplied by the EVSE.FB00h = Parameter supported, but no value provided by EVSESee J2847-2 201504 Sect 4.2.46";
CM_ SG_ 2566567678 EvseDcChargingCurrentMinimum "EVSE DC Charging Current Minimum: Minimum stable DC output current that can be supplied by the EVSE.FB00h = Parameter supported, but no value provided by EVSESee J2847-2 201504 Sect 4.2.45";
CM_ SG_ 2566567678 EvsePeakCurrentRipple "EVSE Peak Current Ripple: Maximum peak to peak ripple current amplitude on the EVSE output.FB00h = Parameter supported, but no value provided by EVSESee J2847-2 201504 Sect 4.2.48";
CM_ SG_ 2566567678 EvseCurrentRegulationTolerance "EVSE Current Regulation Tolerance: Regulated current tolerance of the EVSE.FB00h = Parameter supported, but no tolerance provided by EVSESee J2847-2 201504 Sect 4.2.38";
CM_ BO_ 2566567934 "EV DC Charging Target";
CM_ SG_ 2566567934 DcChargingTargetCrc "DC Charging Target CRC: The CRC is defined as follows: - Length: 8 bits- Polynomial: x^8+x^5+x^3+x^2+x+1- Initial Value: FFh- Input Data Reflection: Not reflected- Result Data Reflection: Not reflected- XOR value: FFh SAE makes no claim of the functi...";
CM_ SG_ 2566567934 DcChargingTargetSequenceCounter "DC Charging Target Sequence Counter: The message counter is used to detect situations where the transmitting ECU malfunction repeats the same frame all the time. The receiver of the information may use the counter parameter to detect this situation. ...";
CM_ SG_ 2566567934 DcTargetChargingVoltage "DC Target Charging Voltage: Hybrid or Electric vehicle's instantaneous requested DC output voltage limit.See also: SPN 13159 (EVSE DC Charging Voltage Maximum) SPN 13163 (EVSE DC Charging Voltage Minimum) SPN 13155 (Hybrid DC Charging Voltage Maximum...";
CM_ SG_ 2566567934 DcTargetChargingCurrent "DC Target Charging Current: Hybrid or Electric vehicle's instantaneous requested DC output current limit.See also: SPN 13160 (EVSE DC Charging Current Maximum) SPN 13164 (EVSE DC Charging Current Minimum) SPN 13156 (Hybrid DC Charging Current Maximum...";
CM_ BO_ 2566568190 "EVSE DC Status 1";
CM_ SG_ 2566568190 EvseDcChargingState "EVSE DC Charging State: Overall State of the DC charging system0 = Idle. No EVSE connected1 = Charging2 = Standby3 = Reserved4 = Power Delivery (Start-up)5 = Authorizing.  A sub-state of Initializing that could take significant time, therefore the EV...";
CM_ SG_ 2566568190 EvseIsolationStatus "EVSE Isolation Status: Isolation Status as returned from this instance of EVSE.The EVSE checks its internal isolation during the Cable Check phase of establishing the DC connection. On completion of the cable check, the value would change from 14 to ...";
CM_ SG_ 2566568190 EvsePresentDcChargingVoltage "EVSE Present DC Charging Voltage: High Voltage DC voltage at the output of the EVSE as measured by the EVSEFB00h = Parameter supported, but no voltage provided by EVSESee J2847-2 201504 Sect 4.2.50";
CM_ SG_ 2566568190 EvsePresentDcChargingCurrent "EVSE Present DC Charging Current: High Voltage DC current at the output of the EVSE as measured by the EVSE FB00h = Parameter supported, but no current provided by EVSESee J2847-2 201504 Sect 4.2.51";
CM_ SG_ 2566568190 EvseVoltageLimitAchieved "EVSE Voltage Limit Achieved: Indicates if the output voltage from the EVSE has reached the negotiated voltage limit as determined by SPN 13159 (EVSE DC Charging Voltage Maximum) and SPN 13155 (Hybrid or EV DC Charging Voltage Maximum).00b = Not limit...";
CM_ SG_ 2566568190 EvseCurrentLimitAchieved "EVSE Current Limit Achieved: Indicates if the output current from the EVSE has reached the negotiated current limit as determined by SPN 13160 (EVSE DC Charging Current Maximum) and SPN 13156 (Hybrid or EV DC Charging Current Maximum).00b = Not limit...";
CM_ SG_ 2566568190 EvsePowerLimitAchieved "EVSE Power Limit Achieved: Indicates if the output power from the EVSE has reached the negotiated power limit as determined by the lower of SPN 13161 (EVSE DC Charging Power Maximum) and SPN 13157 (Hybrid or EV DC Charging Power Maximum).00b = Not li...";
CM_ SG_ 2566568190 EvseProcessingState "EVSE Processing State: The progress of the EVSE within its current DC Charging State, as reported by SPN 13171.For example, if the EVSE is doing a cable check SPN 13171 = 9, Cable check and this SP will indicate 01b, Ongoing. On completion of the cab...";
CM_ SG_ 2566568190 EvseStatus "EVSE Status: Status of the DC EVSE as returned from the EVSE0 = EVSE Not Ready1 = EVSE Ready2 = EVSE Shutdown3 = Utility Interrupt Event4 = Isolation Monitoring Active5 = Emergency Shutdown6 = Malfunction7 = Reserved8 = Reserved9 = Reserved10 = Reser...";
CM_ SG_ 2566568190 EvseResponseCode "EVSE Response Code: The response code of the EVSE to the last request from the EV.Typically the values are only significant once current operation progress indicates FinishedSee J2847-2 201504 Sect 4.2.780 = OK1 = OK New Session Established2 = OK Old...";
CM_ BO_ 2566568446 "EVSE 1 Contactor Cmd 1";
CM_ SG_ 2566568446 HrdOrEvDInltCnttr1Cmmnd "Hybrid or EV DC Inlet Contactor 1 Command: Contactor command.00b = Open Contactor01b = Close Contactor10b = Reserved11b = Don't Care / Take no action";
CM_ BO_ 2566568702 "EVSE 1 Contactor Status 1";
CM_ SG_ 2566568702 HrdOrEvDCnttrInptVltg "Hybrid or EV DC Contactor Input Voltage: Voltage measured on the inlet side of the DC Charging Inlet Contactors. If provided, this value should be in agreement with SPN 13172 (EVSE Present DC Charging Voltage).";
CM_ SG_ 2566568702 HybridOrEvDcChargingBusVoltage "Hybrid or EV DC Charging Bus Voltage: Voltage measured on the HVES side of the DC Charging Inlet Contactors.";
CM_ SG_ 2566568702 HrdOrEvDInltCnttr1Stt "Hybrid or EV DC Inlet Contactor 1 State: Indicates the state of DC Inlet Contactor 1.00b = Contactor Open01b = Contactor Closed10b = Error- Contactor fault detected11b = Not available";
CM_ BO_ 2566568958 "Direct Lamp Control Command 3";
CM_ SG_ 2566568958 TrnsmssnOlTmprtrHghLmpCmmnd "Transmission Oil Temperature High Lamp Command: Command signal directly controlling the Transmission Oil Temperature Lamp.00b = Lamp Off01b = Lamp On10b = Reserved11b = Not available";
CM_ SG_ 2566568958 TrnsmssnOlPrssrLwLmpCmmnd "Transmission Oil Pressure Low Lamp Command: Command signal directly controlling the Transmission Oil Pressure Lamp.00b = Lamp Off01b = Lamp On10b = Reserved11b = Not available";
CM_ BO_ 2566569214 "Direct Lamp Control Data 3";
CM_ SG_ 2566569214 TrnsmssnOlTmprtrHghLmpDt "Transmission Oil Temperature High Lamp Data: This parameter provides measured data from the Transmission Oil Temperature Lamp.00b = Lamp deactivated (Off)01b = Lamp activated (On)10b = Error11b = Not available";
CM_ SG_ 2566569214 TrnsmssnOlPrssrLwLmpDt "Transmission Oil Pressure Low Lamp Data: This parameter provides measured data from the Transmission Oil Pressure Lamp.00b = Lamp deactivated (Off)01b = Lamp activated (On)10b = Error11b = Not available";
CM_ BO_ 2566569470 "Motor/Generator 1 Lifetime Data";
CM_ SG_ 2566569470 MtrGnrtr1TtlEnrgCnsmd "Motor/Generator 1 Total Energy Consumed: Indicates the total lifetime energy consumed by this Motor/Generator.  For example, this would include the energy used for propulsion in a propulsion motor.";
CM_ SG_ 2566569470 MtrGnrtr1TtlEnrgGnrtd "Motor/Generator 1 Total Energy Generated : Indicates the total lifetime energy generated by this Motor/Generator.  For example, this would include the energy created during regerative braking in a propulsion motor.";
CM_ SG_ 2566569470 MtrGnrtr1TtlChrgCnsmd "Motor/Generator 1 Total Charge Consumed: Indicates the total lifetime charge consumed by this Motor/Generator.  For example, this would include the charge used for propulsion in a propulsion motor.";
CM_ SG_ 2566569470 MtrGnrtr1TtlChrgGnrtd "Motor/Generator 1 Total Charge Generated: Indicates the total lifetime charge generated by this Motor/Generator.  For example, this would include the charge created during regerative braking in a propulsion motor.";
CM_ BO_ 2566569726 "Motor/Generator 2 Lifetime Data";
CM_ SG_ 2566569726 MtrGnrtr2TtlEnrgCnsmd "Motor/Generator 2 Total Energy Consumed: Indicates the total lifetime energy consumed by this Motor/Generator.  For example, this would include the energy used for propulsion in a propulsion motor.";
CM_ SG_ 2566569726 MtrGnrtr2TtlEnrgGnrtd "Motor/Generator 2 Total Energy Generated : Indicates the total lifetime energy generated by this Motor/Generator.  For example, this would include the energy created during regerative braking in a propulsion motor.";
CM_ SG_ 2566569726 MtrGnrtr2TtlChrgCnsmd "Motor/Generator 2 Total Charge Consumed: Indicates the total lifetime charge consumed by this Motor/Generator.  For example, this would include the charge used for propulsion in a propulsion motor.";
CM_ SG_ 2566569726 MtrGnrtr2TtlChrgGnrtd "Motor/Generator 2 Total Charge Generated: Indicates the total lifetime charge generated by this Motor/Generator.  For example, this would include the charge created during regerative braking in a propulsion motor.";
CM_ BO_ 2566569982 "Motor/Generator 3 Lifetime Data";
CM_ SG_ 2566569982 MtrGnrtr3TtlEnrgCnsmd "Motor/Generator 3 Total Energy Consumed: Indicates the total lifetime energy consumed by this Motor/Generator.  For example, this would include the energy used for propulsion in a propulsion motor.";
CM_ SG_ 2566569982 MtrGnrtr3TtlEnrgGnrtd "Motor/Generator 3 Total Energy Generated : Indicates the total lifetime energy generated by this Motor/Generator.  For example, this would include the energy created during regerative braking in a propulsion motor.";
CM_ SG_ 2566569982 MtrGnrtr3TtlChrgCnsmd "Motor/Generator 3 Total Charge Consumed: Indicates the total lifetime charge consumed by this Motor/Generator.  For example, this would include the charge used for propulsion in a propulsion motor.";
CM_ SG_ 2566569982 MtrGnrtr3TtlChrgGnrtd "Motor/Generator 3 Total Charge Generated: Indicates the total lifetime charge generated by this Motor/Generator.  For example, this would include the charge created during regerative braking in a propulsion motor.";
CM_ BO_ 2566570238 "Motor/Generator 4 Lifetime Data";
CM_ SG_ 2566570238 MtrGnrtr4TtlEnrgCnsmd "Motor/Generator 4 Total Energy Consumed: Indicates the total lifetime energy consumed by this Motor/Generator.  For example, this would include the energy used for propulsion in a propulsion motor.";
CM_ SG_ 2566570238 MtrGnrtr4TtlEnrgGnrtd "Motor/Generator 4 Total Energy Generated : Indicates the total lifetime energy generated by this Motor/Generator.  For example, this would include the energy created during regerative braking in a propulsion motor.";
CM_ SG_ 2566570238 MtrGnrtr4TtlChrgCnsmd "Motor/Generator 4 Total Charge Consumed: Indicates the total lifetime charge consumed by this Motor/Generator.  For example, this would include the charge used for propulsion in a propulsion motor.";
CM_ SG_ 2566570238 MtrGnrtr4TtlChrgGnrtd "Motor/Generator 4 Total Charge Generated: Indicates the total lifetime charge generated by this Motor/Generator.  For example, this would include the charge created during regerative braking in a propulsion motor.";
CM_ BO_ 2566570494 "Motor/Generator 5 Lifetime Data";
CM_ SG_ 2566570494 MtrGnrtr5TtlEnrgCnsmd "Motor/Generator 5 Total Energy Consumed: Indicates the total lifetime energy consumed by this Motor/Generator.  For example, this would include the energy used for propulsion in a propulsion motor.";
CM_ SG_ 2566570494 MtrGnrtr5TtlEnrgGnrtd "Motor/Generator 5 Total Energy Generated : Indicates the total lifetime energy generated by this Motor/Generator.  For example, this would include the energy created during regerative braking in a propulsion motor.";
CM_ SG_ 2566570494 MtrGnrtr5TtlChrgCnsmd "Motor/Generator 5 Total Charge Consumed: Indicates the total lifetime charge consumed by this Motor/Generator.  For example, this would include the charge used for propulsion in a propulsion motor.";
CM_ SG_ 2566570494 MtrGnrtr5TtlChrgGnrtd "Motor/Generator 5 Total Charge Generated: Indicates the total lifetime charge generated by this Motor/Generator.  For example, this would include the charge created during regerative braking in a propulsion motor.";
CM_ BO_ 2566570750 "Motor/Generator 6 Lifetime Data";
CM_ SG_ 2566570750 MtrGnrtr6TtlEnrgCnsmd "Motor/Generator 6 Total Energy Consumed: Indicates the total lifetime energy consumed by this Motor/Generator.  For example, this would include the energy used for propulsion in a propulsion motor.";
CM_ SG_ 2566570750 MtrGnrtr6TtlEnrgGnrtd "Motor/Generator 6 Total Energy Generated : Indicates the total lifetime energy generated by this Motor/Generator.  For example, this would include the energy created during regerative braking in a propulsion motor.";
CM_ SG_ 2566570750 MtrGnrtr6TtlChrgCnsmd "Motor/Generator 6 Total Charge Consumed: Indicates the total lifetime charge consumed by this Motor/Generator.  For example, this would include the charge used for propulsion in a propulsion motor.";
CM_ SG_ 2566570750 MtrGnrtr6TtlChrgGnrtd "Motor/Generator 6 Total Charge Generated: Indicates the total lifetime charge generated by this Motor/Generator.  For example, this would include the charge created during regerative braking in a propulsion motor.";
CM_ BO_ 2566571006 "Air Supply Pressure 3";
CM_ SG_ 2566571006 AirDryerCartridgeLifeRemaining "Air Dryer Cartridge Life Remaining: The air dryer cartridge life remaining based on compressor air processed through the desiccant material.  100% life remaining indicates a new or fresh air dryer cartridge and 0% life remaining indicates a worn air ...";
CM_ SG_ 2566571006 AirSuspensionSupplyPressure2 "Air Suspension Supply Pressure 2: The pneumatic pressure in the second circuit for the electronically controlled air suspension system.";
CM_ BO_ 2566571262 "EVSE AC Supply Voltage";
CM_ SG_ 2566571262 EvseNominalRmsVoltageLineToLine "EVSE Nominal RMS voltage Line to Line: Indicates the nominal line to line RMS voltage.  For single phase supplies this is set to Not Available.";
CM_ SG_ 2566571262 EvseNominalSupplyFrequency "EVSE Nominal Supply Frequency: Indicates the supply frequency.00h = 50 Hz02h = 60 Hz03h - FDh = ReservedFEh = ErrorFFh = Not available";
CM_ SG_ 2566571262 EvsNmnlRmsVltgLnTNtrl "EVSE Nominal RMS voltage Line to Neutral: Indicates the nominal RMS voltage between contacts L1 and Neutral.For 3-phase supplies the same nominal line to neutral voltage is assumed for L2 and L3";
CM_ BO_ 2566571518 "EVSE AC 3-Phase Load";
CM_ SG_ 2566571518 HvessChargerRmsCurrentL1 "HVESS Charger RMS current L1: Current presently being drawn from a single phase EVSE or from L1 of a three phase supply.";
CM_ SG_ 2566571518 HvessChargerRmsCurrentL2 "HVESS Charger RMS current L2: Current presently being drawn from L2 of a three phase supply.";
CM_ SG_ 2566571518 HvessChargerRmsCurrentL3 "HVESS Charger RMS current L3: Current presently being drawn from L3 of a three phase supply.";
CM_ SG_ 2566571518 HvessChargerNeutralRmsCurrent "HVESS Charger Neutral RMS current: Current flowing through the neutral connection.For a balanced 3-phase load this value will be set to 0 A.If the HVESS charger is only drawing single phase current between L1 and neutral then this parameter will have...";
CM_ BO_ 2499462910 "Electronic Retarder Controller 3";
CM_ SG_ 2499462910 RtrdrRdSpdDlrtSwth "Retarder Road Speed Decelerate Switch: Switch signal of the retarder road speed activator which indicates that the activator is in the position decelerate.00b = Retarder road speed activator not in the position decelerate01b = Retarder road speed act...";
CM_ SG_ 2499462910 RtrdrRdSpdAlrtSwth "Retarder Road Speed Accelerate Switch: Switch signal of the retarder road speed activator which indicates that the activator is in the position accelerate.00b = Retarder road speed activator not in the position accelerate01b = Retarder road speed act...";
CM_ BO_ 2566572286 "Electronic Transmission Controller 14";
CM_ SG_ 2566572286 TransmissionClutch1Temperature "Transmission Clutch 1 Temperature: Indicates temperature of the transmission clutch 1. This is typically the primary transmission input clutch.";
CM_ SG_ 2566572286 TrnsmssnClth1OvrhtIndtr "Transmission Clutch 1 Overheat Indicator: Signal used to indicate the transmission clutch 1 temperature is above normal acceptable limits.  Transmission clutch 1 is typically the primary transmission input clutch.00b = Clutch overheat indicator is of...";
CM_ SG_ 2566572286 TransmissionLaunchCapability "Transmission Launch Capability: Indicates whether the transmission has the current operational capability to launch the vehicle from stationary. The capability may be degraded due to a component failure or temporary fault condition (such as low air p...";
CM_ SG_ 2566572286 TransmissionGearShiftCapability "Transmission Gear Shift Capability: Indicates whether the transmission has the operational capability to shift gears when the vehicle is moving. The capability may be degraded due to a component failure (e.g. failed clutch mechanism or hydraulic sole...";
CM_ SG_ 2566572286 TrnsmssnDmgThrshldStts "Transmission Damage Threshold Status: Indicates whether the transmission has exceeded a damage threshold. This information may be important to an Automated Driving System (ADS) so that it can determine its plan of action, e.g. limit an extreme operat...";
CM_ BO_ 2499464702 "Aftertreatment 1 SCR Exhaust Gas Pressures 2";
CM_ SG_ 2499464702 Aftrtrtmnt1SrOtltAsltPrssr "Aftertreatment 1 SCR Outlet Absolute Pressure: The pressure at the catalyst outlet of the selective catalytic reduction system of aftertreatment 1.";
CM_ SG_ 2499464702 Aftrtrtmnt1SrOtltPrssr "Aftertreatment 1 SCR Outlet Pressure: The gage pressure at the outlet of the selective catalytic reduction system of Aftertreatment 1.";
CM_ BO_ 2566573822 "PTO Information 2";
CM_ SG_ 2566573822 TransmissionPtoGearboxStatus "Transmission PTO Gearbox Status: Feedback from the PTO gearbox driven by the transmission PTO.0000b = Neutral0001b = 1st range, or Low in a 2-speed gearbox0010b = 2nd range, or High in a 2-speed gearbox0011b = 3rd range0100b = 4th range0101b = Reserv...";
CM_ SG_ 2566573822 TrnsmssnPtGrxOtptShftSpd "Transmission PTO Gearbox Output Shaft Speed: Output shaft speed of a PTO gearbox driven by the transmission PTO.";
CM_ BO_ 2364690686 "Electronic Auxiliary Transmission Controller 1";
CM_ SG_ 2364690686 AxlrTrnsmssnOtptSpd "Auxiliary Transmission Output Speed: Auxiliary transmission output speed";
CM_ BO_ 2566563326 "Dual Fuel Mode 3";
CM_ SG_ 2566563326 BddDFMdEsttdIsttsFSvsRt "Blended Dual Fuel Mode Estimated Instantaneous Fuel Savings Rate: Estimated instantaneous fuel savings rate while operating in blended dual fuel mode.  This is in comparison to operating in diesel only mode.";
CM_ SG_ 2566563326 BlnddDlFlMdOprtngStts "Blended Dual Fuel Mode Operating Status: Indicates the current blended dual fuel mode operating state.0000b = Disabled by Configuration0001b = Operator Disabled0010b = Automatically Disabled and Locked0011b = Temporarily Disabled Due to Current Condi...";
CM_ SG_ 2566563326 BlendedDualFuelModeStatusReason "Blended Dual Fuel Mode Status Reason: Indicates the current status reason of the blended dual fuel mode while the engine is operating.00000000b = Not Requested00000001b = Diagnostic Trouble Code Active00000010b = Engine Speed Too Low00000011b = Engin...";
CM_ BO_ 2566563582 "Dual Fuel Mode 2";
CM_ SG_ 2566563582 BlnddDlFlMdTtlDslFlDmnd "Blended Dual Fuel Mode Total Diesel Fuel Demand: Accumulated amount of liquid fuel that would have been used during engine operation, including actual diesel fuel used and the diesel fuel that was displaced by gaseous fuel.";
CM_ SG_ 2566563582 BlnddDlFlMdTtlDslFlDspldBGssFl "Blended Dual Fuel Mode Total Diesel Fuel Displaced by Gaseous Fuel: Accumulated total amount of diesel fuel displaced on blended dual fuel applications.";
CM_ BO_ 2566563838 "Dual Fuel Mode 1";
CM_ SG_ 2566563838 BlnddDlFlMdTtlDslFlUsd "Blended Dual Fuel Mode Total Diesel Fuel Used: Accumulated total amount of diesel fuel used by a dual fuel engine while fuel is being blended.Use SPN 7597 for accumulated amount of actual diesel fuel used and the diesel fuel that was displaced by gas...";
CM_ SG_ 2566563838 BlnddDlFlMdTtlDslFlPrntDspld "Blended Dual Fuel Mode Total Diesel Fuel Percent Displaced: Percent of total quantity of diesel fuel that was displaced by an engine when gaseous fuel was substituted for a portion of diesel fuel in blended dual fuel mode. This is calculated using to...";
CM_ SG_ 2566563838 BlnddDlFlMdPrntTmAtv "Blended Dual Fuel Mode Percent Time Active: The percentage of accumulated hours the engine has run in blended dual fuel mode.This value is calculated by dividing dual fuel active time by engine run time * 100.";
CM_ SG_ 2566563838 BlnddDlFlMdDslFlPrntDspld "Blended Dual Fuel Mode Diesel Fuel Percent Displaced: Percent of total diesel fuel displaced in a blended dual fuel application.0% = No diesel fuel displaced. 100% = All amount of diesel fuel is being displaced.";
CM_ SG_ 2566563838 BddDFMdEsttdIsttsDsSvsRtPt "Blended Dual Fuel Mode Estimated Instantaneous Diesel Savings Rate Percentage: Estimated instantaneous diesel fuel savings rate percentage while operating in blended dual fuel mode.This value is calculated by dividing the Blended Dual Fuel Mode Estim...";
CM_ BO_ 2566564094 "Transmission 1 History";
CM_ SG_ 2566564094 Trnsmssn1TtlOtptShftRvltns "Transmission 1 Total Output Shaft Revolutions: Accumulated number of transmission 1 output shaft revolutions during its operation.";
CM_ SG_ 2566564094 Trnsmssn1OprtnTmSnRld "Transmission 1 Operation Time Since Rebuild: The estimated or actual amount of transmission 1 operation time since the last transmission rebuild.";
CM_ SG_ 2566564094 Trnsmssn1TtlHrsOfOprtn "Transmission 1 Total Hours of Operation: Accumulated time of transmission operation.";
CM_ BO_ 2566564350 "Transmission Shaft Twist Information";
CM_ SG_ 2566564350 Trnsmssn1InptShftPkTwst "Transmission 1 Input Shaft Peak Twist: Indicates the maximum dynamic twist angle observed during a sample period for the transmission 1 input shaft. The broadcast value is always the largest twist displacement (regardless of positive or negative dire...";
CM_ SG_ 2566564350 Trnsmssn1OtptShftPkTwst "Transmission 1 Output Shaft Peak Twist: Indicates the maximum dynamic twist angle observed during a sample period for the transmission 1 output shaft. The broadcast value is always the largest twist displacement (regardless of positive or negative di...";
CM_ SG_ 2566564350 Trnsmssn1IntrmdtShftPkTwst "Transmission 1 Intermediate Shaft Peak Twist: Indicates the maximum dynamic twist angle observed during a sample period for the first instance of a transmission 1 intermediate shaft, as designated by the transmission manufacturer. The broadcast value...";
CM_ BO_ 2566564606 "Electronic Auxiliary Transmission Controller 2";
CM_ SG_ 2566564606 AxlrTrnsmssnSltdGr "Auxiliary Transmission Selected Gear: The gear that the auxiliary transmission will attempt to achieve during the current shift if a shift is in progress, or the next shift if one is pending (i.e., waiting for torque reduction to initiate the shift)....";
CM_ SG_ 2566564606 AxlrTrnsmssnCrrntGr "Auxiliary Transmission Current Gear: The gear currently engaged in the auxiliary transmission or the last gear engaged while the auxiliary transmission is in the process of shifting to the new or selected gear.  Transitions toward a destination gear ...";
CM_ BO_ 2349858558 "High Voltage Energy Storage Pack 11 Control 1";
CM_ SG_ 2349858558 Hvsp11HghVltgBsCnntCmmnd "HVESP11 High-Voltage Bus Connect Command: Command to connect this High Voltage Energy Storage Pack instance to the high-voltage bus.  The emergency contactor closure request may be used in situations where one or more faults in the hybrid or EV power...";
CM_ SG_ 2349858558 Hvesp11PowerDownCommand "HVESP11 Power-Down Command: Command to shut down this High Voltage Energy Storage Pack instance.  A normal power-down may involve steps that take some period of time (tests, writing of data, etc.).  However, an emergency power-down should shut down t...";
CM_ SG_ 2349858558 Hvsp11HghVltgBsAtvIsltnTstCmmnd "HVESP11 High-Voltage Bus Active Isolation Test Command: Command for this High Voltage Energy Storage Pack instance to perform an active electrical isolation test on the high voltage bus.An active isolation test might use a generated signal (e.g. an i...";
CM_ SG_ 2349858558 Hvsp11HVtBsPssvIstTstCd "HVESP11 High-Voltage Bus Passive Isolation Test Command: Command for this High Voltage Energy Storage Pack instance to perform a passive electrical isolation test on the high voltage bus.A passive isolation test uses additional circuitry (e.g. a high...";
CM_ SG_ 2349858558 Hvesp11CellBalancingCommand "HVESP11 Cell Balancing Command: Command for this High Voltage Energy Storage Pack instance to perform cell balancing.This parameter is for one of multiple packs in an HVESS.  If there is only one pack in the system, the HVESS parameters should be use...";
CM_ SG_ 2349858558 Hvsp11EnlIntrnlChrgrCmmnd "HVESP11 Enable Internal Charger Command: When the HVES has an internal charger this parameter will enable it.   External chargers may use the External Energy Source Connection Demand (SPN 7890) and related SPs.This parameter is for one of multiple pa...";
CM_ SG_ 2349858558 Hvesp11OperationConsent "HVESP11 Operation Consent: This parameter provides an indication to this High Voltage Energy Storage Pack instance that an external device is ready for this HVES instance to proceed with normal operation.  In applications which support this parameter...";
CM_ SG_ 2349858558 Hvsp11HVtBsHSdRsstCtRqst "HVESP11 High-Voltage Bus High Side Resistor Connect Request: This parameter is used to request connection of this HVES instance High-Voltage bus high side resistor in order to perform an isolation test. See also SPN 15277 (HVESP11 High-Voltage Bus Lo...";
CM_ SG_ 2349858558 Hvsp11HVtBsLwSdRsstCtRqst "HVESP11 High-Voltage Bus Low Side Resistor Connect Request: This parameter is used to request connection of this HVES instance High-Voltage bus low side resistor in order to perform an isolation test. See also SPN 15276 (HVESP11 High-Voltage Bus High...";
CM_ SG_ 2349858558 Hvsp11ThrmlMngmntMntnnRqst "HVESP11 Thermal Management Maintenance Request: Request to engage Thermal Management Maintenance Mode for this High Voltage Energy Storage System Pack instance.00b = HVESS Thermal Management Maintenance Mode is not requested01b = HVESS Thermal Manage...";
CM_ SG_ 2349858558 Hvesp11Control1Counter "HVESP11 Control 1 Counter: The message counter is used to detect situations where the transmitting ECU malfunction repeats the same frame all the time. The receiver of the information may use the counter parameter to detect this situation. The transm...";
CM_ SG_ 2349858558 Hvesp11Control1Crc "HVESP11 Control 1 CRC: The CRC is defined as follows: - Length: 8 bits- Polynomial: x^8+x^5+x^3+x^2+x+1- Initial Value: FFh- Input Data Reflection: Not reflected- Result Data Reflection: Not reflected- XOR value: FFh SAE makes no claim of the functio...";
CM_ BO_ 2349924094 "High Voltage Energy Storage Pack 12 Control 1";
CM_ SG_ 2349924094 Hvsp12HghVltgBsCnntCmmnd "HVESP12 High-Voltage Bus Connect Command: Command to connect this High Voltage Energy Storage Pack instance to the high-voltage bus.  The emergency contactor closure request may be used in situations where one or more faults in the hybrid or EV power...";
CM_ SG_ 2349924094 Hvesp12PowerDownCommand "HVESP12 Power-Down Command: Command to shut down this High Voltage Energy Storage Pack instance.  A normal power-down may involve steps that take some period of time (tests, writing of data, etc.).  However, an emergency power-down should shut down t...";
CM_ SG_ 2349924094 Hvsp12HghVltgBsAtvIsltnTstCmmnd "HVESP12 High-Voltage Bus Active Isolation Test Command: Command for this High Voltage Energy Storage Pack instance to perform an active electrical isolation test on the high voltage bus.An active isolation test might use a generated signal (e.g. an i...";
CM_ SG_ 2349924094 Hvsp12HVtBsPssvIstTstCd "HVESP12 High-Voltage Bus Passive Isolation Test Command: Command for this High Voltage Energy Storage Pack instance to perform a passive electrical isolation test on the high voltage bus.A passive isolation test uses additional circuitry (e.g. a high...";
CM_ SG_ 2349924094 Hvesp12CellBalancingCommand "HVESP12 Cell Balancing Command: Command for this High Voltage Energy Storage Pack instance to perform cell balancing.This parameter is for one of multiple packs in an HVESS.  If there is only one pack in the system, the HVESS parameters should be use...";
CM_ SG_ 2349924094 Hvsp12EnlIntrnlChrgrCmmnd "HVESP12 Enable Internal Charger Command: When the HVES has an internal charger this parameter will enable it.   External chargers may use the External Energy Source Connection Demand (SPN 7890) and related SPs.This parameter is for one of multiple pa...";
CM_ SG_ 2349924094 Hvesp12OperationConsent "HVESP12 Operation Consent: This parameter provides an indication to this High Voltage Energy Storage Pack instance that an external device is ready for this HVES instance to proceed with normal operation.  In applications which support this parameter...";
CM_ SG_ 2349924094 Hvsp12HVtBsHSdRsstCtRqst "HVESP12 High-Voltage Bus High Side Resistor Connect Request: This parameter is used to request connection of this HVES instance High-Voltage bus high side resistor in order to perform an isolation test. See also SPN 15419 (HVESP12 High-Voltage Bus Lo...";
CM_ SG_ 2349924094 Hvsp12HVtBsLwSdRsstCtRqst "HVESP12 High-Voltage Bus Low Side Resistor Connect Request: This parameter is used to request connection of this HVES instance High-Voltage bus low side resistor in order to perform an isolation test. See also SPN 15418 (HVESP12 High-Voltage Bus High...";
CM_ SG_ 2349924094 Hvsp12ThrmlMngmntMntnnRqst "HVESP12 Thermal Management Maintenance Request: Request to engage Thermal Management Maintenance Mode for this High Voltage Energy Storage System Pack instance.00b = HVESS Thermal Management Maintenance Mode is not requested01b = HVESS Thermal Manage...";
CM_ SG_ 2349924094 Hvesp12Control1Counter "HVESP12 Control 1 Counter: The message counter is used to detect situations where the transmitting ECU malfunction repeats the same frame all the time. The receiver of the information may use the counter parameter to detect this situation. The transm...";
CM_ SG_ 2349924094 Hvesp12Control1Crc "HVESP12 Control 1 CRC: The CRC is defined as follows: - Length: 8 bits- Polynomial: x^8+x^5+x^3+x^2+x+1- Initial Value: FFh- Input Data Reflection: Not reflected- Result Data Reflection: Not reflected- XOR value: FFh SAE makes no claim of the functio...";
CM_ BO_ 2349989630 "High Voltage Energy Storage Pack 13 Control 1";
CM_ SG_ 2349989630 Hvsp13HghVltgBsCnntCmmnd "HVESP13 High-Voltage Bus Connect Command: Command to connect this High Voltage Energy Storage Pack instance to the high-voltage bus.  The emergency contactor closure request may be used in situations where one or more faults in the hybrid or EV power...";
CM_ SG_ 2349989630 Hvesp13PowerDownCommand "HVESP13 Power-Down Command: Command to shut down this High Voltage Energy Storage Pack instance.  A normal power-down may involve steps that take some period of time (tests, writing of data, etc.).  However, an emergency power-down should shut down t...";
CM_ SG_ 2349989630 Hvsp13HghVltgBsAtvIsltnTstCmmnd "HVESP13 High-Voltage Bus Active Isolation Test Command: Command for this High Voltage Energy Storage Pack instance to perform an active electrical isolation test on the high voltage bus.An active isolation test might use a generated signal (e.g. an i...";
CM_ SG_ 2349989630 Hvsp13HVtBsPssvIstTstCd "HVESP13 High-Voltage Bus Passive Isolation Test Command: Command for this High Voltage Energy Storage Pack instance to perform a passive electrical isolation test on the high voltage bus.A passive isolation test uses additional circuitry (e.g. a high...";
CM_ SG_ 2349989630 Hvesp13CellBalancingCommand "HVESP13 Cell Balancing Command: Command for this High Voltage Energy Storage Pack instance to perform cell balancing.This parameter is for one of multiple packs in an HVESS.  If there is only one pack in the system, the HVESS parameters should be use...";
CM_ SG_ 2349989630 Hvsp13EnlIntrnlChrgrCmmnd "HVESP13 Enable Internal Charger Command: When the HVES has an internal charger this parameter will enable it.   External chargers may use the External Energy Source Connection Demand (SPN 7890) and related SPs.This parameter is for one of multiple pa...";
CM_ SG_ 2349989630 Hvesp13OperationConsent "HVESP13 Operation Consent: This parameter provides an indication to this High Voltage Energy Storage Pack instance that an external device is ready for this HVES instance to proceed with normal operation.  In applications which support this parameter...";
CM_ SG_ 2349989630 Hvsp13HVtBsHSdRsstCtRqst "HVESP13 High-Voltage Bus High Side Resistor Connect Request: This parameter is used to request connection of this HVES instance High-Voltage bus high side resistor in order to perform an isolation test. See also SPN 15561 (HVESP13 High-Voltage Bus Lo...";
CM_ SG_ 2349989630 Hvsp13HVtBsLwSdRsstCtRqst "HVESP13 High-Voltage Bus Low Side Resistor Connect Request: This parameter is used to request connection of this HVES instance High-Voltage bus low side resistor in order to perform an isolation test. See also SPN 15560 (HVESP13 High-Voltage Bus High...";
CM_ SG_ 2349989630 Hvsp13ThrmlMngmntMntnnRqst "HVESP13 Thermal Management Maintenance Request: Request to engage Thermal Management Maintenance Mode for this High Voltage Energy Storage System Pack instance.00b = HVESS Thermal Management Maintenance Mode is not requested01b = HVESS Thermal Manage...";
CM_ SG_ 2349989630 Hvesp13Control1Counter "HVESP13 Control 1 Counter: The message counter is used to detect situations where the transmitting ECU malfunction repeats the same frame all the time. The receiver of the information may use the counter parameter to detect this situation. The transm...";
CM_ SG_ 2349989630 Hvesp13Control1Crc "HVESP13 Control 1 CRC: The CRC is defined as follows: - Length: 8 bits- Polynomial: x^8+x^5+x^3+x^2+x+1- Initial Value: FFh- Input Data Reflection: Not reflected- Result Data Reflection: Not reflected- XOR value: FFh SAE makes no claim of the functio...";
CM_ BO_ 2350055166 "High Voltage Energy Storage Pack 14 Control 1";
CM_ SG_ 2350055166 Hvsp14HghVltgBsCnntCmmnd "HVESP14 High-Voltage Bus Connect Command: Command to connect this High Voltage Energy Storage Pack instance to the high-voltage bus.  The emergency contactor closure request may be used in situations where one or more faults in the hybrid or EV power...";
CM_ SG_ 2350055166 Hvesp14PowerDownCommand "HVESP14 Power-Down Command: Command to shut down this High Voltage Energy Storage Pack instance.  A normal power-down may involve steps that take some period of time (tests, writing of data, etc.).  However, an emergency power-down should shut down t...";
CM_ SG_ 2350055166 Hvsp14HghVltgBsAtvIsltnTstCmmnd "HVESP14 High-Voltage Bus Active Isolation Test Command: Command for this High Voltage Energy Storage Pack instance to perform an active electrical isolation test on the high voltage bus.An active isolation test might use a generated signal (e.g. an i...";
CM_ SG_ 2350055166 Hvsp14HVtBsPssvIstTstCd "HVESP14 High-Voltage Bus Passive Isolation Test Command: Command for this High Voltage Energy Storage Pack instance to perform a passive electrical isolation test on the high voltage bus.A passive isolation test uses additional circuitry (e.g. a high...";
CM_ SG_ 2350055166 Hvesp14CellBalancingCommand "HVESP14 Cell Balancing Command: Command for this High Voltage Energy Storage Pack instance to perform cell balancing.This parameter is for one of multiple packs in an HVESS.  If there is only one pack in the system, the HVESS parameters should be use...";
CM_ SG_ 2350055166 Hvsp14EnlIntrnlChrgrCmmnd "HVESP14 Enable Internal Charger Command: When the HVES has an internal charger this parameter will enable it.   External chargers may use the External Energy Source Connection Demand (SPN 7890) and related SPs.This parameter is for one of multiple pa...";
CM_ SG_ 2350055166 Hvesp14OperationConsent "HVESP14 Operation Consent: This parameter provides an indication to this High Voltage Energy Storage Pack instance that an external device is ready for this HVES instance to proceed with normal operation.  In applications which support this parameter...";
CM_ SG_ 2350055166 Hvsp14HVtBsHSdRsstCtRqst "HVESP14 High-Voltage Bus High Side Resistor Connect Request: This parameter is used to request connection of this HVES instance High-Voltage bus high side resistor in order to perform an isolation test. See also SPN 15703 (HVESP14 High-Voltage Bus Lo...";
CM_ SG_ 2350055166 Hvsp14HVtBsLwSdRsstCtRqst "HVESP14 High-Voltage Bus Low Side Resistor Connect Request: This parameter is used to request connection of this HVES instance High-Voltage bus low side resistor in order to perform an isolation test. See also SPN 15702 (HVESP14 High-Voltage Bus High...";
CM_ SG_ 2350055166 Hvsp14ThrmlMngmntMntnnRqst "HVESP14 Thermal Management Maintenance Request: Request to engage Thermal Management Maintenance Mode for this High Voltage Energy Storage System Pack instance.00b = HVESS Thermal Management Maintenance Mode is not requested01b = HVESS Thermal Manage...";
CM_ SG_ 2350055166 Hvesp14Control1Counter "HVESP14 Control 1 Counter: The message counter is used to detect situations where the transmitting ECU malfunction repeats the same frame all the time. The receiver of the information may use the counter parameter to detect this situation. The transm...";
CM_ SG_ 2350055166 Hvesp14Control1Crc "HVESP14 Control 1 CRC: The CRC is defined as follows: - Length: 8 bits- Polynomial: x^8+x^5+x^3+x^2+x+1- Initial Value: FFh- Input Data Reflection: Not reflected- Result Data Reflection: Not reflected- XOR value: FFh SAE makes no claim of the functio...";
CM_ BO_ 2350120702 "High Voltage Energy Storage Pack 15 Control 1";
CM_ SG_ 2350120702 Hvsp15HghVltgBsCnntCmmnd "HVESP15 High-Voltage Bus Connect Command: Command to connect this High Voltage Energy Storage Pack instance to the high-voltage bus.  The emergency contactor closure request may be used in situations where one or more faults in the hybrid or EV power...";
CM_ SG_ 2350120702 Hvesp15PowerDownCommand "HVESP15 Power-Down Command: Command to shut down this High Voltage Energy Storage Pack instance.  A normal power-down may involve steps that take some period of time (tests, writing of data, etc.).  However, an emergency power-down should shut down t...";
CM_ SG_ 2350120702 Hvsp15HghVltgBsAtvIsltnTstCmmnd "HVESP15 High-Voltage Bus Active Isolation Test Command: Command for this High Voltage Energy Storage Pack instance to perform an active electrical isolation test on the high voltage bus.An active isolation test might use a generated signal (e.g. an i...";
CM_ SG_ 2350120702 Hvsp15HVtBsPssvIstTstCd "HVESP15 High-Voltage Bus Passive Isolation Test Command: Command for this High Voltage Energy Storage Pack instance to perform a passive electrical isolation test on the high voltage bus.A passive isolation test uses additional circuitry (e.g. a high...";
CM_ SG_ 2350120702 Hvesp15CellBalancingCommand "HVESP15 Cell Balancing Command: Command for this High Voltage Energy Storage Pack instance to perform cell balancing.This parameter is for one of multiple packs in an HVESS.  If there is only one pack in the system, the HVESS parameters should be use...";
CM_ SG_ 2350120702 Hvsp15EnlIntrnlChrgrCmmnd "HVESP15 Enable Internal Charger Command: When the HVES has an internal charger this parameter will enable it.   External chargers may use the External Energy Source Connection Demand (SPN 7890) and related SPs.This parameter is for one of multiple pa...";
CM_ SG_ 2350120702 Hvesp15OperationConsent "HVESP15 Operation Consent: This parameter provides an indication to this High Voltage Energy Storage Pack instance that an external device is ready for this HVES instance to proceed with normal operation.  In applications which support this parameter...";
CM_ SG_ 2350120702 Hvsp15HVtBsHSdRsstCtRqst "HVESP15 High-Voltage Bus High Side Resistor Connect Request: This parameter is used to request connection of this HVES instance High-Voltage bus high side resistor in order to perform an isolation test. See also SPN 15845 (HVESP15 High-Voltage Bus Lo...";
CM_ SG_ 2350120702 Hvsp15HVtBsLwSdRsstCtRqst "HVESP15 High-Voltage Bus Low Side Resistor Connect Request: This parameter is used to request connection of this HVES instance High-Voltage bus low side resistor in order to perform an isolation test. See also SPN 15844 (HVESP15 High-Voltage Bus High...";
CM_ SG_ 2350120702 Hvsp15ThrmlMngmntMntnnRqst "HVESP15 Thermal Management Maintenance Request: Request to engage Thermal Management Maintenance Mode for this High Voltage Energy Storage System Pack instance.00b = HVESS Thermal Management Maintenance Mode is not requested01b = HVESS Thermal Manage...";
CM_ SG_ 2350120702 Hvesp15Control1Counter "HVESP15 Control 1 Counter: The message counter is used to detect situations where the transmitting ECU malfunction repeats the same frame all the time. The receiver of the information may use the counter parameter to detect this situation. The transm...";
CM_ SG_ 2350120702 Hvesp15Control1Crc "HVESP15 Control 1 CRC: The CRC is defined as follows: - Length: 8 bits- Polynomial: x^8+x^5+x^3+x^2+x+1- Initial Value: FFh- Input Data Reflection: Not reflected- Result Data Reflection: Not reflected- XOR value: FFh SAE makes no claim of the functio...";
CM_ BO_ 2350186238 "High Voltage Energy Storage Pack 16 Control 1";
CM_ SG_ 2350186238 Hvsp16HghVltgBsCnntCmmnd "HVESP16 High-Voltage Bus Connect Command: Command to connect this High Voltage Energy Storage Pack instance to the high-voltage bus.  The emergency contactor closure request may be used in situations where one or more faults in the hybrid or EV power...";
CM_ SG_ 2350186238 Hvesp16PowerDownCommand "HVESP16 Power-Down Command: Command to shut down this High Voltage Energy Storage Pack instance.  A normal power-down may involve steps that take some period of time (tests, writing of data, etc.).  However, an emergency power-down should shut down t...";
CM_ SG_ 2350186238 Hvsp16HghVltgBsAtvIsltnTstCmmnd "HVESP16 High-Voltage Bus Active Isolation Test Command: Command for this High Voltage Energy Storage Pack instance to perform an active electrical isolation test on the high voltage bus.An active isolation test might use a generated signal (e.g. an i...";
CM_ SG_ 2350186238 Hvsp16HVtBsPssvIstTstCd "HVESP16 High-Voltage Bus Passive Isolation Test Command: Command for this High Voltage Energy Storage Pack instance to perform a passive electrical isolation test on the high voltage bus.A passive isolation test uses additional circuitry (e.g. a high...";
CM_ SG_ 2350186238 Hvesp16CellBalancingCommand "HVESP16 Cell Balancing Command: Command for this High Voltage Energy Storage Pack instance to perform cell balancing.This parameter is for one of multiple packs in an HVESS.  If there is only one pack in the system, the HVESS parameters should be use...";
CM_ SG_ 2350186238 Hvsp16EnlIntrnlChrgrCmmnd "HVESP16 Enable Internal Charger Command: When the HVES has an internal charger this parameter will enable it.   External chargers may use the External Energy Source Connection Demand (SPN 7890) and related SPs.This parameter is for one of multiple pa...";
CM_ SG_ 2350186238 Hvesp16OperationConsent "HVESP16 Operation Consent: This parameter provides an indication to this High Voltage Energy Storage Pack instance that an external device is ready for this HVES instance to proceed with normal operation.  In applications which support this parameter...";
CM_ SG_ 2350186238 Hvsp16HVtBsHSdRsstCtRqst "HVESP16 High-Voltage Bus High Side Resistor Connect Request: This parameter is used to request connection of this HVES instance High-Voltage bus high side resistor in order to perform an isolation test. See also SPN 15987 (HVESP16 High-Voltage Bus Lo...";
CM_ SG_ 2350186238 Hvsp16HVtBsLwSdRsstCtRqst "HVESP16 High-Voltage Bus Low Side Resistor Connect Request: This parameter is used to request connection of this HVES instance High-Voltage bus low side resistor in order to perform an isolation test. See also SPN 15986 (HVESP16 High-Voltage Bus High...";
CM_ SG_ 2350186238 Hvsp16ThrmlMngmntMntnnRqst "HVESP16 Thermal Management Maintenance Request: Request to engage Thermal Management Maintenance Mode for this High Voltage Energy Storage System Pack instance.00b = HVESS Thermal Management Maintenance Mode is not requested01b = HVESS Thermal Manage...";
CM_ SG_ 2350186238 Hvesp16Control1Counter "HVESP16 Control 1 Counter: The message counter is used to detect situations where the transmitting ECU malfunction repeats the same frame all the time. The receiver of the information may use the counter parameter to detect this situation. The transm...";
CM_ SG_ 2350186238 Hvesp16Control1Crc "HVESP16 Control 1 CRC: The CRC is defined as follows: - Length: 8 bits- Polynomial: x^8+x^5+x^3+x^2+x+1- Initial Value: FFh- Input Data Reflection: Not reflected- Result Data Reflection: Not reflected- XOR value: FFh SAE makes no claim of the functio...";
CM_ BO_ 2350251774 "High Voltage Energy Storage Pack 17 Control 1";
CM_ SG_ 2350251774 Hvsp17HghVltgBsCnntCmmnd "HVESP17 High-Voltage Bus Connect Command: Command to connect this High Voltage Energy Storage Pack instance to the high-voltage bus.  The emergency contactor closure request may be used in situations where one or more faults in the hybrid or EV power...";
CM_ SG_ 2350251774 Hvesp17PowerDownCommand "HVESP17 Power-Down Command: Command to shut down this High Voltage Energy Storage Pack instance.  A normal power-down may involve steps that take some period of time (tests, writing of data, etc.).  However, an emergency power-down should shut down t...";
CM_ SG_ 2350251774 Hvsp17HghVltgBsAtvIsltnTstCmmnd "HVESP17 High-Voltage Bus Active Isolation Test Command: Command for this High Voltage Energy Storage Pack instance to perform an active electrical isolation test on the high voltage bus.An active isolation test might use a generated signal (e.g. an i...";
CM_ SG_ 2350251774 Hvsp17HVtBsPssvIstTstCd "HVESP17 High-Voltage Bus Passive Isolation Test Command: Command for this High Voltage Energy Storage Pack instance to perform a passive electrical isolation test on the high voltage bus.A passive isolation test uses additional circuitry (e.g. a high...";
CM_ SG_ 2350251774 Hvesp17CellBalancingCommand "HVESP17 Cell Balancing Command: Command for this High Voltage Energy Storage Pack instance to perform cell balancing.This parameter is for one of multiple packs in an HVESS.  If there is only one pack in the system, the HVESS parameters should be use...";
CM_ SG_ 2350251774 Hvsp17EnlIntrnlChrgrCmmnd "HVESP17 Enable Internal Charger Command: When the HVES has an internal charger this parameter will enable it.   External chargers may use the External Energy Source Connection Demand (SPN 7890) and related SPs.This parameter is for one of multiple pa...";
CM_ SG_ 2350251774 Hvesp17OperationConsent "HVESP17 Operation Consent: This parameter provides an indication to this High Voltage Energy Storage Pack instance that an external device is ready for this HVES instance to proceed with normal operation.  In applications which support this parameter...";
CM_ SG_ 2350251774 Hvsp17HVtBsHSdRsstCtRqst "HVESP17 High-Voltage Bus High Side Resistor Connect Request: This parameter is used to request connection of this HVES instance High-Voltage bus high side resistor in order to perform an isolation test. See also SPN 16129 (HVESP17 High-Voltage Bus Lo...";
CM_ SG_ 2350251774 Hvsp17HVtBsLwSdRsstCtRqst "HVESP17 High-Voltage Bus Low Side Resistor Connect Request: This parameter is used to request connection of this HVES instance High-Voltage bus low side resistor in order to perform an isolation test. See also SPN 16128 (HVESP17 High-Voltage Bus High...";
CM_ SG_ 2350251774 Hvsp17ThrmlMngmntMntnnRqst "HVESP17 Thermal Management Maintenance Request: Request to engage Thermal Management Maintenance Mode for this High Voltage Energy Storage System Pack instance.00b = HVESS Thermal Management Maintenance Mode is not requested01b = HVESS Thermal Manage...";
CM_ SG_ 2350251774 Hvesp17Control1Counter "HVESP17 Control 1 Counter: The message counter is used to detect situations where the transmitting ECU malfunction repeats the same frame all the time. The receiver of the information may use the counter parameter to detect this situation. The transm...";
CM_ SG_ 2350251774 Hvesp17Control1Crc "HVESP17 Control 1 CRC: The CRC is defined as follows: - Length: 8 bits- Polynomial: x^8+x^5+x^3+x^2+x+1- Initial Value: FFh- Input Data Reflection: Not reflected- Result Data Reflection: Not reflected- XOR value: FFh SAE makes no claim of the functio...";
CM_ BO_ 2350317310 "High Voltage Energy Storage Pack 18 Control 1";
CM_ SG_ 2350317310 Hvsp18HghVltgBsCnntCmmnd "HVESP18 High-Voltage Bus Connect Command: Command to connect this High Voltage Energy Storage Pack instance to the high-voltage bus.  The emergency contactor closure request may be used in situations where one or more faults in the hybrid or EV power...";
CM_ SG_ 2350317310 Hvesp18PowerDownCommand "HVESP18 Power-Down Command: Command to shut down this High Voltage Energy Storage Pack instance.  A normal power-down may involve steps that take some period of time (tests, writing of data, etc.).  However, an emergency power-down should shut down t...";
CM_ SG_ 2350317310 Hvsp18HghVltgBsAtvIsltnTstCmmnd "HVESP18 High-Voltage Bus Active Isolation Test Command: Command for this High Voltage Energy Storage Pack instance to perform an active electrical isolation test on the high voltage bus.An active isolation test might use a generated signal (e.g. an i...";
CM_ SG_ 2350317310 Hvsp18HVtBsPssvIstTstCd "HVESP18 High-Voltage Bus Passive Isolation Test Command: Command for this High Voltage Energy Storage Pack instance to perform a passive electrical isolation test on the high voltage bus.A passive isolation test uses additional circuitry (e.g. a high...";
CM_ SG_ 2350317310 Hvesp18CellBalancingCommand "HVESP18 Cell Balancing Command: Command for this High Voltage Energy Storage Pack instance to perform cell balancing.This parameter is for one of multiple packs in an HVESS.  If there is only one pack in the system, the HVESS parameters should be use...";
CM_ SG_ 2350317310 Hvsp18EnlIntrnlChrgrCmmnd "HVESP18 Enable Internal Charger Command: When the HVES has an internal charger this parameter will enable it.   External chargers may use the External Energy Source Connection Demand (SPN 7890) and related SPs.This parameter is for one of multiple pa...";
CM_ SG_ 2350317310 Hvesp18OperationConsent "HVESP18 Operation Consent: This parameter provides an indication to this High Voltage Energy Storage Pack instance that an external device is ready for this HVES instance to proceed with normal operation.  In applications which support this parameter...";
CM_ SG_ 2350317310 Hvsp18HVtBsHSdRsstCtRqst "HVESP18 High-Voltage Bus High Side Resistor Connect Request: This parameter is used to request connection of this HVES instance High-Voltage bus high side resistor in order to perform an isolation test. See also SPN 16271 (HVESP18 High-Voltage Bus Lo...";
CM_ SG_ 2350317310 Hvsp18HVtBsLwSdRsstCtRqst "HVESP18 High-Voltage Bus Low Side Resistor Connect Request: This parameter is used to request connection of this HVES instance High-Voltage bus low side resistor in order to perform an isolation test. See also SPN 16270 (HVESP18 High-Voltage Bus High...";
CM_ SG_ 2350317310 Hvsp18ThrmlMngmntMntnnRqst "HVESP18 Thermal Management Maintenance Request: Request to engage Thermal Management Maintenance Mode for this High Voltage Energy Storage System Pack instance.00b = HVESS Thermal Management Maintenance Mode is not requested01b = HVESS Thermal Manage...";
CM_ SG_ 2350317310 Hvesp18Control1Counter "HVESP18 Control 1 Counter: The message counter is used to detect situations where the transmitting ECU malfunction repeats the same frame all the time. The receiver of the information may use the counter parameter to detect this situation. The transm...";
CM_ SG_ 2350317310 Hvesp18Control1Crc "HVESP18 Control 1 CRC: The CRC is defined as follows: - Length: 8 bits- Polynomial: x^8+x^5+x^3+x^2+x+1- Initial Value: FFh- Input Data Reflection: Not reflected- Result Data Reflection: Not reflected- XOR value: FFh SAE makes no claim of the functio...";
CM_ BO_ 2350382846 "High Voltage Energy Storage Pack 19 Control 1";
CM_ SG_ 2350382846 Hvsp19HghVltgBsCnntCmmnd "HVESP19 High-Voltage Bus Connect Command: Command to connect this High Voltage Energy Storage Pack instance to the high-voltage bus.  The emergency contactor closure request may be used in situations where one or more faults in the hybrid or EV power...";
CM_ SG_ 2350382846 Hvesp19PowerDownCommand "HVESP19 Power-Down Command: Command to shut down this High Voltage Energy Storage Pack instance.  A normal power-down may involve steps that take some period of time (tests, writing of data, etc.).  However, an emergency power-down should shut down t...";
CM_ SG_ 2350382846 Hvsp19HghVltgBsAtvIsltnTstCmmnd "HVESP19 High-Voltage Bus Active Isolation Test Command: Command for this High Voltage Energy Storage Pack instance to perform an active electrical isolation test on the high voltage bus.An active isolation test might use a generated signal (e.g. an i...";
CM_ SG_ 2350382846 Hvsp19HVtBsPssvIstTstCd "HVESP19 High-Voltage Bus Passive Isolation Test Command: Command for this High Voltage Energy Storage Pack instance to perform a passive electrical isolation test on the high voltage bus.A passive isolation test uses additional circuitry (e.g. a high...";
CM_ SG_ 2350382846 Hvesp19CellBalancingCommand "HVESP19 Cell Balancing Command: Command for this High Voltage Energy Storage Pack instance to perform cell balancing.This parameter is for one of multiple packs in an HVESS.  If there is only one pack in the system, the HVESS parameters should be use...";
CM_ SG_ 2350382846 Hvsp19EnlIntrnlChrgrCmmnd "HVESP19 Enable Internal Charger Command: When the HVES has an internal charger this parameter will enable it.   External chargers may use the External Energy Source Connection Demand (SPN 7890) and related SPs.This parameter is for one of multiple pa...";
CM_ SG_ 2350382846 Hvesp19OperationConsent "HVESP19 Operation Consent: This parameter provides an indication to this High Voltage Energy Storage Pack instance that an external device is ready for this HVES instance to proceed with normal operation.  In applications which support this parameter...";
CM_ SG_ 2350382846 Hvsp19HVtBsHSdRsstCtRqst "HVESP19 High-Voltage Bus High Side Resistor Connect Request: This parameter is used to request connection of this HVES instance High-Voltage bus high side resistor in order to perform an isolation test. See also SPN 16413 (HVESP19 High-Voltage Bus Lo...";
CM_ SG_ 2350382846 Hvsp19HVtBsLwSdRsstCtRqst "HVESP19 High-Voltage Bus Low Side Resistor Connect Request: This parameter is used to request connection of this HVES instance High-Voltage bus low side resistor in order to perform an isolation test. See also SPN 16412 (HVESP19 High-Voltage Bus High...";
CM_ SG_ 2350382846 Hvsp19ThrmlMngmntMntnnRqst "HVESP19 Thermal Management Maintenance Request: Request to engage Thermal Management Maintenance Mode for this High Voltage Energy Storage System Pack instance.00b = HVESS Thermal Management Maintenance Mode is not requested01b = HVESS Thermal Manage...";
CM_ SG_ 2350382846 Hvesp19Control1Counter "HVESP19 Control 1 Counter: The message counter is used to detect situations where the transmitting ECU malfunction repeats the same frame all the time. The receiver of the information may use the counter parameter to detect this situation. The transm...";
CM_ SG_ 2350382846 Hvesp19Control1Crc "HVESP19 Control 1 CRC: The CRC is defined as follows: - Length: 8 bits- Polynomial: x^8+x^5+x^3+x^2+x+1- Initial Value: FFh- Input Data Reflection: Not reflected- Result Data Reflection: Not reflected- XOR value: FFh SAE makes no claim of the functio...";
CM_ BO_ 2350448382 "High Voltage Energy Storage Pack 20 Control 1";
CM_ SG_ 2350448382 Hvsp20HghVltgBsCnntCmmnd "HVESP20 High-Voltage Bus Connect Command: Command to connect this High Voltage Energy Storage Pack instance to the high-voltage bus.  The emergency contactor closure request may be used in situations where one or more faults in the hybrid or EV power...";
CM_ SG_ 2350448382 Hvesp20PowerDownCommand "HVESP20 Power-Down Command: Command to shut down this High Voltage Energy Storage Pack instance.  A normal power-down may involve steps that take some period of time (tests, writing of data, etc.).  However, an emergency power-down should shut down t...";
CM_ SG_ 2350448382 Hvsp20HghVltgBsAtvIsltnTstCmmnd "HVESP20 High-Voltage Bus Active Isolation Test Command: Command for this High Voltage Energy Storage Pack instance to perform an active electrical isolation test on the high voltage bus.An active isolation test might use a generated signal (e.g. an i...";
CM_ SG_ 2350448382 Hvsp20HVtBsPssvIstTstCd "HVESP20 High-Voltage Bus Passive Isolation Test Command: Command for this High Voltage Energy Storage Pack instance to perform a passive electrical isolation test on the high voltage bus.A passive isolation test uses additional circuitry (e.g. a high...";
CM_ SG_ 2350448382 Hvesp20CellBalancingCommand "HVESP20 Cell Balancing Command: Command for this High Voltage Energy Storage Pack instance to perform cell balancing.This parameter is for one of multiple packs in an HVESS.  If there is only one pack in the system, the HVESS parameters should be use...";
CM_ SG_ 2350448382 Hvsp20EnlIntrnlChrgrCmmnd "HVESP20 Enable Internal Charger Command: When the HVES has an internal charger this parameter will enable it.   External chargers may use the External Energy Source Connection Demand (SPN 7890) and related SPs.This parameter is for one of multiple pa...";
CM_ SG_ 2350448382 Hvesp20OperationConsent "HVESP20 Operation Consent: This parameter provides an indication to this High Voltage Energy Storage Pack instance that an external device is ready for this HVES instance to proceed with normal operation.  In applications which support this parameter...";
CM_ SG_ 2350448382 Hvsp20HVtBsHSdRsstCtRqst "HVESP20 High-Voltage Bus High Side Resistor Connect Request: This parameter is used to request connection of this HVES instance High-Voltage bus high side resistor in order to perform an isolation test. See also SPN 16555 (HVESP20 High-Voltage Bus Lo...";
CM_ SG_ 2350448382 Hvsp20HVtBsLwSdRsstCtRqst "HVESP20 High-Voltage Bus Low Side Resistor Connect Request: This parameter is used to request connection of this HVES instance High-Voltage bus low side resistor in order to perform an isolation test. See also SPN 16554 (HVESP20 High-Voltage Bus High...";
CM_ SG_ 2350448382 Hvsp20ThrmlMngmntMntnnRqst "HVESP20 Thermal Management Maintenance Request: Request to engage Thermal Management Maintenance Mode for this High Voltage Energy Storage System Pack instance.00b = HVESS Thermal Management Maintenance Mode is not requested01b = HVESS Thermal Manage...";
CM_ SG_ 2350448382 Hvesp20Control1Counter "HVESP20 Control 1 Counter: The message counter is used to detect situations where the transmitting ECU malfunction repeats the same frame all the time. The receiver of the information may use the counter parameter to detect this situation. The transm...";
CM_ SG_ 2350448382 Hvesp20Control1Crc "HVESP20 Control 1 CRC: The CRC is defined as follows: - Length: 8 bits- Polynomial: x^8+x^5+x^3+x^2+x+1- Initial Value: FFh- Input Data Reflection: Not reflected- Result Data Reflection: Not reflected- XOR value: FFh SAE makes no claim of the functio...";
CM_ BO_ 2350513918 "High Voltage Energy Storage Pack 21 Control 1";
CM_ SG_ 2350513918 Hvsp21HghVltgBsCnntCmmnd "HVESP21 High-Voltage Bus Connect Command: Command to connect this High Voltage Energy Storage Pack instance to the high-voltage bus.  The emergency contactor closure request may be used in situations where one or more faults in the hybrid or EV power...";
CM_ SG_ 2350513918 Hvesp21PowerDownCommand "HVESP21 Power-Down Command: Command to shut down this High Voltage Energy Storage Pack instance.  A normal power-down may involve steps that take some period of time (tests, writing of data, etc.).  However, an emergency power-down should shut down t...";
CM_ SG_ 2350513918 Hvsp21HghVltgBsAtvIsltnTstCmmnd "HVESP21 High-Voltage Bus Active Isolation Test Command: Command for this High Voltage Energy Storage Pack instance to perform an active electrical isolation test on the high voltage bus.An active isolation test might use a generated signal (e.g. an i...";
CM_ SG_ 2350513918 Hvsp21HVtBsPssvIstTstCd "HVESP21 High-Voltage Bus Passive Isolation Test Command: Command for this High Voltage Energy Storage Pack instance to perform a passive electrical isolation test on the high voltage bus.A passive isolation test uses additional circuitry (e.g. a high...";
CM_ SG_ 2350513918 Hvesp21CellBalancingCommand "HVESP21 Cell Balancing Command: Command for this High Voltage Energy Storage Pack instance to perform cell balancing.This parameter is for one of multiple packs in an HVESS.  If there is only one pack in the system, the HVESS parameters should be use...";
CM_ SG_ 2350513918 Hvsp21EnlIntrnlChrgrCmmnd "HVESP21 Enable Internal Charger Command: When the HVES has an internal charger this parameter will enable it.   External chargers may use the External Energy Source Connection Demand (SPN 7890) and related SPs.This parameter is for one of multiple pa...";
CM_ SG_ 2350513918 Hvesp21OperationConsent "HVESP21 Operation Consent: This parameter provides an indication to this High Voltage Energy Storage Pack instance that an external device is ready for this HVES instance to proceed with normal operation.  In applications which support this parameter...";
CM_ SG_ 2350513918 Hvsp21HVtBsHSdRsstCtRqst "HVESP21 High-Voltage Bus High Side Resistor Connect Request: This parameter is used to request connection of this HVES instance High-Voltage bus high side resistor in order to perform an isolation test. See also SPN 16697 (HVESP21 High-Voltage Bus Lo...";
CM_ SG_ 2350513918 Hvsp21HVtBsLwSdRsstCtRqst "HVESP21 High-Voltage Bus Low Side Resistor Connect Request: This parameter is used to request connection of this HVES instance High-Voltage bus low side resistor in order to perform an isolation test. See also SPN 16696 (HVESP21 High-Voltage Bus High...";
CM_ SG_ 2350513918 Hvsp21ThrmlMngmntMntnnRqst "HVESP21 Thermal Management Maintenance Request: Request to engage Thermal Management Maintenance Mode for this High Voltage Energy Storage System Pack instance.00b = HVESS Thermal Management Maintenance Mode is not requested01b = HVESS Thermal Manage...";
CM_ SG_ 2350513918 Hvesp21Control1Counter "HVESP21 Control 1 Counter: The message counter is used to detect situations where the transmitting ECU malfunction repeats the same frame all the time. The receiver of the information may use the counter parameter to detect this situation. The transm...";
CM_ SG_ 2350513918 Hvesp21Control1Crc "HVESP21 Control 1 CRC: The CRC is defined as follows: - Length: 8 bits- Polynomial: x^8+x^5+x^3+x^2+x+1- Initial Value: FFh- Input Data Reflection: Not reflected- Result Data Reflection: Not reflected- XOR value: FFh SAE makes no claim of the functio...";
CM_ BO_ 2350579454 "High Voltage Energy Storage Pack 22 Control 1";
CM_ SG_ 2350579454 Hvsp22HghVltgBsCnntCmmnd "HVESP22 High-Voltage Bus Connect Command: Command to connect this High Voltage Energy Storage Pack instance to the high-voltage bus.  The emergency contactor closure request may be used in situations where one or more faults in the hybrid or EV power...";
CM_ SG_ 2350579454 Hvesp22PowerDownCommand "HVESP22 Power-Down Command: Command to shut down this High Voltage Energy Storage Pack instance.  A normal power-down may involve steps that take some period of time (tests, writing of data, etc.).  However, an emergency power-down should shut down t...";
CM_ SG_ 2350579454 Hvsp22HghVltgBsAtvIsltnTstCmmnd "HVESP22 High-Voltage Bus Active Isolation Test Command: Command for this High Voltage Energy Storage Pack instance to perform an active electrical isolation test on the high voltage bus.An active isolation test might use a generated signal (e.g. an i...";
CM_ SG_ 2350579454 Hvsp22HVtBsPssvIstTstCd "HVESP22 High-Voltage Bus Passive Isolation Test Command: Command for this High Voltage Energy Storage Pack instance to perform a passive electrical isolation test on the high voltage bus.A passive isolation test uses additional circuitry (e.g. a high...";
CM_ SG_ 2350579454 Hvesp22CellBalancingCommand "HVESP22 Cell Balancing Command: Command for this High Voltage Energy Storage Pack instance to perform cell balancing.This parameter is for one of multiple packs in an HVESS.  If there is only one pack in the system, the HVESS parameters should be use...";
CM_ SG_ 2350579454 Hvsp22EnlIntrnlChrgrCmmnd "HVESP22 Enable Internal Charger Command: When the HVES has an internal charger this parameter will enable it.   External chargers may use the External Energy Source Connection Demand (SPN 7890) and related SPs.This parameter is for one of multiple pa...";
CM_ SG_ 2350579454 Hvesp22OperationConsent "HVESP22 Operation Consent: This parameter provides an indication to this High Voltage Energy Storage Pack instance that an external device is ready for this HVES instance to proceed with normal operation.  In applications which support this parameter...";
CM_ SG_ 2350579454 Hvsp22HVtBsHSdRsstCtRqst "HVESP22 High-Voltage Bus High Side Resistor Connect Request: This parameter is used to request connection of this HVES instance High-Voltage bus high side resistor in order to perform an isolation test. See also SPN 16839 (HVESP22 High-Voltage Bus Lo...";
CM_ SG_ 2350579454 Hvsp22HVtBsLwSdRsstCtRqst "HVESP22 High-Voltage Bus Low Side Resistor Connect Request: This parameter is used to request connection of this HVES instance High-Voltage bus low side resistor in order to perform an isolation test. See also SPN 16838 (HVESP22 High-Voltage Bus High...";
CM_ SG_ 2350579454 Hvsp22ThrmlMngmntMntnnRqst "HVESP22 Thermal Management Maintenance Request: Request to engage Thermal Management Maintenance Mode for this High Voltage Energy Storage System Pack instance.00b = HVESS Thermal Management Maintenance Mode is not requested01b = HVESS Thermal Manage...";
CM_ SG_ 2350579454 Hvesp22Control1Counter "HVESP22 Control 1 Counter: The message counter is used to detect situations where the transmitting ECU malfunction repeats the same frame all the time. The receiver of the information may use the counter parameter to detect this situation. The transm...";
CM_ SG_ 2350579454 Hvesp22Control1Crc "HVESP22 Control 1 CRC: The CRC is defined as follows: - Length: 8 bits- Polynomial: x^8+x^5+x^3+x^2+x+1- Initial Value: FFh- Input Data Reflection: Not reflected- Result Data Reflection: Not reflected- XOR value: FFh SAE makes no claim of the functio...";
CM_ BO_ 2350907134 "High Voltage Energy Storage Pack 23 Control 1";
CM_ SG_ 2350907134 Hvsp23HghVltgBsCnntCmmnd "HVESP23 High-Voltage Bus Connect Command: Command to connect this High Voltage Energy Storage Pack instance to the high-voltage bus.  The emergency contactor closure request may be used in situations where one or more faults in the hybrid or EV power...";
CM_ SG_ 2350907134 Hvesp23PowerDownCommand "HVESP23 Power-Down Command: Command to shut down this High Voltage Energy Storage Pack instance.  A normal power-down may involve steps that take some period of time (tests, writing of data, etc.).  However, an emergency power-down should shut down t...";
CM_ SG_ 2350907134 Hvsp23HghVltgBsAtvIsltnTstCmmnd "HVESP23 High-Voltage Bus Active Isolation Test Command: Command for this High Voltage Energy Storage Pack instance to perform an active electrical isolation test on the high voltage bus.An active isolation test might use a generated signal (e.g. an i...";
CM_ SG_ 2350907134 Hvsp23HVtBsPssvIstTstCd "HVESP23 High-Voltage Bus Passive Isolation Test Command: Command for this High Voltage Energy Storage Pack instance to perform a passive electrical isolation test on the high voltage bus.A passive isolation test uses additional circuitry (e.g. a high...";
CM_ SG_ 2350907134 Hvesp23CellBalancingCommand "HVESP23 Cell Balancing Command: Command for this High Voltage Energy Storage Pack instance to perform cell balancing.This parameter is for one of multiple packs in an HVESS.  If there is only one pack in the system, the HVESS parameters should be use...";
CM_ SG_ 2350907134 Hvsp23EnlIntrnlChrgrCmmnd "HVESP23 Enable Internal Charger Command: When the HVES has an internal charger this parameter will enable it.   External chargers may use the External Energy Source Connection Demand (SPN 7890) and related SPs.This parameter is for one of multiple pa...";
CM_ SG_ 2350907134 Hvesp23OperationConsent "HVESP23 Operation Consent: This parameter provides an indication to this High Voltage Energy Storage Pack instance that an external device is ready for this HVES instance to proceed with normal operation.  In applications which support this parameter...";
CM_ SG_ 2350907134 Hvsp23HVtBsHSdRsstCtRqst "HVESP23 High-Voltage Bus High Side Resistor Connect Request: This parameter is used to request connection of this HVES instance High-Voltage bus high side resistor in order to perform an isolation test. See also SPN 16981 (HVESP23 High-Voltage Bus Lo...";
CM_ SG_ 2350907134 Hvsp23HVtBsLwSdRsstCtRqst "HVESP23 High-Voltage Bus Low Side Resistor Connect Request: This parameter is used to request connection of this HVES instance High-Voltage bus low side resistor in order to perform an isolation test. See also SPN 16980 (HVESP23 High-Voltage Bus High...";
CM_ SG_ 2350907134 Hvsp23ThrmlMngmntMntnnRqst "HVESP23 Thermal Management Maintenance Request: Request to engage Thermal Management Maintenance Mode for this High Voltage Energy Storage System Pack instance.00b = HVESS Thermal Management Maintenance Mode is not requested01b = HVESS Thermal Manage...";
CM_ SG_ 2350907134 Hvesp23Control1Counter "HVESP23 Control 1 Counter: The message counter is used to detect situations where the transmitting ECU malfunction repeats the same frame all the time. The receiver of the information may use the counter parameter to detect this situation. The transm...";
CM_ SG_ 2350907134 Hvesp23Control1Crc "HVESP23 Control 1 CRC: The CRC is defined as follows: - Length: 8 bits- Polynomial: x^8+x^5+x^3+x^2+x+1- Initial Value: FFh- Input Data Reflection: Not reflected- Result Data Reflection: Not reflected- XOR value: FFh SAE makes no claim of the functio...";
CM_ BO_ 2350972670 "High Voltage Energy Storage Pack 24 Control 1";
CM_ SG_ 2350972670 Hvsp24HghVltgBsCnntCmmnd "HVESP24 High-Voltage Bus Connect Command: Command to connect this High Voltage Energy Storage Pack instance to the high-voltage bus.  The emergency contactor closure request may be used in situations where one or more faults in the hybrid or EV power...";
CM_ SG_ 2350972670 Hvesp24PowerDownCommand "HVESP24 Power-Down Command: Command to shut down this High Voltage Energy Storage Pack instance.  A normal power-down may involve steps that take some period of time (tests, writing of data, etc.).  However, an emergency power-down should shut down t...";
CM_ SG_ 2350972670 Hvsp24HghVltgBsAtvIsltnTstCmmnd "HVESP24 High-Voltage Bus Active Isolation Test Command: Command for this High Voltage Energy Storage Pack instance to perform an active electrical isolation test on the high voltage bus.An active isolation test might use a generated signal (e.g. an i...";
CM_ SG_ 2350972670 Hvsp24HVtBsPssvIstTstCd "HVESP24 High-Voltage Bus Passive Isolation Test Command: Command for this High Voltage Energy Storage Pack instance to perform a passive electrical isolation test on the high voltage bus.A passive isolation test uses additional circuitry (e.g. a high...";
CM_ SG_ 2350972670 Hvesp24CellBalancingCommand "HVESP24 Cell Balancing Command: Command for this High Voltage Energy Storage Pack instance to perform cell balancing.This parameter is for one of multiple packs in an HVESS.  If there is only one pack in the system, the HVESS parameters should be use...";
CM_ SG_ 2350972670 Hvsp24EnlIntrnlChrgrCmmnd "HVESP24 Enable Internal Charger Command: When the HVES has an internal charger this parameter will enable it.   External chargers may use the External Energy Source Connection Demand (SPN 7890) and related SPs.This parameter is for one of multiple pa...";
CM_ SG_ 2350972670 Hvesp24OperationConsent "HVESP24 Operation Consent: This parameter provides an indication to this High Voltage Energy Storage Pack instance that an external device is ready for this HVES instance to proceed with normal operation.  In applications which support this parameter...";
CM_ SG_ 2350972670 Hvsp24HVtBsHSdRsstCtRqst "HVESP24 High-Voltage Bus High Side Resistor Connect Request: This parameter is used to request connection of this HVES instance High-Voltage bus high side resistor in order to perform an isolation test. See also SPN 17123 (HVESP24 High-Voltage Bus Lo...";
CM_ SG_ 2350972670 Hvsp24HVtBsLwSdRsstCtRqst "HVESP24 High-Voltage Bus Low Side Resistor Connect Request: This parameter is used to request connection of this HVES instance High-Voltage bus low side resistor in order to perform an isolation test. See also SPN 17122 (HVESP24 High-Voltage Bus High...";
CM_ SG_ 2350972670 Hvsp24ThrmlMngmntMntnnRqst "HVESP24 Thermal Management Maintenance Request: Request to engage Thermal Management Maintenance Mode for this High Voltage Energy Storage System Pack instance.00b = HVESS Thermal Management Maintenance Mode is not requested01b = HVESS Thermal Manage...";
CM_ SG_ 2350972670 Hvesp24Control1Counter "HVESP24 Control 1 Counter: The message counter is used to detect situations where the transmitting ECU malfunction repeats the same frame all the time. The receiver of the information may use the counter parameter to detect this situation. The transm...";
CM_ SG_ 2350972670 Hvesp24Control1Crc "HVESP24 Control 1 CRC: The CRC is defined as follows: - Length: 8 bits- Polynomial: x^8+x^5+x^3+x^2+x+1- Initial Value: FFh- Input Data Reflection: Not reflected- Result Data Reflection: Not reflected- XOR value: FFh SAE makes no claim of the functio...";
CM_ BO_ 2351038206 "High Voltage Energy Storage Pack 25 Control 1";
CM_ SG_ 2351038206 Hvsp25HghVltgBsCnntCmmnd "HVESP25 High-Voltage Bus Connect Command: Command to connect this High Voltage Energy Storage Pack instance to the high-voltage bus.  The emergency contactor closure request may be used in situations where one or more faults in the hybrid or EV power...";
CM_ SG_ 2351038206 Hvesp25PowerDownCommand "HVESP25 Power-Down Command: Command to shut down this High Voltage Energy Storage Pack instance.  A normal power-down may involve steps that take some period of time (tests, writing of data, etc.).  However, an emergency power-down should shut down t...";
CM_ SG_ 2351038206 Hvsp25HghVltgBsAtvIsltnTstCmmnd "HVESP25 High-Voltage Bus Active Isolation Test Command: Command for this High Voltage Energy Storage Pack instance to perform an active electrical isolation test on the high voltage bus.An active isolation test might use a generated signal (e.g. an i...";
CM_ SG_ 2351038206 Hvsp25HVtBsPssvIstTstCd "HVESP25 High-Voltage Bus Passive Isolation Test Command: Command for this High Voltage Energy Storage Pack instance to perform a passive electrical isolation test on the high voltage bus.A passive isolation test uses additional circuitry (e.g. a high...";
CM_ SG_ 2351038206 Hvesp25CellBalancingCommand "HVESP25 Cell Balancing Command: Command for this High Voltage Energy Storage Pack instance to perform cell balancing.This parameter is for one of multiple packs in an HVESS.  If there is only one pack in the system, the HVESS parameters should be use...";
CM_ SG_ 2351038206 Hvsp25EnlIntrnlChrgrCmmnd "HVESP25 Enable Internal Charger Command: When the HVES has an internal charger this parameter will enable it.   External chargers may use the External Energy Source Connection Demand (SPN 7890) and related SPs.This parameter is for one of multiple pa...";
CM_ SG_ 2351038206 Hvesp25OperationConsent "HVESP25 Operation Consent: This parameter provides an indication to this High Voltage Energy Storage Pack instance that an external device is ready for this HVES instance to proceed with normal operation.  In applications which support this parameter...";
CM_ SG_ 2351038206 Hvsp25HVtBsHSdRsstCtRqst "HVESP25 High-Voltage Bus High Side Resistor Connect Request: This parameter is used to request connection of this HVES instance High-Voltage bus high side resistor in order to perform an isolation test. See also SPN 17265 (HVESP25 High-Voltage Bus Lo...";
CM_ SG_ 2351038206 Hvsp25HVtBsLwSdRsstCtRqst "HVESP25 High-Voltage Bus Low Side Resistor Connect Request: This parameter is used to request connection of this HVES instance High-Voltage bus low side resistor in order to perform an isolation test. See also SPN 17264 (HVESP25 High-Voltage Bus High...";
CM_ SG_ 2351038206 Hvsp25ThrmlMngmntMntnnRqst "HVESP25 Thermal Management Maintenance Request: Request to engage Thermal Management Maintenance Mode for this High Voltage Energy Storage System Pack instance.00b = HVESS Thermal Management Maintenance Mode is not requested01b = HVESS Thermal Manage...";
CM_ SG_ 2351038206 Hvesp25Control1Counter "HVESP25 Control 1 Counter: The message counter is used to detect situations where the transmitting ECU malfunction repeats the same frame all the time. The receiver of the information may use the counter parameter to detect this situation. The transm...";
CM_ SG_ 2351038206 Hvesp25Control1Crc "HVESP25 Control 1 CRC: The CRC is defined as follows: - Length: 8 bits- Polynomial: x^8+x^5+x^3+x^2+x+1- Initial Value: FFh- Input Data Reflection: Not reflected- Result Data Reflection: Not reflected- XOR value: FFh SAE makes no claim of the functio...";
CM_ BO_ 2351103742 "High Voltage Energy Storage Pack 26 Control 1";
CM_ SG_ 2351103742 Hvsp26HghVltgBsCnntCmmnd "HVESP26 High-Voltage Bus Connect Command: Command to connect this High Voltage Energy Storage Pack instance to the high-voltage bus.  The emergency contactor closure request may be used in situations where one or more faults in the hybrid or EV power...";
CM_ SG_ 2351103742 Hvesp26PowerDownCommand "HVESP26 Power-Down Command: Command to shut down this High Voltage Energy Storage Pack instance.  A normal power-down may involve steps that take some period of time (tests, writing of data, etc.).  However, an emergency power-down should shut down t...";
CM_ SG_ 2351103742 Hvsp26HghVltgBsAtvIsltnTstCmmnd "HVESP26 High-Voltage Bus Active Isolation Test Command: Command for this High Voltage Energy Storage Pack instance to perform an active electrical isolation test on the high voltage bus.An active isolation test might use a generated signal (e.g. an i...";
CM_ SG_ 2351103742 Hvsp26HVtBsPssvIstTstCd "HVESP26 High-Voltage Bus Passive Isolation Test Command: Command for this High Voltage Energy Storage Pack instance to perform a passive electrical isolation test on the high voltage bus.A passive isolation test uses additional circuitry (e.g. a high...";
CM_ SG_ 2351103742 Hvesp26CellBalancingCommand "HVESP26 Cell Balancing Command: Command for this High Voltage Energy Storage Pack instance to perform cell balancing.This parameter is for one of multiple packs in an HVESS.  If there is only one pack in the system, the HVESS parameters should be use...";
CM_ SG_ 2351103742 Hvsp26EnlIntrnlChrgrCmmnd "HVESP26 Enable Internal Charger Command: When the HVES has an internal charger this parameter will enable it.   External chargers may use the External Energy Source Connection Demand (SPN 7890) and related SPs.This parameter is for one of multiple pa...";
CM_ SG_ 2351103742 Hvesp26OperationConsent "HVESP26 Operation Consent: This parameter provides an indication to this High Voltage Energy Storage Pack instance that an external device is ready for this HVES instance to proceed with normal operation.  In applications which support this parameter...";
CM_ SG_ 2351103742 Hvsp26HVtBsHSdRsstCtRqst "HVESP26 High-Voltage Bus High Side Resistor Connect Request: This parameter is used to request connection of this HVES instance High-Voltage bus high side resistor in order to perform an isolation test. See also SPN 17407 (HVESP26 High-Voltage Bus Lo...";
CM_ SG_ 2351103742 Hvsp26HVtBsLwSdRsstCtRqst "HVESP26 High-Voltage Bus Low Side Resistor Connect Request: This parameter is used to request connection of this HVES instance High-Voltage bus low side resistor in order to perform an isolation test. See also SPN 17406 (HVESP26 High-Voltage Bus High...";
CM_ SG_ 2351103742 Hvsp26ThrmlMngmntMntnnRqst "HVESP26 Thermal Management Maintenance Request: Request to engage Thermal Management Maintenance Mode for this High Voltage Energy Storage System Pack instance.00b = HVESS Thermal Management Maintenance Mode is not requested01b = HVESS Thermal Manage...";
CM_ SG_ 2351103742 Hvesp26Control1Counter "HVESP26 Control 1 Counter: The message counter is used to detect situations where the transmitting ECU malfunction repeats the same frame all the time. The receiver of the information may use the counter parameter to detect this situation. The transm...";
CM_ SG_ 2351103742 Hvesp26Control1Crc "HVESP26 Control 1 CRC: The CRC is defined as follows: - Length: 8 bits- Polynomial: x^8+x^5+x^3+x^2+x+1- Initial Value: FFh- Input Data Reflection: Not reflected- Result Data Reflection: Not reflected- XOR value: FFh SAE makes no claim of the functio...";
CM_ BO_ 2555182846 "Electrified Accessory Engine Coolant Pump Command";
CM_ SG_ 2555182846 EngnClntEltrPmpEnlCmmnd "Engine Coolant Electric Pump Enable Command: Enable and direction command to the Engine Electric Coolant Pump.00b = Motor Off01b = Motor On Normal/Default Direction10b = Motor On Reverse Direction11b = Don't Care/Take no action";
CM_ SG_ 2555182846 EngnClntEltrPmpPwrHld "Engine Coolant Electric Pump Power Hold: Command to allow the Engine Electric Coolant Pump to remain alive independently of the electrical enable input to the Accessory Motor. For example, this could allow continued device operation after the keyswit...";
CM_ SG_ 2555182846 EngnClntEltrPmpDrvSr "Engine Coolant Electric Pump Drive Source: Signal to the electric motor to indicate that the engine coolant pump is being powered by some other means, for example by a clutched belt from the engine.00b = Pump driven from electric motor01b = Pump driv...";
CM_ SG_ 2555182846 EngnClntEltrPmpSpdCmmnd "Engine Coolant Electric Pump Speed Command: Speed command to the Engine Electric Coolant Pump.Note:  Both Speed Command and Percent Speed Command cannot be used at the same time.  Always set the unused speed command to Not Available. If both commands...";
CM_ SG_ 2555182846 EngnClntEltrPmpPrntSpd "Engine Coolant Electric Pump Percent Speed: Speed command to the Engine Electric Coolant Pump in percentage of maximum speed.Note: Both Speed Command and Percent Speed Command cannot be used at the same time.  Always set the unused speed command to N...";
CM_ BO_ 2364567550 "Power Converter 1 Control 1";
CM_ SG_ 2364567550 PowerConverter1ControlCrc "Power Converter 1 Control CRC: The CRC is defined as follows: - Length: 8 bits- Polynomial: x^8+x^5+x^3+x^2+x+1- Initial Value: FFh- Input Data Reflection: Not reflected- Result Data Reflection: Not reflected- XOR value: FFh SAE makes no claim of the...";
CM_ SG_ 2364567550 PowerConverter1ControlCounter "Power Converter 1 Control Counter: The message counter is used to detect situations where the transmitting ECU malfunction repeats the same frame all the time. The receiver of the information may use the counter parameter to detect this situation. Th...";
CM_ SG_ 2364567550 PwrCnvrtr1CntrlLmtsRqstOvrrdMd "Power Converter 1 Control Limits Request Override Mode: This parameter provides a way to temporarily override limits that are being received by the Power Converter in other messages.  It allows a specific type of limit to be transmitted at a high rat...";
CM_ SG_ 2364567550 PwCvt1CtLtsRqstOvdMx "Power Converter 1 Control Limits Request Override Maximum: The Maximum limit requested by this parameter depends on the value of SPN 20467 (Power Converter 1 Control Limits Request Override Mode).In normal operating conditions, the Power Converter op...";
CM_ SG_ 2364567550 PwCvt1CtLtsRqstOvdM "Power Converter 1 Control Limits Request Override Minimum: The Minimum limit requested by this parameter depends on the value of SPN 20467 (Power Converter 1 Control Limits Request Override Mode).In normal operating conditions, the Power Converter op...";
CM_ SG_ 2364567550 PwrCnvrtr1CntrlStpntMdRqst "Power Converter 1 Control Setpoint Mode Request: Requests the modes for this instance of the Power Converter.  See SPN 20546 (Power Converter 1 Control Setpoint Mode) for the feedback to this request.Passive modes:  Modes where the Power Converter do...";
CM_ SG_ 2364567550 PwrCnvrtr1CntrlStpntRqst "Power Converter 1 Control Setpoint Request: Requests the set point for this inverter.  The type of set point requested by this parameter depends on the value of SPN 20470 (Power Converter 1 Control Setpoint Mode Request) as follows:Passive Modes: In ...";
CM_ BO_ 2364567806 "Power Converter 2 Control 1";
CM_ SG_ 2364567806 PowerConverter2ControlCrc "Power Converter 2 Control CRC: The CRC is defined as follows: - Length: 8 bits- Polynomial: x^8+x^5+x^3+x^2+x+1- Initial Value: FFh- Input Data Reflection: Not reflected- Result Data Reflection: Not reflected- XOR value: FFh SAE makes no claim of the...";
CM_ SG_ 2364567806 PowerConverter2ControlCounter "Power Converter 2 Control Counter: The message counter is used to detect situations where the transmitting ECU malfunction repeats the same frame all the time. The receiver of the information may use the counter parameter to detect this situation. Th...";
CM_ SG_ 2364567806 PwrCnvrtr2CntrlLmtsRqstOvrrdMd "Power Converter 2 Control Limits Request Override Mode: This parameter provides a way to temporarily override limits that are being received by the Power Converter in other messages.  It allows a specific type of limit to be transmitted at a high rat...";
CM_ SG_ 2364567806 PwCvt2CtLtsRqstOvdMx "Power Converter 2 Control Limits Request Override Maximum: The Maximum limit requested by this parameter depends on the value of SPN 20474 (Power Converter 2 Control Limits Request Override Mode).In normal operating conditions, the Power Converter op...";
CM_ SG_ 2364567806 PwCvt2CtLtsRqstOvdM "Power Converter 2 Control Limits Request Override Minimum: The Minimum limit requested by this parameter depends on the value of SPN 20474 (Power Converter 2 Control Limits Request Override Mode).In normal operating conditions, the Power Converter op...";
CM_ SG_ 2364567806 PwrCnvrtr2CntrlStpntMdRqst "Power Converter 2 Control Setpoint Mode Request: Requests the modes for this instance of the Power Converter.  See SPN 20571 (Power Converter 2 Control Setpoint Mode) for the feedback to this request.Passive modes:  Modes where the Power Converter do...";
CM_ SG_ 2364567806 PwrCnvrtr2CntrlStpntRqst "Power Converter 2 Control Setpoint Request: Requests the set point for this inverter.  The type of set point requested by this parameter depends on the value of SPN 20477 (Power Converter 2 Control Setpoint Mode Request) as follows:Passive Modes: In ...";
CM_ BO_ 2565894654 "Power Converter 1 Rate Limits Request 1";
CM_ SG_ 2565894654 PwrCnvrtr1RtLmtsRqst1Cr "Power Converter 1 Rate Limits Request 1 CRC: The CRC is defined as follows: - Length: 8 bits- Polynomial: x^8+x^5+x^3+x^2+x+1- Initial Value: FFh- Input Data Reflection: Not reflected- Result Data Reflection: Not reflected- XOR value: FFh SAE makes n...";
CM_ SG_ 2565894654 PwrCnvrtr1RtLmtsRqst1Cntr "Power Converter 1 Rate Limits Request 1 Counter: The message counter is used to detect situations where the transmitting ECU malfunction repeats the same frame all the time. The receiver of the information may use the counter parameter to detect this...";
CM_ SG_ 2565894654 PwCvt1RtLtsRqstAstFqRtLt "Power Converter 1 Rate Limits Request Absolute Frequency Rate Limit: The maximum rate of change for the absolute system frequency  (i.e. |d(frequency)|/dt) in all control modes. This limit shall solely lead to reducing the absolute current, not incre...";
CM_ SG_ 2565894654 PwCvt1RtLtsRqstAstCtRtLt "Power Converter 1 Rate Limits Request Absolute Current Rate Limit: The maximum rate of change for the absolute system current (i.e. |d(current)|/dt) in all control modes. Refer to SPN 20690 (Power Converter 1 Reference Current) to convert %/sec to A/...";
CM_ BO_ 2565894910 "Power Converter 2 Rate Limits Request 1";
CM_ SG_ 2565894910 PwrCnvrtr2RtLmtsRqst1Cr "Power Converter 2 Rate Limits Request 1 CRC: The CRC is defined as follows: - Length: 8 bits- Polynomial: x^8+x^5+x^3+x^2+x+1- Initial Value: FFh- Input Data Reflection: Not reflected- Result Data Reflection: Not reflected- XOR value: FFh SAE makes n...";
CM_ SG_ 2565894910 PwrCnvrtr2RtLmtsRqst1Cntr "Power Converter 2 Rate Limits Request 1 Counter: The message counter is used to detect situations where the transmitting ECU malfunction repeats the same frame all the time. The receiver of the information may use the counter parameter to detect this...";
CM_ SG_ 2565894910 PwCvt2RtLtsRqstAstFqRtLt "Power Converter 2 Rate Limits Request Absolute Frequency Rate Limit: The maximum rate of change for the absolute system frequency (i.e. |d(frequency)|/dt) in all control modes. This limit shall solely lead to reducing the absolute current, not increa...";
CM_ SG_ 2565894910 PwCvt2RtLtsRqstAstCtRtLt "Power Converter 2 Rate Limits Request Absolute Current Rate Limit: The maximum rate of change for the absolute system current (i.e. |d(current)|/dt) in all control modes. Refer to SPN 20667 (Power Converter 2 Reference Current) to convert %/sec to A/...";
CM_ BO_ 2364568574 "Power Converter 2 Control 2";
CM_ SG_ 2364568574 PowerConverter2Control2Crc "Power Converter 2 Control 2 CRC: The CRC is defined as follows: - Length: 8 bits- Polynomial: x^8+x^5+x^3+x^2+x+1- Initial Value: FFh- Input Data Reflection: Not reflected- Result Data Reflection: Not reflected- XOR value: FFh SAE makes no claim of t...";
CM_ SG_ 2364568574 PowerConverter2Control2Counter "Power Converter 2 Control 2 Counter: The message counter is used to detect situations where the transmitting ECU malfunction repeats the same frame all the time. The receiver of the information may use the counter parameter to detect this situation. ...";
CM_ SG_ 2364568574 PwrCnvrtr2PdCntrlAppllMd "Power Converter 2 PID Control Applicable Mode: Defines the Mode that the PID Gain parameters apply for this instance of the Power Converter.  See SPN 20571 (Power Converter 2 Control Setpoint Mode) for a definition of modes for control purposes.Appli...";
CM_ SG_ 2364568574 PwCvt2PdCtNzdDtG "Power Converter 2 PID Control Normalized Differential Gain: A PID controller can be parametrized by factors Kp, Ki and Kd. This parameter defines the normalized differential gain (Kdn) for control applications in this inverter instance. The normaliza...";
CM_ SG_ 2364568574 PwrCnvrtr2PdCntrlNrmlzdIntgrlGn "Power Converter 2 PID Control Normalized Integral Gain: A PID controller can be parametrized by factors Kp, Ki and Kd. This parameter defines the normalized integral gain (Kin) for control applications in this inverter instance. The normalization con...";
CM_ SG_ 2364568574 PwCvt2PdCtNzdPptG "Power Converter 2 PID Control Normalized Proportional Gain: A PID controller can be parametrized by factors Kp, Ki and Kd. This parameter defines the normalized proportional gain (Kpn) for control applications in this inverter instance. The normaliza...";
CM_ BO_ 2364568830 "Power Converter 1 Control 2";
CM_ SG_ 2364568830 PowerConverter1Control2Crc "Power Converter 1 Control 2 CRC: The CRC is defined as follows: - Length: 8 bits- Polynomial: x^8+x^5+x^3+x^2+x+1- Initial Value: FFh- Input Data Reflection: Not reflected- Result Data Reflection: Not reflected- XOR value: FFh SAE makes no claim of t...";
CM_ SG_ 2364568830 PowerConverter1Control2Counter "Power Converter 1 Control 2 Counter: The message counter is used to detect situations where the transmitting ECU malfunction repeats the same frame all the time. The receiver of the information may use the counter parameter to detect this situation. ...";
CM_ SG_ 2364568830 PwrCnvrtr1PdCntrlAppllMd "Power Converter 1 PID Control Applicable Mode: Defines the Mode that the PID Gain parameters apply for this instance of the Power Converter.  See SPN 20546 (Power Converter 1 Control Setpoint Mode) for a definition of modes for control purposes.Appli...";
CM_ SG_ 2364568830 PwCvt1PdCtNzdDtG "Power Converter 1 PID Control Normalized Differential Gain: A PID controller can be parametrized by factors Kp, Ki and Kd. This parameter defines the normalized differential gain (Kdn) for control applications in this inverter instance. The normaliza...";
CM_ SG_ 2364568830 PwrCnvrtr1PdCntrlNrmlzdIntgrlGn "Power Converter 1 PID Control Normalized Integral Gain: A PID controller can be parametrized by factors Kp, Ki and Kd. This parameter defines the normalized integral gain (Kin) for control applications in this inverter instance. The normalization con...";
CM_ SG_ 2364568830 PwCvt1PdCtNzdPptG "Power Converter 1 PID Control Normalized Proportional Gain: A PID controller can be parametrized by factors Kp, Ki and Kd. This parameter defines the normalized proportional gain (Kpn) for control applications in this inverter instance. The normaliza...";
CM_ BO_ 2364569086 "Power Converter 1 Mode Feedback 1";
CM_ SG_ 2364569086 PowerConverter1ModeFeedback1Crc "Power Converter 1 Mode Feedback 1 CRC: The CRC is defined as follows: - Length: 8 bits- Polynomial: x^8+x^5+x^3+x^2+x+1- Initial Value: FFh- Input Data Reflection: Not reflected- Result Data Reflection: Not reflected- XOR value: FFh SAE makes no clai...";
CM_ SG_ 2364569086 PwrCnvrtr1MdFdk1Cntr "Power Converter 1 Mode Feedback 1 Counter: The message counter is used to detect situations where the transmitting ECU malfunction repeats the same frame all the time. The receiver of the information may use the counter parameter to detect this situa...";
CM_ SG_ 2364569086 PwrCnvrtr1CntrlLmtsOvrrdMd "Power Converter 1 Control Limits Override Mode: During normal operation this will have the same value as SPN 20467 (Power Converter 1 Control Limits Request Override Mode).  0 = Operating limits are not overridden.  If a limit was previously active, ...";
CM_ SG_ 2364569086 PwrCnvrtr1CntrlStpntMd "Power Converter 1 Control Setpoint Mode: Reports the Power Converter mode (See SPN 20470 (Power Converter 1 Control Setpoint Mode Request) for requested mode).Passive modes:  0 = Powered On - the Power Converter is commanded to be powered on and able...";
CM_ SG_ 2364569086 PowerConverter1HvilStatus "Power Converter 1 HVIL Status: Reports the High Voltage Interlock Loop (HVIL) state.00b = HVIL Closed01b = HVIL Open10b = Error11b = Not Available";
CM_ BO_ 2565895934 "Power Converter 1 Limits Active Power";
CM_ SG_ 2565895934 PwrCnvrtr1LmtsAtvPwrCr "Power Converter 1 Limits Active Power CRC: The CRC is defined as follows: - Length: 8 bits- Polynomial: x^8+x^5+x^3+x^2+x+1- Initial Value: FFh- Input Data Reflection: Not reflected- Result Data Reflection: Not reflected- XOR value: FFh SAE makes no ...";
CM_ SG_ 2565895934 PwrCnvrtr1LmtsAtvPwrCntr "Power Converter 1 Limits Active Power Counter: The message counter is used to detect situations where the transmitting ECU malfunction repeats the same frame all the time. The receiver of the information may use the counter parameter to detect this s...";
CM_ SG_ 2565895934 PwrCnvrtr1LmtsAtvEltrlPwrMxmm "Power Converter 1 Limits Active Electrical Power Maximum: the Power Converter keeps the electrical system power below this value.   This limit may be set in response to a Limits Request or determined by the Power Converter based on operating conditio...";
CM_ SG_ 2565895934 PwrCnvrtr1LmtsAtvEltrlPwrMnmm "Power Converter 1 Limits Active Electrical Power Minimum: the Power Converter keeps the electrical system power above this value.   This limit may be set in response to a Limits Request or determined by the Power Converter based on operating conditio...";
CM_ SG_ 2565895934 PwCvt1LtsAtvDES1PwMx "Power Converter 1 Limits Active DC Energy Source 1 Power Maximum: the Power Converter keeps the DC Energy Source 1 power below this value.   This limit may be set in response to a Limits Request or determined by the Power Converter based on operating...";
CM_ SG_ 2565895934 PwCvt1LtsAtvDES1PwM "Power Converter 1 Limits Active DC Energy Source 1 Power Minimum: the Power Converter keeps the DC Energy Source 1 power above this value.   This limit may be set in response to a Limits Request or determined by the Power Converter based on operating...";
CM_ BO_ 2565896190 "Power Converter 1 Limits Active Electrical";
CM_ SG_ 2565896190 PwrCnvrtr1LmtsAtvEltrlCr "Power Converter 1 Limits Active Electrical CRC: The CRC is defined as follows: - Length: 8 bits- Polynomial: x^8+x^5+x^3+x^2+x+1- Initial Value: FFh- Input Data Reflection: Not reflected- Result Data Reflection: Not reflected- XOR value: FFh SAE make...";
CM_ SG_ 2565896190 PwrCnvrtr1LmtsAtvEltrlCntr "Power Converter 1 Limits Active Electrical Counter: The message counter is used to detect situations where the transmitting ECU malfunction repeats the same frame all the time. The receiver of the information may use the counter parameter to detect t...";
CM_ SG_ 2565896190 PwrCnvrtr1LmtsAtvCrrntMxmm "Power Converter 1 Limits Active Current Maximum: the Power Converter keeps the system current below this value.  This limit may be set in response to a Limits Request or determined by the Power Converter based on operating conditions.Refer to SPN 206...";
CM_ SG_ 2565896190 PwrCnvrtr1LmtsAtvCrrntMnmm "Power Converter 1 Limits Active Current Minimum: the Power Converter keeps the system current above this value.  This limit may be set in response to a Limits Request or determined by the Power Converter based on operating conditions.Refer to SPN 206...";
CM_ SG_ 2565896190 PwrCnvrtr1LmtsAtvFrqnMxmm "Power Converter 1 Limits Active Frequency Maximum: the Power Converter keeps the system frequency below this value.  This limit may be set in response to a Limits Request or determined by the Power Converter based on operating conditions.Refer to SPN...";
CM_ SG_ 2565896190 PwrCnvrtr1LmtsAtvFrqnMnmm "Power Converter 1 Limits Active Frequency Minimum: the Power Converter keeps the system Frequency above this value.  This limit may be set in response to a Limits Request or determined by the Power Converter based on operating conditions.Refer to SPN...";
CM_ BO_ 2565896446 "Power Converter 1 Limits Active DC Energy Source 1";
CM_ SG_ 2565896446 PwrCnvrtr1LmtsAtvDEnrgSr1Cr "Power Converter 1 Limits Active DC Energy Source 1 CRC: The CRC is defined as follows: - Length: 8 bits- Polynomial: x^8+x^5+x^3+x^2+x+1- Initial Value: FFh- Input Data Reflection: Not reflected- Result Data Reflection: Not reflected- XOR value: FFh ...";
CM_ SG_ 2565896446 PwrCnvrtr1LmtsAtvDEnrgSr1Cntr "Power Converter 1 Limits Active DC Energy Source 1 Counter: The message counter is used to detect situations where the transmitting ECU malfunction repeats the same frame all the time. The receiver of the information may use the counter parameter to ...";
CM_ SG_ 2565896446 PwCvt1LtsAtvDES1VtMx "Power Converter 1 Limits Active DC Energy Source 1 Voltage Maximum: the Power Converter keeps the DC Energy Source 1 voltage below this value.  This limit may be set in response to a Limits Request or determined by the Power Converter based on operat...";
CM_ SG_ 2565896446 PwCvt1LtsAtvDES1VtM "Power Converter 1 Limits Active DC Energy Source 1 Voltage Minimum: the Power Converter keeps the DC Energy Source 1 voltage above this value.  This limit may be set in response to a Limits Request or determined by the Power Converter based on operat...";
CM_ SG_ 2565896446 PwCvt1LtsAtvDES1CtMx "Power Converter 1 Limits Active DC Energy Source 1 Current Maximum: the Power Converter keeps the DC Energy Source 1 current below this value.  This limit may be set in response to a Limits Request or determined by the Power Converter based on operat...";
CM_ SG_ 2565896446 PwCvt1LtsAtvDES1CtM "Power Converter 1 Limits Active DC Energy Source 1 Current Minimum: the Power Converter keeps the DC Energy Source 1 current above this value.  This limit may be set in response to a Limits Request or determined by the Power Converter based on operat...";
CM_ BO_ 2565896702 "Power Converter 1 Low Voltage";
CM_ SG_ 2565896702 PwrCnvrtr1SwthdIgntnVltg "Power Converter 1 Switched Ignition Voltage: Switched Ignition voltage supplied to this instance of the Power Converter controller.";
CM_ SG_ 2565896702 PwrCnvrtr1UnswthdSlVltg "Power Converter 1 Unswitched SLI Voltage: Continuously supplied SLI power to this instance of the Power Converter controller.";
CM_ BO_ 2364570366 "Power Converter 2 Mode Feedback 1";
CM_ SG_ 2364570366 PowerConverter2ModeFeedback1Crc "Power Converter 2 Mode Feedback 1 CRC: The CRC is defined as follows: - Length: 8 bits- Polynomial: x^8+x^5+x^3+x^2+x+1- Initial Value: FFh- Input Data Reflection: Not reflected- Result Data Reflection: Not reflected- XOR value: FFh SAE makes no clai...";
CM_ SG_ 2364570366 PwrCnvrtr2MdFdk1Cntr "Power Converter 2 Mode Feedback 1 Counter: The message counter is used to detect situations where the transmitting ECU malfunction repeats the same frame all the time. The receiver of the information may use the counter parameter to detect this situa...";
CM_ SG_ 2364570366 PwrCnvrtr2CntrlLmtsOvrrdMd "Power Converter 2 Control Limits Override Mode: During normal operation this will have the same value as SPN 20474 (Power Converter 2 Control Limits Request Override Mode).0 = Operating limits are not overridden.  If a limit was previously active, th...";
CM_ SG_ 2364570366 PwrCnvrtr2CntrlStpntMd "Power Converter 2 Control Setpoint Mode: Reports the Power Converter mode (See SPN 20477 (Power Converter 2 Control Setpoint Mode Request) for requested mode).Passive modes:  0 = Powered On - the Power Converter is commanded to be powered on and able...";
CM_ SG_ 2364570366 PowerConverter2HvilStatus "Power Converter 2 HVIL Status: Reports the High Voltage Interlock Loop (HVIL) state.00b = HVIL Closed01b = HVIL Open10b = Error11b = Not Available";
CM_ BO_ 2565897214 "Power Converter 2 Limits Active Power";
CM_ SG_ 2565897214 PwrCnvrtr2LmtsAtvPwrCr "Power Converter 2 Limits Active Power CRC: The CRC is defined as follows: - Length: 8 bits- Polynomial: x^8+x^5+x^3+x^2+x+1- Initial Value: FFh- Input Data Reflection: Not reflected- Result Data Reflection: Not reflected- XOR value: FFh SAE makes no ...";
CM_ SG_ 2565897214 PwrCnvrtr2LmtsAtvPwrCntr "Power Converter 2 Limits Active Power Counter: The message counter is used to detect situations where the transmitting ECU malfunction repeats the same frame all the time. The receiver of the information may use the counter parameter to detect this s...";
CM_ SG_ 2565897214 PwrCnvrtr2LmtsAtvEltrlPwrMxmm "Power Converter 2 Limits Active Electrical Power Maximum: the Power Converter keeps the electrical system power below this value.   This limit may be set in response to a Limits Request or determined by the Power Converter based on operating conditio...";
CM_ SG_ 2565897214 PwrCnvrtr2LmtsAtvEltrlPwrMnmm "Power Converter 2 Limits Active Electrical Power Minimum: the Power Converter keeps the electrical system power above this value.   This limit may be set in response to a Limits Request or determined by the Power Converter based on operating conditio...";
CM_ SG_ 2565897214 PwCvt2LtsAtvDES1PwMx "Power Converter 2 Limits Active DC Energy Source 1 Power Maximum: the Power Converter keeps the DC Energy Source 1 power below this value.   This limit may be set in response to a Limits Request or determined by the Power Converter based on operating...";
CM_ SG_ 2565897214 PwCvt2LtsAtvDES1PwM "Power Converter 2 Limits Active DC Energy Source 1 Power Minimum: the Power Converter keeps the DC Energy Source 1 power above this value.   This limit may be set in response to a Limits Request or determined by the Power Converter based on operating...";
CM_ BO_ 2565897470 "Power Converter 2 Limits Active Electrical";
CM_ SG_ 2565897470 PwrCnvrtr2LmtsAtvEltrlCr "Power Converter 2 Limits Active Electrical CRC: The CRC is defined as follows: - Length: 8 bits- Polynomial: x^8+x^5+x^3+x^2+x+1- Initial Value: FFh- Input Data Reflection: Not reflected- Result Data Reflection: Not reflected- XOR value: FFh SAE make...";
CM_ SG_ 2565897470 PwrCnvrtr2LmtsAtvEltrlCntr "Power Converter 2 Limits Active Electrical Counter: The message counter is used to detect situations where the transmitting ECU malfunction repeats the same frame all the time. The receiver of the information may use the counter parameter to detect t...";
CM_ SG_ 2565897470 PwrCnvrtr2LmtsAtvCrrntMxmm "Power Converter 2 Limits Active Current Maximum: the Power Converter keeps the system current below this value.  This limit may be set in response to a Limits Request or determined by the Power Converter based on operating conditions.Refer to SPN 206...";
CM_ SG_ 2565897470 PwrCnvrtr2LmtsAtvCrrntMnmm "Power Converter 2 Limits Active Current Minimum: the Power Converter keeps the system current above this value.  This limit may be set in response to a Limits Request or determined by the Power Converter based on operating conditions.Refer to SPN 206...";
CM_ SG_ 2565897470 PwrCnvrtr2LmtsAtvFrqnMxmm "Power Converter 2 Limits Active Frequency Maximum: the Power Converter keeps the system frequency below this value.  This limit may be set in response to a Limits Request or determined by the Power Converter based on operating conditions.Refer to SPN...";
CM_ SG_ 2565897470 PwrCnvrtr2LmtsAtvFrqnMnmm "Power Converter 2 Limits Active Frequency Minimum: the Power Converter keeps the system Frequency above this value.  This limit may be set in response to a Limits Request or determined by the Power Converter based on operating conditions.Refer to SPN...";
CM_ BO_ 2565897726 "Power Converter 2 Limits Active DC Energy Source 1";
CM_ SG_ 2565897726 PwrCnvrtr2LmtsAtvDEnrgSr1Cr "Power Converter 2 Limits Active DC Energy Source 1 CRC: The CRC is defined as follows: - Length: 8 bits- Polynomial: x^8+x^5+x^3+x^2+x+1- Initial Value: FFh- Input Data Reflection: Not reflected- Result Data Reflection: Not reflected- XOR value: FFh ...";
CM_ SG_ 2565897726 PwrCnvrtr2LmtsAtvDEnrgSr1Cntr "Power Converter 2 Limits Active DC Energy Source 1 Counter: The message counter is used to detect situations where the transmitting ECU malfunction repeats the same frame all the time. The receiver of the information may use the counter parameter to ...";
CM_ SG_ 2565897726 PwCvt2LtsAtvDES1VtMx "Power Converter 2 Limits Active DC Energy Source 1 Voltage Maximum: the Power Converter keeps the DC Energy Source 1 voltage below this value.  This limit may be set in response to a Limits Request or determined by the Power Converter based on operat...";
CM_ SG_ 2565897726 PwCvt2LtsAtvDES1VtM "Power Converter 2 Limits Active DC Energy Source 1 Voltage Minimum: the Power Converter keeps the DC Energy Source 1 voltage above this value.  This limit may be set in response to a Limits Request or determined by the Power Converter based on operat...";
CM_ SG_ 2565897726 PwCvt2LtsAtvDES1CtMx "Power Converter 2 Limits Active DC Energy Source 1 Current Maximum: the Power Converter keeps the DC Energy Source 1 current below this value.  This limit may be set in response to a Limits Request or determined by the Power Converter based on operat...";
CM_ SG_ 2565897726 PwCvt2LtsAtvDES1CtM "Power Converter 2 Limits Active DC Energy Source 1 Current Minimum: the Power Converter keeps the DC Energy Source 1 current above this value.  This limit may be set in response to a Limits Request or determined by the Power Converter based on operat...";
CM_ BO_ 2565897982 "Power Converter 2 Low Voltage";
CM_ SG_ 2565897982 PwrCnvrtr2SwthdIgntnVltg "Power Converter 2 Switched Ignition Voltage: Switched Ignition voltage supplied to this instance of the Power Converter controller.";
CM_ SG_ 2565897982 PwrCnvrtr2UnswthdSlVltg "Power Converter 2 Unswitched SLI Voltage: Continuously supplied SLI power to this instance of the Power Converter controller.";
CM_ BO_ 2565898238 "Power Converter 1 Status 2";
CM_ SG_ 2565898238 PowerConverter1Status2Crc "Power Converter 1 Status 2 CRC: The CRC is defined as follows: - Length: 8 bits- Polynomial: x^8+x^5+x^3+x^2+x+1- Initial Value: FFh- Input Data Reflection: Not reflected- Result Data Reflection: Not reflected- XOR value: FFh SAE makes no claim of th...";
CM_ SG_ 2565898238 PowerConverter1Status2Counter "Power Converter 1 Status 2 Counter: The message counter is used to detect situations where the transmitting ECU malfunction repeats the same frame all the time. The receiver of the information may use the counter parameter to detect this situation. T...";
CM_ SG_ 2565898238 PwrCnvrtr1AvllMxmmCrrnt "Power Converter 1 Available Maximum Current: This is an estimate of the maximum available system current including active deratings.Refer to SPN 20690 (Power Converter 1 Reference Current) to convert % to A.The system is regenerating when SPN 20695(P...";
CM_ SG_ 2565898238 PwrCnvrtr1AvllMnmmCrrnt "Power Converter 1 Available Minimum Current: This is an estimate of the minimum available system current including active deratings.   Refer to SPN 20690 (Power Converter 1 Reference Current) to convert % to A.The system is regenerating when SPN 2069...";
CM_ BO_ 2565898494 "Power Converter 1 Rate Limits Active 1";
CM_ SG_ 2565898494 PwrCnvrtr1RtLmtsAtv1Cr "Power Converter 1 Rate Limits Active 1 CRC: The CRC is defined as follows: - Length: 8 bits- Polynomial: x^8+x^5+x^3+x^2+x+1- Initial Value: FFh- Input Data Reflection: Not reflected- Result Data Reflection: Not reflected- XOR value: FFh SAE makes no...";
CM_ SG_ 2565898494 PwrCnvrtr1RtLmtsAtv1Cntr "Power Converter 1 Rate Limits Active 1 Counter: The message counter is used to detect situations where the transmitting ECU malfunction repeats the same frame all the time. The receiver of the information may use the counter parameter to detect this ...";
CM_ SG_ 2565898494 PwCvt1RtLtsAtvAstCtRtLt "Power Converter 1 Rate Limits Active Absolute Current Rate Limit: The active maximum rate of change for the absolute system current (i.e. |d(current)|/dt) in all control modes of this Power Converter instance. Refer to SPN 20690 (Power Converter 1 Re...";
CM_ BO_ 2565898750 "Power Converter 2 Status 2";
CM_ SG_ 2565898750 PowerConverter2Status2Crc "Power Converter 2 Status 2 CRC: The CRC is defined as follows: - Length: 8 bits- Polynomial: x^8+x^5+x^3+x^2+x+1- Initial Value: FFh- Input Data Reflection: Not reflected- Result Data Reflection: Not reflected- XOR value: FFh SAE makes no claim of th...";
CM_ SG_ 2565898750 PowerConverter2Status2Counter "Power Converter 2 Status 2 Counter: The message counter is used to detect situations where the transmitting ECU malfunction repeats the same frame all the time. The receiver of the information may use the counter parameter to detect this situation. T...";
CM_ SG_ 2565898750 PwrCnvrtr2AvllMxmmCrrnt "Power Converter 2 Available Maximum Current: This is an estimate of the maximum available system current including active deratings. Refer to SPN 20667 (Power Converter 2 Reference Current) to convert % to A.The system is regenerating when SPN 20673(...";
CM_ SG_ 2565898750 PwrCnvrtr2AvllMnmmCrrnt "Power Converter 2 Available Minimum Current: This is an estimate of the minimum available system current including active deratings.  Refer to SPN 20667 (Power Converter 2 Reference Current) to convert % to A.The system is regenerating when SPN 20673...";
CM_ BO_ 2565899006 "Power Converter 2 Rate Limits Active 1";
CM_ SG_ 2565899006 PwrCnvrtr2RtLmtsAtv1Cr "Power Converter 2 Rate Limits Active 1 CRC: The CRC is defined as follows: - Length: 8 bits- Polynomial: x^8+x^5+x^3+x^2+x+1- Initial Value: FFh- Input Data Reflection: Not reflected- Result Data Reflection: Not reflected- XOR value: FFh SAE makes no...";
CM_ SG_ 2565899006 PwrCnvrtr2RtLmtsAtv1Cntr "Power Converter 2 Rate Limits Active 1 Counter: The message counter is used to detect situations where the transmitting ECU malfunction repeats the same frame all the time. The receiver of the information may use the counter parameter to detect this ...";
CM_ SG_ 2565899006 PwCvt2RtLtsAtvAstCtRtLt "Power Converter 2 Rate Limits Active Absolute Current Rate Limit: the Power Converter reports its active maximum rate of change for the absolute system current (i.e. |d(current)|/dt) in all control modes. Refer to SPN 20667 (Power Converter 2 Referen...";
CM_ BO_ 2565899262 "Power Converter 2 Isolation Integrity";
CM_ SG_ 2565899262 PwrCnvrtr2IsltnIntgrtCr "Power Converter 2 Isolation Integrity CRC: The CRC is defined as follows: - Length: 8 bits- Polynomial: x^8+x^5+x^3+x^2+x+1- Initial Value: FFh- Input Data Reflection: Not reflected- Result Data Reflection: Not reflected- XOR value: FFh SAE makes no ...";
CM_ SG_ 2565899262 PwrCnvrtr2IsltnIntgrtCntr "Power Converter 2 Isolation Integrity Counter: The message counter is used to detect situations where the transmitting ECU malfunction repeats the same frame all the time. The receiver of the information may use the counter parameter to detect this s...";
CM_ SG_ 2565899262 PwCvt2DES1NtvTCsssGdVt "Power Converter 2 DC Energy Source 1 Negative to Chassis Ground Voltage: The voltage level of the high voltage DC Energy Source 1, as measured by the Power Converter between the negative side of the High Voltage DC Energy Source 1 input and the chass...";
CM_ SG_ 2565899262 PwCvt2HVtBsAtvIstTstStts "Power Converter 2 High-Voltage Bus Active Isolation Test Status: Status of the high-voltage bus electrical active isolation test as performed by this instance of the Power Converter.0000b = No test requested / No test in process0001b = Test requested...";
CM_ SG_ 2565899262 PwCvt2HVtBsPssvIstTstStts "Power Converter 2 High-Voltage Bus Passive Isolation Test Status: Status of the high-voltage bus electrical passive isolation test as performed by this instance of the Power Converter.0000b = No test requested / No test in process0001b = Test request...";
CM_ SG_ 2565899262 PwCvt2HVtBsAtvIstTstRsts "Power Converter 2 High-Voltage Bus Active Isolation Test Results: The isolation resistance that resulted from the High-Voltage Bus Active Isolation Test.See SPN 20636 (Power Converter 2 High-Voltage Bus Active Isolation Test Status) for test status a...";
CM_ SG_ 2565899262 PwCvt2HVtBsPssvIstTstRsts "Power Converter 2 High-Voltage Bus Passive Isolation Test Results: The isolation resistance that resulted from the High-Voltage Bus Passive Isolation Test.See SPN 20637 (Power Converter 2 High-Voltage Bus Passive Isolation Test Status) for test statu...";
CM_ BO_ 2565899518 "Power Converter 1 Isolation Integrity";
CM_ SG_ 2565899518 PwrCnvrtr1IsltnIntgrtCr "Power Converter 1 Isolation Integrity CRC: The CRC is defined as follows: - Length: 8 bits- Polynomial: x^8+x^5+x^3+x^2+x+1- Initial Value: FFh- Input Data Reflection: Not reflected- Result Data Reflection: Not reflected- XOR value: FFh SAE makes no ...";
CM_ SG_ 2565899518 PwrCnvrtr1IsltnIntgrtCntr "Power Converter 1 Isolation Integrity Counter: The message counter is used to detect situations where the transmitting ECU malfunction repeats the same frame all the time. The receiver of the information may use the counter parameter to detect this s...";
CM_ SG_ 2565899518 PwCvt1DES1NtvTCsssGdVt "Power Converter 1 DC Energy Source 1 Negative to Chassis Ground Voltage: The voltage level of the high voltage DC Energy Source 1, as measured by the Power Converter between the negative side of the High Voltage DC Energy Source 1 input and the chass...";
CM_ SG_ 2565899518 PwCvt1HVtBsAtvIstTstStts "Power Converter 1 High-Voltage Bus Active Isolation Test Status: Status of the high-voltage bus electrical active isolation test as performed by this instance of the Power Converter.0000b = No test requested / No test in process0001b = Test requested...";
CM_ SG_ 2565899518 PwCvt1HVtBsPssvIstTstStts "Power Converter 1 High-Voltage Bus Passive Isolation Test Status: Status of the high-voltage bus electrical passive isolation test as performed by this instance of the Power Converter.0000b = No test requested / No test in process0001b = Test request...";
CM_ SG_ 2565899518 PwCvt1HVtBsAtvIstTstRsts "Power Converter 1 High-Voltage Bus Active Isolation Test Results: The isolation resistance that resulted from the High-Voltage Bus Active Isolation Test.See SPN 20661 (Power Converter 1 High-Voltage Bus Active Isolation Test Status) for test status a...";
CM_ SG_ 2565899518 PwCvt1HVtBsPssvIstTstRsts "Power Converter 1 High-Voltage Bus Passive Isolation Test Results: The isolation resistance that resulted from the High-Voltage Bus Passive Isolation Test.See SPN 20662 (Power Converter 1 High-Voltage Bus Passive Isolation Test Status) for test statu...";
BA_DEF_ SG_  "SPN" INT 0 524287;
BA_DEF_ BO_  "VFrameFormat" ENUM  "StandardCAN","ExtendedCAN","reserved","J1939PG";
BA_DEF_DEF_  "SPN" 0;
BA_DEF_DEF_  "VFrameFormat" "J1939PG";
BA_ "SPN" SG_ 2566565374 Hvesp9NominalVoltage 14457;
BA_ "SPN" SG_ 2566565374 Hvesp9CellMaximumVoltageLimit 14464;
BA_ "SPN" SG_ 2566565374 Hvesp9CellMinimumVoltageLimit 14465;
BA_ "SPN" SG_ 2566565374 Hvsp9RmmnddMnmmOprtngVltg 14458;
BA_ "SPN" SG_ 2566565374 Hvsp9RmmnddMxmmOprtngVltg 14459;
BA_ "SPN" SG_ 2566565374 Hvsp9RmmnddMnmmSttOfChrg 14460;
BA_ "SPN" SG_ 2566565374 Hvsp9RmmnddMxmmSttOfChrg 14461;
BA_ "SPN" SG_ 2566565374 Hvsp9RmmnddMxmmOprtngTmprtr 14462;
BA_ "SPN" SG_ 2566565374 Hvsp9RmmnddMnmmOprtngTmprtr 14463;
BA_ "SPN" SG_ 2633674494 Hvesp9StateOfHealth 14449;
BA_ "SPN" SG_ 2633674494 Hvesp9TotalEnergyThroughput 14451;
BA_ "SPN" SG_ 2633674494 Hvesp9TotalAccumulatedCharge 14452;
BA_ "SPN" SG_ 2633674494 Hvesp9TotalLifetimeEnergyInput 14453;
BA_ "SPN" SG_ 2633674494 Hvesp9TotalLifetimeEnergyOutput 14454;
BA_ "SPN" SG_ 2633674494 Hvsp9CnttrOpnUndrLdCnt 14450;
BA_ "SPN" SG_ 2566565886 Hvesp8NominalVoltage 14314;
BA_ "SPN" SG_ 2566565886 Hvesp8CellMaximumVoltageLimit 14321;
BA_ "SPN" SG_ 2566565886 Hvesp8CellMinimumVoltageLimit 14322;
BA_ "SPN" SG_ 2566565886 Hvsp8RmmnddMnmmOprtngVltg 14315;
BA_ "SPN" SG_ 2566565886 Hvsp8RmmnddMxmmOprtngVltg 14316;
BA_ "SPN" SG_ 2566565886 Hvsp8RmmnddMnmmSttOfChrg 14317;
BA_ "SPN" SG_ 2566565886 Hvsp8RmmnddMxmmSttOfChrg 14318;
BA_ "SPN" SG_ 2566565886 Hvsp8RmmnddMxmmOprtngTmprtr 14319;
BA_ "SPN" SG_ 2566565886 Hvsp8RmmnddMnmmOprtngTmprtr 14320;
BA_ "SPN" SG_ 2633675006 Hvesp8StateOfHealth 14306;
BA_ "SPN" SG_ 2633675006 Hvesp8TotalEnergyThroughput 14308;
BA_ "SPN" SG_ 2633675006 Hvesp8TotalAccumulatedCharge 14309;
BA_ "SPN" SG_ 2633675006 Hvesp8TotalLifetimeEnergyInput 14310;
BA_ "SPN" SG_ 2633675006 Hvesp8TotalLifetimeEnergyOutput 14311;
BA_ "SPN" SG_ 2633675006 Hvsp8CnttrOpnUndrLdCnt 14307;
BA_ "SPN" SG_ 2566566398 Hvesp7NominalVoltage 14171;
BA_ "SPN" SG_ 2566566398 Hvesp7CellMaximumVoltageLimit 14178;
BA_ "SPN" SG_ 2566566398 Hvesp7CellMinimumVoltageLimit 14179;
BA_ "SPN" SG_ 2566566398 Hvsp7RmmnddMnmmOprtngVltg 14172;
BA_ "SPN" SG_ 2566566398 Hvsp7RmmnddMxmmOprtngVltg 14173;
BA_ "SPN" SG_ 2566566398 Hvsp7RmmnddMnmmSttOfChrg 14174;
BA_ "SPN" SG_ 2566566398 Hvsp7RmmnddMxmmSttOfChrg 14175;
BA_ "SPN" SG_ 2566566398 Hvsp7RmmnddMxmmOprtngTmprtr 14176;
BA_ "SPN" SG_ 2566566398 Hvsp7RmmnddMnmmOprtngTmprtr 14177;
BA_ "SPN" SG_ 2633675518 Hvesp7StateOfHealth 14163;
BA_ "SPN" SG_ 2633675518 Hvesp7TotalEnergyThroughput 14165;
BA_ "SPN" SG_ 2633675518 Hvesp7TotalAccumulatedCharge 14166;
BA_ "SPN" SG_ 2633675518 Hvesp7TotalLifetimeEnergyInput 14167;
BA_ "SPN" SG_ 2633675518 Hvesp7TotalLifetimeEnergyOutput 14168;
BA_ "SPN" SG_ 2633675518 Hvsp7CnttrOpnUndrLdCnt 14164;
BA_ "SPN" SG_ 2566567166 HrdOrEvDChrgngVltgMxmm 13155;
BA_ "SPN" SG_ 2566567166 HrdOrEvDChrgngCrrntMxmm 13156;
BA_ "SPN" SG_ 2566567166 HrdOrEvDChrgngPwrMxmm 13157;
BA_ "SPN" SG_ 2566567166 HrdOrEvRqstdEnrgTrnsfrTp 13158;
BA_ "SPN" SG_ 2566567422 EvseDcChargingVoltageMaximum 13159;
BA_ "SPN" SG_ 2566567422 EvseDcChargingCurrentMaximum 13160;
BA_ "SPN" SG_ 2566567422 EvseDcChargingPowerMaximum 13161;
BA_ "SPN" SG_ 2566567422 EvsSpprtdEnrgTrnsfrTps 13162;
BA_ "SPN" SG_ 2566567678 EvseDcChargingVoltageMinimum 13163;
BA_ "SPN" SG_ 2566567678 EvseDcChargingCurrentMinimum 13164;
BA_ "SPN" SG_ 2566567678 EvsePeakCurrentRipple 13165;
BA_ "SPN" SG_ 2566567678 EvseCurrentRegulationTolerance 13166;
BA_ "SPN" SG_ 2566567934 DcChargingTargetCrc 13167;
BA_ "SPN" SG_ 2566567934 DcChargingTargetSequenceCounter 13168;
BA_ "SPN" SG_ 2566567934 DcTargetChargingVoltage 13169;
BA_ "SPN" SG_ 2566567934 DcTargetChargingCurrent 13170;
BA_ "SPN" SG_ 2566568190 EvseDcChargingState 13171;
BA_ "SPN" SG_ 2566568190 EvseIsolationStatus 21087;
BA_ "SPN" SG_ 2566568190 EvsePresentDcChargingVoltage 13172;
BA_ "SPN" SG_ 2566568190 EvsePresentDcChargingCurrent 13173;
BA_ "SPN" SG_ 2566568190 EvseVoltageLimitAchieved 13174;
BA_ "SPN" SG_ 2566568190 EvseCurrentLimitAchieved 13175;
BA_ "SPN" SG_ 2566568190 EvsePowerLimitAchieved 13176;
BA_ "SPN" SG_ 2566568190 EvseProcessingState 21088;
BA_ "SPN" SG_ 2566568190 EvseStatus 13177;
BA_ "SPN" SG_ 2566568190 EvseResponseCode 21089;
BA_ "SPN" SG_ 2566568446 HrdOrEvDInltCnttr1Cmmnd 13178;
BA_ "SPN" SG_ 2566568702 HrdOrEvDCnttrInptVltg 13179;
BA_ "SPN" SG_ 2566568702 HybridOrEvDcChargingBusVoltage 13180;
BA_ "SPN" SG_ 2566568702 HrdOrEvDInltCnttr1Stt 13181;
BA_ "SPN" SG_ 2566568958 TrnsmssnOlTmprtrHghLmpCmmnd 13116;
BA_ "SPN" SG_ 2566568958 TrnsmssnOlPrssrLwLmpCmmnd 13117;
BA_ "SPN" SG_ 2566569214 TrnsmssnOlTmprtrHghLmpDt 13129;
BA_ "SPN" SG_ 2566569214 TrnsmssnOlPrssrLwLmpDt 13130;
BA_ "SPN" SG_ 2566569470 MtrGnrtr1TtlEnrgCnsmd 13081;
BA_ "SPN" SG_ 2566569470 MtrGnrtr1TtlEnrgGnrtd 13082;
BA_ "SPN" SG_ 2566569470 MtrGnrtr1TtlChrgCnsmd 13083;
BA_ "SPN" SG_ 2566569470 MtrGnrtr1TtlChrgGnrtd 13084;
BA_ "SPN" SG_ 2566569726 MtrGnrtr2TtlEnrgCnsmd 13085;
BA_ "SPN" SG_ 2566569726 MtrGnrtr2TtlEnrgGnrtd 13086;
BA_ "SPN" SG_ 2566569726 MtrGnrtr2TtlChrgCnsmd 13087;
BA_ "SPN" SG_ 2566569726 MtrGnrtr2TtlChrgGnrtd 13088;
BA_ "SPN" SG_ 2566569982 MtrGnrtr3TtlEnrgCnsmd 13089;
BA_ "SPN" SG_ 2566569982 MtrGnrtr3TtlEnrgGnrtd 13090;
BA_ "SPN" SG_ 2566569982 MtrGnrtr3TtlChrgCnsmd 13091;
BA_ "SPN" SG_ 2566569982 MtrGnrtr3TtlChrgGnrtd 13092;
BA_ "SPN" SG_ 2566570238 MtrGnrtr4TtlEnrgCnsmd 13093;
BA_ "SPN" SG_ 2566570238 MtrGnrtr4TtlEnrgGnrtd 13094;
BA_ "SPN" SG_ 2566570238 MtrGnrtr4TtlChrgCnsmd 13095;
BA_ "SPN" SG_ 2566570238 MtrGnrtr4TtlChrgGnrtd 13096;
BA_ "SPN" SG_ 2566570494 MtrGnrtr5TtlEnrgCnsmd 13097;
BA_ "SPN" SG_ 2566570494 MtrGnrtr5TtlEnrgGnrtd 13098;
BA_ "SPN" SG_ 2566570494 MtrGnrtr5TtlChrgCnsmd 13099;
BA_ "SPN" SG_ 2566570494 MtrGnrtr5TtlChrgGnrtd 13100;
BA_ "SPN" SG_ 2566570750 MtrGnrtr6TtlEnrgCnsmd 13101;
BA_ "SPN" SG_ 2566570750 MtrGnrtr6TtlEnrgGnrtd 13102;
BA_ "SPN" SG_ 2566570750 MtrGnrtr6TtlChrgCnsmd 13103;
BA_ "SPN" SG_ 2566570750 MtrGnrtr6TtlChrgGnrtd 13104;
BA_ "SPN" SG_ 2566571006 AirDryerCartridgeLifeRemaining 13073;
BA_ "SPN" SG_ 2566571006 AirSuspensionSupplyPressure2 13132;
BA_ "SPN" SG_ 2566571262 EvseNominalRmsVoltageLineToLine 13007;
BA_ "SPN" SG_ 2566571262 EvseNominalSupplyFrequency 13008;
BA_ "SPN" SG_ 2566571262 EvsNmnlRmsVltgLnTNtrl 13006;
BA_ "SPN" SG_ 2566571518 HvessChargerRmsCurrentL1 13009;
BA_ "SPN" SG_ 2566571518 HvessChargerRmsCurrentL2 13010;
BA_ "SPN" SG_ 2566571518 HvessChargerRmsCurrentL3 13011;
BA_ "SPN" SG_ 2566571518 HvessChargerNeutralRmsCurrent 13012;
BA_ "SPN" SG_ 2499462910 RtrdrRdSpdDlrtSwth 12988;
BA_ "SPN" SG_ 2499462910 RtrdrRdSpdAlrtSwth 12989;
BA_ "SPN" SG_ 2566572286 TransmissionClutch1Temperature 5939;
BA_ "SPN" SG_ 2566572286 TrnsmssnClth1OvrhtIndtr 12965;
BA_ "SPN" SG_ 2566572286 TransmissionLaunchCapability 21218;
BA_ "SPN" SG_ 2566572286 TransmissionGearShiftCapability 21219;
BA_ "SPN" SG_ 2566572286 TrnsmssnDmgThrshldStts 21220;
BA_ "SPN" SG_ 2499464702 Aftrtrtmnt1SrOtltAsltPrssr 11773;
BA_ "SPN" SG_ 2499464702 Aftrtrtmnt1SrOtltPrssr 11775;
BA_ "SPN" SG_ 2566573822 TransmissionPtoGearboxStatus 12961;
BA_ "SPN" SG_ 2566573822 TrnsmssnPtGrxOtptShftSpd 12960;
BA_ "SPN" SG_ 2364690686 AxlrTrnsmssnOtptSpd 15204;
BA_ "SPN" SG_ 2566563326 BddDFMdEsttdIsttsFSvsRt 15231;
BA_ "SPN" SG_ 2566563326 BlnddDlFlMdOprtngStts 21143;
BA_ "SPN" SG_ 2566563326 BlendedDualFuelModeStatusReason 21144;
BA_ "SPN" SG_ 2566563582 BlnddDlFlMdTtlDslFlDmnd 15230;
BA_ "SPN" SG_ 2566563582 BlnddDlFlMdTtlDslFlDspldBGssFl 15229;
BA_ "SPN" SG_ 2566563838 BlnddDlFlMdTtlDslFlUsd 15224;
BA_ "SPN" SG_ 2566563838 BlnddDlFlMdTtlDslFlPrntDspld 15225;
BA_ "SPN" SG_ 2566563838 BlnddDlFlMdPrntTmAtv 15226;
BA_ "SPN" SG_ 2566563838 BlnddDlFlMdDslFlPrntDspld 15227;
BA_ "SPN" SG_ 2566563838 BddDFMdEsttdIsttsDsSvsRtPt 15228;
BA_ "SPN" SG_ 2566564094 Trnsmssn1TtlOtptShftRvltns 15222;
BA_ "SPN" SG_ 2566564094 Trnsmssn1OprtnTmSnRld 15223;
BA_ "SPN" SG_ 2566564094 Trnsmssn1TtlHrsOfOprtn 15221;
BA_ "SPN" SG_ 2566564350 Trnsmssn1InptShftPkTwst 15218;
BA_ "SPN" SG_ 2566564350 Trnsmssn1OtptShftPkTwst 15219;
BA_ "SPN" SG_ 2566564350 Trnsmssn1IntrmdtShftPkTwst 15220;
BA_ "SPN" SG_ 2566564606 AxlrTrnsmssnSltdGr 15202;
BA_ "SPN" SG_ 2566564606 AxlrTrnsmssnCrrntGr 15203;
BA_ "SPN" SG_ 2349858558 Hvsp11HghVltgBsCnntCmmnd 15269;
BA_ "SPN" SG_ 2349858558 Hvesp11PowerDownCommand 15270;
BA_ "SPN" SG_ 2349858558 Hvsp11HghVltgBsAtvIsltnTstCmmnd 15271;
BA_ "SPN" SG_ 2349858558 Hvsp11HVtBsPssvIstTstCd 15272;
BA_ "SPN" SG_ 2349858558 Hvesp11CellBalancingCommand 15273;
BA_ "SPN" SG_ 2349858558 Hvsp11EnlIntrnlChrgrCmmnd 15274;
BA_ "SPN" SG_ 2349858558 Hvesp11OperationConsent 15275;
BA_ "SPN" SG_ 2349858558 Hvsp11HVtBsHSdRsstCtRqst 15276;
BA_ "SPN" SG_ 2349858558 Hvsp11HVtBsLwSdRsstCtRqst 15277;
BA_ "SPN" SG_ 2349858558 Hvsp11ThrmlMngmntMntnnRqst 20889;
BA_ "SPN" SG_ 2349858558 Hvesp11Control1Counter 15278;
BA_ "SPN" SG_ 2349858558 Hvesp11Control1Crc 15279;
BA_ "SPN" SG_ 2349924094 Hvsp12HghVltgBsCnntCmmnd 15411;
BA_ "SPN" SG_ 2349924094 Hvesp12PowerDownCommand 15412;
BA_ "SPN" SG_ 2349924094 Hvsp12HghVltgBsAtvIsltnTstCmmnd 15413;
BA_ "SPN" SG_ 2349924094 Hvsp12HVtBsPssvIstTstCd 15414;
BA_ "SPN" SG_ 2349924094 Hvesp12CellBalancingCommand 15415;
BA_ "SPN" SG_ 2349924094 Hvsp12EnlIntrnlChrgrCmmnd 15416;
BA_ "SPN" SG_ 2349924094 Hvesp12OperationConsent 15417;
BA_ "SPN" SG_ 2349924094 Hvsp12HVtBsHSdRsstCtRqst 15418;
BA_ "SPN" SG_ 2349924094 Hvsp12HVtBsLwSdRsstCtRqst 15419;
BA_ "SPN" SG_ 2349924094 Hvsp12ThrmlMngmntMntnnRqst 20890;
BA_ "SPN" SG_ 2349924094 Hvesp12Control1Counter 15420;
BA_ "SPN" SG_ 2349924094 Hvesp12Control1Crc 15421;
BA_ "SPN" SG_ 2349989630 Hvsp13HghVltgBsCnntCmmnd 15553;
BA_ "SPN" SG_ 2349989630 Hvesp13PowerDownCommand 15554;
BA_ "SPN" SG_ 2349989630 Hvsp13HghVltgBsAtvIsltnTstCmmnd 15555;
BA_ "SPN" SG_ 2349989630 Hvsp13HVtBsPssvIstTstCd 15556;
BA_ "SPN" SG_ 2349989630 Hvesp13CellBalancingCommand 15557;
BA_ "SPN" SG_ 2349989630 Hvsp13EnlIntrnlChrgrCmmnd 15558;
BA_ "SPN" SG_ 2349989630 Hvesp13OperationConsent 15559;
BA_ "SPN" SG_ 2349989630 Hvsp13HVtBsHSdRsstCtRqst 15560;
BA_ "SPN" SG_ 2349989630 Hvsp13HVtBsLwSdRsstCtRqst 15561;
BA_ "SPN" SG_ 2349989630 Hvsp13ThrmlMngmntMntnnRqst 20891;
BA_ "SPN" SG_ 2349989630 Hvesp13Control1Counter 15562;
BA_ "SPN" SG_ 2349989630 Hvesp13Control1Crc 15563;
BA_ "SPN" SG_ 2350055166 Hvsp14HghVltgBsCnntCmmnd 15695;
BA_ "SPN" SG_ 2350055166 Hvesp14PowerDownCommand 15696;
BA_ "SPN" SG_ 2350055166 Hvsp14HghVltgBsAtvIsltnTstCmmnd 15697;
BA_ "SPN" SG_ 2350055166 Hvsp14HVtBsPssvIstTstCd 15698;
BA_ "SPN" SG_ 2350055166 Hvesp14CellBalancingCommand 15699;
BA_ "SPN" SG_ 2350055166 Hvsp14EnlIntrnlChrgrCmmnd 15700;
BA_ "SPN" SG_ 2350055166 Hvesp14OperationConsent 15701;
BA_ "SPN" SG_ 2350055166 Hvsp14HVtBsHSdRsstCtRqst 15702;
BA_ "SPN" SG_ 2350055166 Hvsp14HVtBsLwSdRsstCtRqst 15703;
BA_ "SPN" SG_ 2350055166 Hvsp14ThrmlMngmntMntnnRqst 20892;
BA_ "SPN" SG_ 2350055166 Hvesp14Control1Counter 15704;
BA_ "SPN" SG_ 2350055166 Hvesp14Control1Crc 15705;
BA_ "SPN" SG_ 2350120702 Hvsp15HghVltgBsCnntCmmnd 15837;
BA_ "SPN" SG_ 2350120702 Hvesp15PowerDownCommand 15838;
BA_ "SPN" SG_ 2350120702 Hvsp15HghVltgBsAtvIsltnTstCmmnd 15839;
BA_ "SPN" SG_ 2350120702 Hvsp15HVtBsPssvIstTstCd 15840;
BA_ "SPN" SG_ 2350120702 Hvesp15CellBalancingCommand 15841;
BA_ "SPN" SG_ 2350120702 Hvsp15EnlIntrnlChrgrCmmnd 15842;
BA_ "SPN" SG_ 2350120702 Hvesp15OperationConsent 15843;
BA_ "SPN" SG_ 2350120702 Hvsp15HVtBsHSdRsstCtRqst 15844;
BA_ "SPN" SG_ 2350120702 Hvsp15HVtBsLwSdRsstCtRqst 15845;
BA_ "SPN" SG_ 2350120702 Hvsp15ThrmlMngmntMntnnRqst 20893;
BA_ "SPN" SG_ 2350120702 Hvesp15Control1Counter 15846;
BA_ "SPN" SG_ 2350120702 Hvesp15Control1Crc 15847;
BA_ "SPN" SG_ 2350186238 Hvsp16HghVltgBsCnntCmmnd 15979;
BA_ "SPN" SG_ 2350186238 Hvesp16PowerDownCommand 15980;
BA_ "SPN" SG_ 2350186238 Hvsp16HghVltgBsAtvIsltnTstCmmnd 15981;
BA_ "SPN" SG_ 2350186238 Hvsp16HVtBsPssvIstTstCd 15982;
BA_ "SPN" SG_ 2350186238 Hvesp16CellBalancingCommand 15983;
BA_ "SPN" SG_ 2350186238 Hvsp16EnlIntrnlChrgrCmmnd 15984;
BA_ "SPN" SG_ 2350186238 Hvesp16OperationConsent 15985;
BA_ "SPN" SG_ 2350186238 Hvsp16HVtBsHSdRsstCtRqst 15986;
BA_ "SPN" SG_ 2350186238 Hvsp16HVtBsLwSdRsstCtRqst 15987;
BA_ "SPN" SG_ 2350186238 Hvsp16ThrmlMngmntMntnnRqst 20894;
BA_ "SPN" SG_ 2350186238 Hvesp16Control1Counter 15988;
BA_ "SPN" SG_ 2350186238 Hvesp16Control1Crc 15989;
BA_ "SPN" SG_ 2350251774 Hvsp17HghVltgBsCnntCmmnd 16121;
BA_ "SPN" SG_ 2350251774 Hvesp17PowerDownCommand 16122;
BA_ "SPN" SG_ 2350251774 Hvsp17HghVltgBsAtvIsltnTstCmmnd 16123;
BA_ "SPN" SG_ 2350251774 Hvsp17HVtBsPssvIstTstCd 16124;
BA_ "SPN" SG_ 2350251774 Hvesp17CellBalancingCommand 16125;
BA_ "SPN" SG_ 2350251774 Hvsp17EnlIntrnlChrgrCmmnd 16126;
BA_ "SPN" SG_ 2350251774 Hvesp17OperationConsent 16127;
BA_ "SPN" SG_ 2350251774 Hvsp17HVtBsHSdRsstCtRqst 16128;
BA_ "SPN" SG_ 2350251774 Hvsp17HVtBsLwSdRsstCtRqst 16129;
BA_ "SPN" SG_ 2350251774 Hvsp17ThrmlMngmntMntnnRqst 20895;
BA_ "SPN" SG_ 2350251774 Hvesp17Control1Counter 16130;
BA_ "SPN" SG_ 2350251774 Hvesp17Control1Crc 16131;
BA_ "SPN" SG_ 2350317310 Hvsp18HghVltgBsCnntCmmnd 16263;
BA_ "SPN" SG_ 2350317310 Hvesp18PowerDownCommand 16264;
BA_ "SPN" SG_ 2350317310 Hvsp18HghVltgBsAtvIsltnTstCmmnd 16265;
BA_ "SPN" SG_ 2350317310 Hvsp18HVtBsPssvIstTstCd 16266;
BA_ "SPN" SG_ 2350317310 Hvesp18CellBalancingCommand 16267;
BA_ "SPN" SG_ 2350317310 Hvsp18EnlIntrnlChrgrCmmnd 16268;
BA_ "SPN" SG_ 2350317310 Hvesp18OperationConsent 16269;
BA_ "SPN" SG_ 2350317310 Hvsp18HVtBsHSdRsstCtRqst 16270;
BA_ "SPN" SG_ 2350317310 Hvsp18HVtBsLwSdRsstCtRqst 16271;
BA_ "SPN" SG_ 2350317310 Hvsp18ThrmlMngmntMntnnRqst 20896;
BA_ "SPN" SG_ 2350317310 Hvesp18Control1Counter 16272;
BA_ "SPN" SG_ 2350317310 Hvesp18Control1Crc 16273;
BA_ "SPN" SG_ 2350382846 Hvsp19HghVltgBsCnntCmmnd 16405;
BA_ "SPN" SG_ 2350382846 Hvesp19PowerDownCommand 16406;
BA_ "SPN" SG_ 2350382846 Hvsp19HghVltgBsAtvIsltnTstCmmnd 16407;
BA_ "SPN" SG_ 2350382846 Hvsp19HVtBsPssvIstTstCd 16408;
BA_ "SPN" SG_ 2350382846 Hvesp19CellBalancingCommand 16409;
BA_ "SPN" SG_ 2350382846 Hvsp19EnlIntrnlChrgrCmmnd 16410;
BA_ "SPN" SG_ 2350382846 Hvesp19OperationConsent 16411;
BA_ "SPN" SG_ 2350382846 Hvsp19HVtBsHSdRsstCtRqst 16412;
BA_ "SPN" SG_ 2350382846 Hvsp19HVtBsLwSdRsstCtRqst 16413;
BA_ "SPN" SG_ 2350382846 Hvsp19ThrmlMngmntMntnnRqst 20897;
BA_ "SPN" SG_ 2350382846 Hvesp19Control1Counter 16414;
BA_ "SPN" SG_ 2350382846 Hvesp19Control1Crc 16415;
BA_ "SPN" SG_ 2350448382 Hvsp20HghVltgBsCnntCmmnd 16547;
BA_ "SPN" SG_ 2350448382 Hvesp20PowerDownCommand 16548;
BA_ "SPN" SG_ 2350448382 Hvsp20HghVltgBsAtvIsltnTstCmmnd 16549;
BA_ "SPN" SG_ 2350448382 Hvsp20HVtBsPssvIstTstCd 16550;
BA_ "SPN" SG_ 2350448382 Hvesp20CellBalancingCommand 16551;
BA_ "SPN" SG_ 2350448382 Hvsp20EnlIntrnlChrgrCmmnd 16552;
BA_ "SPN" SG_ 2350448382 Hvesp20OperationConsent 16553;
BA_ "SPN" SG_ 2350448382 Hvsp20HVtBsHSdRsstCtRqst 16554;
BA_ "SPN" SG_ 2350448382 Hvsp20HVtBsLwSdRsstCtRqst 16555;
BA_ "SPN" SG_ 2350448382 Hvsp20ThrmlMngmntMntnnRqst 20898;
BA_ "SPN" SG_ 2350448382 Hvesp20Control1Counter 16556;
BA_ "SPN" SG_ 2350448382 Hvesp20Control1Crc 16557;
BA_ "SPN" SG_ 2350513918 Hvsp21HghVltgBsCnntCmmnd 16689;
BA_ "SPN" SG_ 2350513918 Hvesp21PowerDownCommand 16690;
BA_ "SPN" SG_ 2350513918 Hvsp21HghVltgBsAtvIsltnTstCmmnd 16691;
BA_ "SPN" SG_ 2350513918 Hvsp21HVtBsPssvIstTstCd 16692;
BA_ "SPN" SG_ 2350513918 Hvesp21CellBalancingCommand 16693;
BA_ "SPN" SG_ 2350513918 Hvsp21EnlIntrnlChrgrCmmnd 16694;
BA_ "SPN" SG_ 2350513918 Hvesp21OperationConsent 16695;
BA_ "SPN" SG_ 2350513918 Hvsp21HVtBsHSdRsstCtRqst 16696;
BA_ "SPN" SG_ 2350513918 Hvsp21HVtBsLwSdRsstCtRqst 16697;
BA_ "SPN" SG_ 2350513918 Hvsp21ThrmlMngmntMntnnRqst 20899;
BA_ "SPN" SG_ 2350513918 Hvesp21Control1Counter 16698;
BA_ "SPN" SG_ 2350513918 Hvesp21Control1Crc 16699;
BA_ "SPN" SG_ 2350579454 Hvsp22HghVltgBsCnntCmmnd 16831;
BA_ "SPN" SG_ 2350579454 Hvesp22PowerDownCommand 16832;
BA_ "SPN" SG_ 2350579454 Hvsp22HghVltgBsAtvIsltnTstCmmnd 16833;
BA_ "SPN" SG_ 2350579454 Hvsp22HVtBsPssvIstTstCd 16834;
BA_ "SPN" SG_ 2350579454 Hvesp22CellBalancingCommand 16835;
BA_ "SPN" SG_ 2350579454 Hvsp22EnlIntrnlChrgrCmmnd 16836;
BA_ "SPN" SG_ 2350579454 Hvesp22OperationConsent 16837;
BA_ "SPN" SG_ 2350579454 Hvsp22HVtBsHSdRsstCtRqst 16838;
BA_ "SPN" SG_ 2350579454 Hvsp22HVtBsLwSdRsstCtRqst 16839;
BA_ "SPN" SG_ 2350579454 Hvsp22ThrmlMngmntMntnnRqst 20900;
BA_ "SPN" SG_ 2350579454 Hvesp22Control1Counter 16840;
BA_ "SPN" SG_ 2350579454 Hvesp22Control1Crc 16841;
BA_ "SPN" SG_ 2350907134 Hvsp23HghVltgBsCnntCmmnd 16973;
BA_ "SPN" SG_ 2350907134 Hvesp23PowerDownCommand 16974;
BA_ "SPN" SG_ 2350907134 Hvsp23HghVltgBsAtvIsltnTstCmmnd 16975;
BA_ "SPN" SG_ 2350907134 Hvsp23HVtBsPssvIstTstCd 16976;
BA_ "SPN" SG_ 2350907134 Hvesp23CellBalancingCommand 16977;
BA_ "SPN" SG_ 2350907134 Hvsp23EnlIntrnlChrgrCmmnd 16978;
BA_ "SPN" SG_ 2350907134 Hvesp23OperationConsent 16979;
BA_ "SPN" SG_ 2350907134 Hvsp23HVtBsHSdRsstCtRqst 16980;
BA_ "SPN" SG_ 2350907134 Hvsp23HVtBsLwSdRsstCtRqst 16981;
BA_ "SPN" SG_ 2350907134 Hvsp23ThrmlMngmntMntnnRqst 20901;
BA_ "SPN" SG_ 2350907134 Hvesp23Control1Counter 16982;
BA_ "SPN" SG_ 2350907134 Hvesp23Control1Crc 16983;
BA_ "SPN" SG_ 2350972670 Hvsp24HghVltgBsCnntCmmnd 17115;
BA_ "SPN" SG_ 2350972670 Hvesp24PowerDownCommand 17116;
BA_ "SPN" SG_ 2350972670 Hvsp24HghVltgBsAtvIsltnTstCmmnd 17117;
BA_ "SPN" SG_ 2350972670 Hvsp24HVtBsPssvIstTstCd 17118;
BA_ "SPN" SG_ 2350972670 Hvesp24CellBalancingCommand 17119;
BA_ "SPN" SG_ 2350972670 Hvsp24EnlIntrnlChrgrCmmnd 17120;
BA_ "SPN" SG_ 2350972670 Hvesp24OperationConsent 17121;
BA_ "SPN" SG_ 2350972670 Hvsp24HVtBsHSdRsstCtRqst 17122;
BA_ "SPN" SG_ 2350972670 Hvsp24HVtBsLwSdRsstCtRqst 17123;
BA_ "SPN" SG_ 2350972670 Hvsp24ThrmlMngmntMntnnRqst 20902;
BA_ "SPN" SG_ 2350972670 Hvesp24Control1Counter 17124;
BA_ "SPN" SG_ 2350972670 Hvesp24Control1Crc 17125;
BA_ "SPN" SG_ 2351038206 Hvsp25HghVltgBsCnntCmmnd 17257;
BA_ "SPN" SG_ 2351038206 Hvesp25PowerDownCommand 17258;
BA_ "SPN" SG_ 2351038206 Hvsp25HghVltgBsAtvIsltnTstCmmnd 17259;
BA_ "SPN" SG_ 2351038206 Hvsp25HVtBsPssvIstTstCd 17260;
BA_ "SPN" SG_ 2351038206 Hvesp25CellBalancingCommand 17261;
BA_ "SPN" SG_ 2351038206 Hvsp25EnlIntrnlChrgrCmmnd 17262;
BA_ "SPN" SG_ 2351038206 Hvesp25OperationConsent 17263;
BA_ "SPN" SG_ 2351038206 Hvsp25HVtBsHSdRsstCtRqst 17264;
BA_ "SPN" SG_ 2351038206 Hvsp25HVtBsLwSdRsstCtRqst 17265;
BA_ "SPN" SG_ 2351038206 Hvsp25ThrmlMngmntMntnnRqst 20903;
BA_ "SPN" SG_ 2351038206 Hvesp25Control1Counter 17266;
BA_ "SPN" SG_ 2351038206 Hvesp25Control1Crc 17267;
BA_ "SPN" SG_ 2351103742 Hvsp26HghVltgBsCnntCmmnd 17399;
BA_ "SPN" SG_ 2351103742 Hvesp26PowerDownCommand 17400;
BA_ "SPN" SG_ 2351103742 Hvsp26HghVltgBsAtvIsltnTstCmmnd 17401;
BA_ "SPN" SG_ 2351103742 Hvsp26HVtBsPssvIstTstCd 17402;
BA_ "SPN" SG_ 2351103742 Hvesp26CellBalancingCommand 17403;
BA_ "SPN" SG_ 2351103742 Hvsp26EnlIntrnlChrgrCmmnd 17404;
BA_ "SPN" SG_ 2351103742 Hvesp26OperationConsent 17405;
BA_ "SPN" SG_ 2351103742 Hvsp26HVtBsHSdRsstCtRqst 17406;
BA_ "SPN" SG_ 2351103742 Hvsp26HVtBsLwSdRsstCtRqst 17407;
BA_ "SPN" SG_ 2351103742 Hvsp26ThrmlMngmntMntnnRqst 20904;
BA_ "SPN" SG_ 2351103742 Hvesp26Control1Counter 17408;
BA_ "SPN" SG_ 2351103742 Hvesp26Control1Crc 17409;
BA_ "SPN" SG_ 2555182846 EngnClntEltrPmpEnlCmmnd 20171;
BA_ "SPN" SG_ 2555182846 EngnClntEltrPmpPwrHld 20172;
BA_ "SPN" SG_ 2555182846 EngnClntEltrPmpDrvSr 20173;
BA_ "SPN" SG_ 2555182846 EngnClntEltrPmpSpdCmmnd 20174;
BA_ "SPN" SG_ 2555182846 EngnClntEltrPmpPrntSpd 20175;
BA_ "SPN" SG_ 2364567550 PowerConverter1ControlCrc 20465;
BA_ "SPN" SG_ 2364567550 PowerConverter1ControlCounter 20466;
BA_ "SPN" SG_ 2364567550 PwrCnvrtr1CntrlLmtsRqstOvrrdMd 20467;
BA_ "SPN" SG_ 2364567550 PwCvt1CtLtsRqstOvdMx 20468;
BA_ "SPN" SG_ 2364567550 PwCvt1CtLtsRqstOvdM 20469;
BA_ "SPN" SG_ 2364567550 PwrCnvrtr1CntrlStpntMdRqst 20470;
BA_ "SPN" SG_ 2364567550 PwrCnvrtr1CntrlStpntRqst 20471;
BA_ "SPN" SG_ 2364567806 PowerConverter2ControlCrc 20472;
BA_ "SPN" SG_ 2364567806 PowerConverter2ControlCounter 20473;
BA_ "SPN" SG_ 2364567806 PwrCnvrtr2CntrlLmtsRqstOvrrdMd 20474;
BA_ "SPN" SG_ 2364567806 PwCvt2CtLtsRqstOvdMx 20475;
BA_ "SPN" SG_ 2364567806 PwCvt2CtLtsRqstOvdM 20476;
BA_ "SPN" SG_ 2364567806 PwrCnvrtr2CntrlStpntMdRqst 20477;
BA_ "SPN" SG_ 2364567806 PwrCnvrtr2CntrlStpntRqst 20478;
BA_ "SPN" SG_ 2565894654 PwrCnvrtr1RtLmtsRqst1Cr 20479;
BA_ "SPN" SG_ 2565894654 PwrCnvrtr1RtLmtsRqst1Cntr 20480;
BA_ "SPN" SG_ 2565894654 PwCvt1RtLtsRqstAstFqRtLt 20481;
BA_ "SPN" SG_ 2565894654 PwCvt1RtLtsRqstAstCtRtLt 20482;
BA_ "SPN" SG_ 2565894910 PwrCnvrtr2RtLmtsRqst1Cr 20483;
BA_ "SPN" SG_ 2565894910 PwrCnvrtr2RtLmtsRqst1Cntr 20484;
BA_ "SPN" SG_ 2565894910 PwCvt2RtLtsRqstAstFqRtLt 20485;
BA_ "SPN" SG_ 2565894910 PwCvt2RtLtsRqstAstCtRtLt 20486;
BA_ "SPN" SG_ 2364568574 PowerConverter2Control2Crc 20487;
BA_ "SPN" SG_ 2364568574 PowerConverter2Control2Counter 20488;
BA_ "SPN" SG_ 2364568574 PwrCnvrtr2PdCntrlAppllMd 20489;
BA_ "SPN" SG_ 2364568574 PwCvt2PdCtNzdDtG 20490;
BA_ "SPN" SG_ 2364568574 PwrCnvrtr2PdCntrlNrmlzdIntgrlGn 20491;
BA_ "SPN" SG_ 2364568574 PwCvt2PdCtNzdPptG 20492;
BA_ "SPN" SG_ 2364568830 PowerConverter1Control2Crc 20493;
BA_ "SPN" SG_ 2364568830 PowerConverter1Control2Counter 20494;
BA_ "SPN" SG_ 2364568830 PwrCnvrtr1PdCntrlAppllMd 20495;
BA_ "SPN" SG_ 2364568830 PwCvt1PdCtNzdDtG 20496;
BA_ "SPN" SG_ 2364568830 PwrCnvrtr1PdCntrlNrmlzdIntgrlGn 20497;
BA_ "SPN" SG_ 2364568830 PwCvt1PdCtNzdPptG 20498;
BA_ "SPN" SG_ 2364569086 PowerConverter1ModeFeedback1Crc 20543;
BA_ "SPN" SG_ 2364569086 PwrCnvrtr1MdFdk1Cntr 20544;
BA_ "SPN" SG_ 2364569086 PwrCnvrtr1CntrlLmtsOvrrdMd 20545;
BA_ "SPN" SG_ 2364569086 PwrCnvrtr1CntrlStpntMd 20546;
BA_ "SPN" SG_ 2364569086 PowerConverter1HvilStatus 20547;
BA_ "SPN" SG_ 2565895934 PwrCnvrtr1LmtsAtvPwrCr 20548;
BA_ "SPN" SG_ 2565895934 PwrCnvrtr1LmtsAtvPwrCntr 20549;
BA_ "SPN" SG_ 2565895934 PwrCnvrtr1LmtsAtvEltrlPwrMxmm 20550;
BA_ "SPN" SG_ 2565895934 PwrCnvrtr1LmtsAtvEltrlPwrMnmm 20551;
BA_ "SPN" SG_ 2565895934 PwCvt1LtsAtvDES1PwMx 20552;
BA_ "SPN" SG_ 2565895934 PwCvt1LtsAtvDES1PwM 20553;
BA_ "SPN" SG_ 2565896190 PwrCnvrtr1LmtsAtvEltrlCr 20554;
BA_ "SPN" SG_ 2565896190 PwrCnvrtr1LmtsAtvEltrlCntr 20555;
BA_ "SPN" SG_ 2565896190 PwrCnvrtr1LmtsAtvCrrntMxmm 20556;
BA_ "SPN" SG_ 2565896190 PwrCnvrtr1LmtsAtvCrrntMnmm 20557;
BA_ "SPN" SG_ 2565896190 PwrCnvrtr1LmtsAtvFrqnMxmm 20558;
BA_ "SPN" SG_ 2565896190 PwrCnvrtr1LmtsAtvFrqnMnmm 20559;
BA_ "SPN" SG_ 2565896446 PwrCnvrtr1LmtsAtvDEnrgSr1Cr 20560;
BA_ "SPN" SG_ 2565896446 PwrCnvrtr1LmtsAtvDEnrgSr1Cntr 20561;
BA_ "SPN" SG_ 2565896446 PwCvt1LtsAtvDES1VtMx 20562;
BA_ "SPN" SG_ 2565896446 PwCvt1LtsAtvDES1VtM 20563;
BA_ "SPN" SG_ 2565896446 PwCvt1LtsAtvDES1CtMx 20564;
BA_ "SPN" SG_ 2565896446 PwCvt1LtsAtvDES1CtM 20565;
BA_ "SPN" SG_ 2565896702 PwrCnvrtr1SwthdIgntnVltg 20566;
BA_ "SPN" SG_ 2565896702 PwrCnvrtr1UnswthdSlVltg 20567;
BA_ "SPN" SG_ 2364570366 PowerConverter2ModeFeedback1Crc 20568;
BA_ "SPN" SG_ 2364570366 PwrCnvrtr2MdFdk1Cntr 20569;
BA_ "SPN" SG_ 2364570366 PwrCnvrtr2CntrlLmtsOvrrdMd 20570;
BA_ "SPN" SG_ 2364570366 PwrCnvrtr2CntrlStpntMd 20571;
BA_ "SPN" SG_ 2364570366 PowerConverter2HvilStatus 20572;
BA_ "SPN" SG_ 2565897214 PwrCnvrtr2LmtsAtvPwrCr 20573;
BA_ "SPN" SG_ 2565897214 PwrCnvrtr2LmtsAtvPwrCntr 20574;
BA_ "SPN" SG_ 2565897214 PwrCnvrtr2LmtsAtvEltrlPwrMxmm 20575;
BA_ "SPN" SG_ 2565897214 PwrCnvrtr2LmtsAtvEltrlPwrMnmm 20576;
BA_ "SPN" SG_ 2565897214 PwCvt2LtsAtvDES1PwMx 20577;
BA_ "SPN" SG_ 2565897214 PwCvt2LtsAtvDES1PwM 20578;
BA_ "SPN" SG_ 2565897470 PwrCnvrtr2LmtsAtvEltrlCr 20579;
BA_ "SPN" SG_ 2565897470 PwrCnvrtr2LmtsAtvEltrlCntr 20580;
BA_ "SPN" SG_ 2565897470 PwrCnvrtr2LmtsAtvCrrntMxmm 20581;
BA_ "SPN" SG_ 2565897470 PwrCnvrtr2LmtsAtvCrrntMnmm 20582;
BA_ "SPN" SG_ 2565897470 PwrCnvrtr2LmtsAtvFrqnMxmm 20583;
BA_ "SPN" SG_ 2565897470 PwrCnvrtr2LmtsAtvFrqnMnmm 20584;
BA_ "SPN" SG_ 2565897726 PwrCnvrtr2LmtsAtvDEnrgSr1Cr 20585;
BA_ "SPN" SG_ 2565897726 PwrCnvrtr2LmtsAtvDEnrgSr1Cntr 20586;
BA_ "SPN" SG_ 2565897726 PwCvt2LtsAtvDES1VtMx 20587;
BA_ "SPN" SG_ 2565897726 PwCvt2LtsAtvDES1VtM 20588;
BA_ "SPN" SG_ 2565897726 PwCvt2LtsAtvDES1CtMx 20589;
BA_ "SPN" SG_ 2565897726 PwCvt2LtsAtvDES1CtM 20590;
BA_ "SPN" SG_ 2565897982 PwrCnvrtr2SwthdIgntnVltg 20591;
BA_ "SPN" SG_ 2565897982 PwrCnvrtr2UnswthdSlVltg 20592;
BA_ "SPN" SG_ 2565898238 PowerConverter1Status2Crc 20593;
BA_ "SPN" SG_ 2565898238 PowerConverter1Status2Counter 20594;
BA_ "SPN" SG_ 2565898238 PwrCnvrtr1AvllMxmmCrrnt 20595;
BA_ "SPN" SG_ 2565898238 PwrCnvrtr1AvllMnmmCrrnt 20596;
BA_ "SPN" SG_ 2565898494 PwrCnvrtr1RtLmtsAtv1Cr 20597;
BA_ "SPN" SG_ 2565898494 PwrCnvrtr1RtLmtsAtv1Cntr 20598;
BA_ "SPN" SG_ 2565898494 PwCvt1RtLtsAtvAstCtRtLt 20599;
BA_ "SPN" SG_ 2565898750 PowerConverter2Status2Crc 20600;
BA_ "SPN" SG_ 2565898750 PowerConverter2Status2Counter 20601;
BA_ "SPN" SG_ 2565898750 PwrCnvrtr2AvllMxmmCrrnt 20602;
BA_ "SPN" SG_ 2565898750 PwrCnvrtr2AvllMnmmCrrnt 20603;
BA_ "SPN" SG_ 2565899006 PwrCnvrtr2RtLmtsAtv1Cr 20604;
BA_ "SPN" SG_ 2565899006 PwrCnvrtr2RtLmtsAtv1Cntr 20605;
BA_ "SPN" SG_ 2565899006 PwCvt2RtLtsAtvAstCtRtLt 20606;
BA_ "SPN" SG_ 2565899262 PwrCnvrtr2IsltnIntgrtCr 20633;
BA_ "SPN" SG_ 2565899262 PwrCnvrtr2IsltnIntgrtCntr 20634;
BA_ "SPN" SG_ 2565899262 PwCvt2DES1NtvTCsssGdVt 20635;
BA_ "SPN" SG_ 2565899262 PwCvt2HVtBsAtvIstTstStts 20636;
BA_ "SPN" SG_ 2565899262 PwCvt2HVtBsPssvIstTstStts 20637;
BA_ "SPN" SG_ 2565899262 PwCvt2HVtBsAtvIstTstRsts 20638;
BA_ "SPN" SG_ 2565899262 PwCvt2HVtBsPssvIstTstRsts 20639;
BA_ "SPN" SG_ 2565899518 PwrCnvrtr1IsltnIntgrtCr 20658;
BA_ "SPN" SG_ 2565899518 PwrCnvrtr1IsltnIntgrtCntr 20659;
BA_ "SPN" SG_ 2565899518 PwCvt1DES1NtvTCsssGdVt 20660;
BA_ "SPN" SG_ 2565899518 PwCvt1HVtBsAtvIstTstStts 20661;
BA_ "SPN" SG_ 2565899518 PwCvt1HVtBsPssvIstTstStts 20662;
BA_ "SPN" SG_ 2565899518 PwCvt1HVtBsAtvIstTstRsts 20663;
BA_ "SPN" SG_ 2565899518 PwCvt1HVtBsPssvIstTstRsts 20664;
